VERSION "2021.24.4"

NS_ :

BS_:

BU_: VEH CH Receiver X

BO_ 869 SCS_alertMatrix1: 8 VEH
 SG_ SCS_a001_hwDSPfault: 0|1@1+ (1,0) [0|0] "" X
 SG_ SCS_a002_hwIbatOC: 1|1@1+ (1,0) [0|0] "" X
 SG_ SCS_a003_hwCordOT: 2|1@1+ (1,0) [0|0] "" X
 SG_ SCS_a004_hwVbusOV: 3|1@1+ (1,0) [0|0] "" X
 SG_ SCS_a005_hwHVIL: 4|1@1+ (1,0) [0|0] "" X
 SG_ SCS_a006_hwWeld_V1: 5|1@1+ (1,0) [0|0] "" X
 SG_ SCS_a007_hwWeld_V2: 6|1@1+ (1,0) [0|0] "" X
 SG_ SCS_a008_hwOpen_V1: 7|1@1+ (1,0) [0|0] "" X
 SG_ SCS_a009_hwOpen_V2: 8|1@1+ (1,0) [0|0] "" X
 SG_ SCS_a010_hwIllegalCntrCmdV1: 9|1@1+ (1,0) [0|0] "" X
 SG_ SCS_a011_hwIllegalCntrCmdInt: 10|1@1+ (1,0) [0|0] "" X
 SG_ SCS_a012_hwIllegalCntrCmdV2: 11|1@1+ (1,0) [0|0] "" X
 SG_ SCS_a013_cordTempHiFoldBk: 12|1@1+ (1,0) [0|0] "" X
 SG_ SCS_a014_coolantTempHiFoldBk: 13|1@1+ (1,0) [0|0] "" X
 SG_ SCS_a015_unusedHW15: 14|1@1+ (1,0) [0|0] "" X
 SG_ SCS_a016_unusedHW16: 15|1@1+ (1,0) [0|0] "" X
 SG_ SCS_a017_unusedHW17: 16|1@1+ (1,0) [0|0] "" X
 SG_ SCS_a018_unusedHW18: 17|1@1+ (1,0) [0|0] "" X
 SG_ SCS_a019_unusedHW19: 18|1@1+ (1,0) [0|0] "" X
 SG_ SCS_a020_unusedHW20: 19|1@1+ (1,0) [0|0] "" X
 SG_ SCS_a021_unusedHW21: 20|1@1+ (1,0) [0|0] "" X
 SG_ SCS_a022_fastChargeLimitActiveV1: 21|1@1+ (1,0) [0|0] "" X
 SG_ SCS_a023_fastChargeLimitActiveV2: 22|1@1+ (1,0) [0|0] "" X
 SG_ SCS_a024_emergencyShutdown: 23|1@1+ (1,0) [0|0] "" X
 SG_ SCS_a025_internalIsolationFault: 24|1@1+ (1,0) [0|0] "" X
 SG_ SCS_a026_internalIsolationLow: 25|1@1+ (1,0) [0|0] "" X
 SG_ SCS_a027_externalIsolationLow: 26|1@1+ (1,0) [0|0] "" X
 SG_ SCS_a028_isolationRationality: 27|1@1+ (1,0) [0|0] "" X
 SG_ SCS_a029_VbatOV: 28|1@1+ (1,0) [0|0] "" X
 SG_ SCS_a030_VbusOV: 29|1@1+ (1,0) [0|0] "" X
 SG_ SCS_a031_IbatOC: 30|1@1+ (1,0) [0|0] "" X
 SG_ SCS_a032_VBatRationality: 31|1@1+ (1,0) [0|0] "" X
 SG_ SCS_a033_VBusRationality: 32|1@1+ (1,0) [0|0] "" X
 SG_ SCS_a034_IBatRationality: 33|1@1+ (1,0) [0|0] "" X
 SG_ SCS_a035_unexpectedVbusBehavior: 34|1@1+ (1,0) [0|0] "" X
 SG_ SCS_a036_internalContactorWelded: 35|1@1+ (1,0) [0|0] "" X
 SG_ SCS_a037_outputContactorWelded: 36|1@1+ (1,0) [0|0] "" X
 SG_ SCS_a038_contactorFailedOpen: 37|1@1+ (1,0) [0|0] "" X
 SG_ SCS_a039_ibatRegulation: 38|1@1+ (1,0) [0|0] "" X
 SG_ SCS_a040_plus12VOutOfRange: 39|1@1+ (1,0) [0|0] "" X
 SG_ SCS_a041_minus12VOutOfRange: 40|1@1+ (1,0) [0|0] "" X
 SG_ SCS_a042_pilotOutOfRange: 41|1@1+ (1,0) [0|0] "" X
 SG_ SCS_a043_pilotRationality: 42|1@1+ (1,0) [0|0] "" X
 SG_ SCS_a044_proximityRationality: 43|1@1+ (1,0) [0|0] "" X
 SG_ SCS_a045_pcbaOT: 44|1@1+ (1,0) [0|0] "" X
 SG_ SCS_a046_coolantOT: 45|1@1+ (1,0) [0|0] "" X
 SG_ SCS_a047_cordOT: 46|1@1+ (1,0) [0|0] "" X
 SG_ SCS_a048_ambientOT: 47|1@1+ (1,0) [0|0] "" X
 SG_ SCS_a049_pcbaTempRationality: 48|1@1+ (1,0) [0|0] "" X
 SG_ SCS_a050_coolantTempRationality: 49|1@1+ (1,0) [0|0] "" X
 SG_ SCS_a051_cordTempRationality: 50|1@1+ (1,0) [0|0] "" X
 SG_ SCS_a052_ambientTempRationality: 51|1@1+ (1,0) [0|0] "" X
 SG_ SCS_a053_unexpectedThermalBehavi: 52|1@1+ (1,0) [0|0] "" X
 SG_ SCS_a054_pumpRegulation: 53|1@1+ (1,0) [0|0] "" X
 SG_ SCS_a055_coolantLevelLow: 54|1@1+ (1,0) [0|0] "" X
 SG_ SCS_a056_stateTransitionDenied: 55|1@1+ (1,0) [0|0] "" X
 SG_ SCS_a057_watchdogReset: 56|1@1+ (1,0) [0|0] "" X
 SG_ SCS_a058_adcRef: 57|1@1+ (1,0) [0|0] "" X
 SG_ SCS_a059_memoryError: 58|1@1+ (1,0) [0|0] "" X
 SG_ SCS_a060_swHVIL: 59|1@1+ (1,0) [0|0] "" X
 SG_ SCS_a061_postOutOfService: 60|1@1+ (1,0) [0|0] "" X
 SG_ SCS_a062_unused: 61|1@1+ (1,0) [0|0] "" X
 SG_ SCS_a063_canRationality: 62|1@1+ (1,0) [0|0] "" X
 SG_ SCS_a064_vehicleCommandTimeout: 63|1@1+ (1,0) [0|0] "" X

BO_ 880 SCS_alertMatrix2: 8 CH
 SG_ SCS_a065_vBatRationalityStage1: 0|1@1+ (1,0) [0|0] "" X
 SG_ SCS_a066_vBatRationalityStage2: 1|1@1+ (1,0) [0|0] "" X
 SG_ SCS_a067_vBatRationalityStage3: 2|1@1+ (1,0) [0|0] "" X
 SG_ SCS_a068_vBatRationalityStage4: 3|1@1+ (1,0) [0|0] "" X
 SG_ SCS_a069_vStageRationalityV1: 4|1@1+ (1,0) [0|0] "" X
 SG_ SCS_a070_vStageRationalityV2: 5|1@1+ (1,0) [0|0] "" X
 SG_ SCS_a071_chargerMIA: 6|1@1+ (1,0) [0|0] "" X
 SG_ SCS_a072_gtwMIA: 7|1@1+ (1,0) [0|0] "" X
 SG_ SCS_a073_lccMIA: 8|1@1+ (1,0) [0|0] "" X
 SG_ SCS_a074_isoVDiffHi: 9|1@1+ (1,0) [0|0] "" X
 SG_ SCS_a075_leakageTestAbsDecayLow: 10|1@1+ (1,0) [0|0] "" X
 SG_ SCS_a076_bmsMIA: 11|1@1+ (1,0) [0|0] "" X
 SG_ SCS_a077_unexpectedVbatBehavior: 12|1@1+ (1,0) [0|0] "" X
 SG_ SCS_a078_voltageMatchTimeout: 13|1@1+ (1,0) [0|0] "" X
 SG_ SCS_a079_unexpectedVbat: 14|1@1+ (1,0) [0|0] "" X
 SG_ SCS_a080_lccFaulted: 15|1@1+ (1,0) [0|0] "" X
 SG_ SCS_a081_rmsInputVoltageHigh: 16|1@1+ (1,0) [0|0] "" X
 SG_ SCS_a082_VbatUV: 17|1@1+ (1,0) [0|0] "" X
 SG_ SCS_a083_chargeCurrentLimited: 18|1@1+ (1,0) [0|0] "" X
 SG_ SCS_a084_unused84: 19|1@1+ (1,0) [0|0] "" X
 SG_ SCS_a085_unused85: 20|1@1+ (1,0) [0|0] "" X
 SG_ SCS_a086_lccResetDetected: 21|1@1+ (1,0) [0|0] "" X
 SG_ SCS_a087_posCordTempRationality: 22|1@1+ (1,0) [0|0] "" X
 SG_ SCS_a088_negCordTempRationality: 23|1@1+ (1,0) [0|0] "" X
 SG_ SCS_a089_posCordOT: 24|1@1+ (1,0) [0|0] "" X
 SG_ SCS_a090_negCordOT: 25|1@1+ (1,0) [0|0] "" X
 SG_ SCS_a091_voltageRiseDetection: 26|1@1+ (1,0) [0|0] "" X
 SG_ SCS_a092_cabEnableDeasserted: 27|1@1+ (1,0) [0|0] "" X
 SG_ SCS_a093_unused93: 28|1@1+ (1,0) [0|0] "" X
 SG_ SCS_a094_unused94: 29|1@1+ (1,0) [0|0] "" X
 SG_ SCS_a095_unused95: 30|1@1+ (1,0) [0|0] "" X
 SG_ SCS_a096_unused96: 31|1@1+ (1,0) [0|0] "" X
 SG_ SCS_a097_unused97: 32|1@1+ (1,0) [0|0] "" X
 SG_ SCS_a098_unused98: 33|1@1+ (1,0) [0|0] "" X
 SG_ SCS_a099_unused99: 34|1@1+ (1,0) [0|0] "" X
 SG_ SCS_a100_unused100: 35|1@1+ (1,0) [0|0] "" X
 SG_ SCS_a101_unused101: 36|1@1+ (1,0) [0|0] "" X
 SG_ SCS_a102_unused102: 37|1@1+ (1,0) [0|0] "" X
 SG_ SCS_a103_unused103: 38|1@1+ (1,0) [0|0] "" X
 SG_ SCS_a104_unused104: 39|1@1+ (1,0) [0|0] "" X
 SG_ SCS_a105_unused105: 40|1@1+ (1,0) [0|0] "" X
 SG_ SCS_a106_unused106: 41|1@1+ (1,0) [0|0] "" X
 SG_ SCS_a107_unused107: 42|1@1+ (1,0) [0|0] "" X
 SG_ SCS_a108_unused108: 43|1@1+ (1,0) [0|0] "" X
 SG_ SCS_a109_unused109: 44|1@1+ (1,0) [0|0] "" X
 SG_ SCS_a110_unused110: 45|1@1+ (1,0) [0|0] "" X
 SG_ SCS_a111_unused111: 46|1@1+ (1,0) [0|0] "" X
 SG_ SCS_a112_unused112: 47|1@1+ (1,0) [0|0] "" X
 SG_ SCS_a113_unused113: 48|1@1+ (1,0) [0|0] "" X
 SG_ SCS_a114_unused114: 49|1@1+ (1,0) [0|0] "" X
 SG_ SCS_a115_unused115: 50|1@1+ (1,0) [0|0] "" X
 SG_ SCS_a116_unused116: 51|1@1+ (1,0) [0|0] "" X
 SG_ SCS_a117_unused117: 52|1@1+ (1,0) [0|0] "" X
 SG_ SCS_a118_unused118: 53|1@1+ (1,0) [0|0] "" X
 SG_ SCS_a119_unused119: 54|1@1+ (1,0) [0|0] "" X
 SG_ SCS_a120_unused120: 55|1@1+ (1,0) [0|0] "" X
 SG_ SCS_a121_unused121: 56|1@1+ (1,0) [0|0] "" X
 SG_ SCS_a122_unused122: 57|1@1+ (1,0) [0|0] "" X
 SG_ SCS_a123_unused123: 58|1@1+ (1,0) [0|0] "" X
 SG_ SCS_a124_unused124: 59|1@1+ (1,0) [0|0] "" X
 SG_ SCS_a125_unused125: 60|1@1+ (1,0) [0|0] "" X
 SG_ SCS_a126_unused126: 61|1@1+ (1,0) [0|0] "" X
 SG_ SCS_a127_unused127: 62|1@1+ (1,0) [0|0] "" X
 SG_ SCS_a128_unused128: 63|1@1+ (1,0) [0|0] "" X

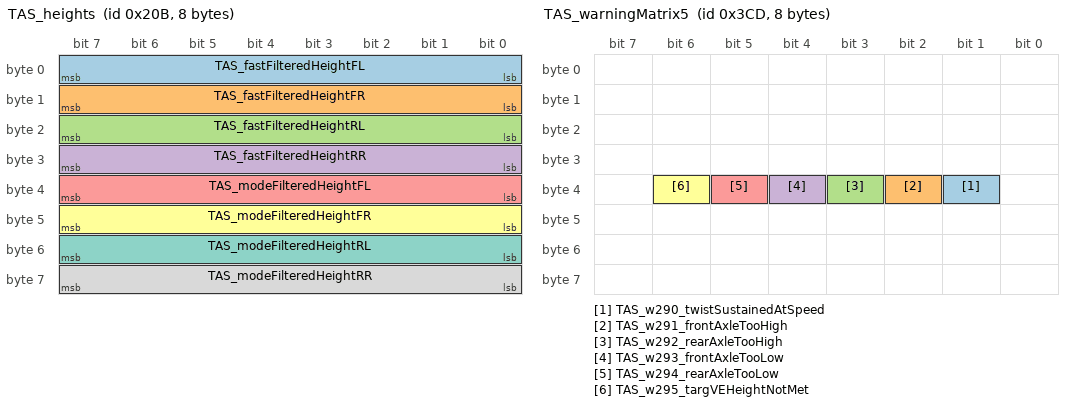
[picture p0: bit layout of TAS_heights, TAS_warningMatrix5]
BO_ 523 TAS_heights: 8 VEH
 SG_ TAS_fastFilteredHeightFL: 0|8@1+ (1,-128) [0|0] "mm" X
 SG_ TAS_fastFilteredHeightFR: 8|8@1+ (1,-128) [0|0] "mm" X
 SG_ TAS_fastFilteredHeightRL: 16|8@1+ (1,-128) [0|0] "mm" X
 SG_ TAS_fastFilteredHeightRR: 24|8@1+ (1,-128) [0|0] "mm" X
 SG_ TAS_modeFilteredHeightFL: 32|8@1+ (1,-128) [0|0] "mm" X
 SG_ TAS_modeFilteredHeightFR: 40|8@1+ (1,-128) [0|0] "mm" X
 SG_ TAS_modeFilteredHeightRL: 48|8@1+ (1,-128) [0|0] "mm" X
 SG_ TAS_modeFilteredHeightRR: 56|8@1+ (1,-128) [0|0] "mm" X

BO_ 1357 TAS_info: 8 VEH
 SG_ TAS_infoIndex M: 0|8@1+ (1,0) [0|0] "" X
 SG_ TAS_infoBuildType m10: 8|3@1+ (1,0) [0|0] "" X
 SG_ TAS_infoBuildConfigId m10: 16|16@1+ (1,0) [0|0] "" X
 SG_ TAS_infoHardwareId m10: 32|1@1+ (1,0) [0|0] "" X
 SG_ TAS_infoComponentId m10: 48|16@1+ (1,0) [0|0] "" X
 SG_ TAS_infoPcbaId m11: 16|8@1+ (1,0) [0|0] "" X
 SG_ TAS_infoAssemblyId m11: 24|8@1+ (1,0) [0|0] "" X
 SG_ TAS_infoUsageId m11: 32|16@1+ (1,0) [0|0] "" X
 SG_ TAS_infoSubUsageId m11: 48|16@1+ (1,0) [0|0] "" X
 SG_ TAS_infoAppCrc m13: 32|32@1+ (1,0) [0|0] "" X
 SG_ TAS_infoBootloaderSvnRevision m14: 8|24@1+ (1,0) [0|0] "" X
 SG_ TAS_infoAppGitHash m17: 10|54@1+ (4,0) [0|0] "" X
 SG_ TAS_infoBootGitHash m18: 10|54@1+ (4,0) [0|0] "" X
 SG_ TAS_infoPlatformType m19: 8|8@1+ (1,0) [0|0] "" X
 SG_ TAS_infoMajorVersion m19: 16|8@1+ (1,0) [0|0] "" X
 SG_ TAS_infoBranchOrigin m19: 24|8@1+ (1,0) [0|0] "" X
 SG_ TAS_infoMaturity m19: 32|8@1+ (1,0) [0|0] "" X
 SG_ TAS_infoHardwareRevision m19: 40|8@1+ (1,0) [0|0] "" X
 SG_ TAS_infoBootUdsProtoVersion m20: 8|8@1+ (1,0) [0|0] "" X
 SG_ TAS_infoBootCrc m20: 32|32@1+ (1,0) [0|0] "" X

BO_ 525 TAS_states: 8 VEH
 SG_ TAS_compressorRun: 30|1@1+ (1,0) [0|0] "" X
 SG_ TAS_currentLevel: 42|3@1+ (1,0) [0|0] "" X
 SG_ TAS_filterMode: 27|3@1+ (1,0) [0|0] "" X
 SG_ TAS_highAllowed: 36|1@1+ (1,0) [0|0] "" X
 SG_ TAS_jackMode: 38|1@1+ (1,0) [0|0] "" X
 SG_ TAS_leanDetected: 32|1@1+ (1,0) [0|0] "" X
 SG_ TAS_levelingState: 0|4@1+ (1,0) [0|0] "" X
 SG_ TAS_levelingType: 4|4@1+ (1,0) [0|0] "" X
 SG_ TAS_limpHomeMode: 48|3@1+ (1,0) [0|0] "" X
 SG_ TAS_lowAllowed: 34|1@1+ (1,0) [0|0] "" X
 SG_ TAS_pressureGallery: 8|8@1+ (0.1,0) [0|0] "bar" X
 SG_ TAS_pressureReservoir: 16|8@1+ (0.1,0) [0|0] "bar" X
 SG_ TAS_redWarningLamp: 40|1@1+ (1,0) [0|0] "" X
 SG_ TAS_runMode: 24|3@1+ (1,0) [0|0] "" X
 SG_ TAS_spinnerUI: 41|1@1+ (1,0) [0|0] "" X
 SG_ TAS_standardAllowed: 35|1@1+ (1,0) [0|0] "" X
 SG_ TAS_statesChecksum: 56|8@1+ (1,0) [0|0] "" X
 SG_ TAS_statesCounter: 52|4@1+ (1,0) [0|0] "" X
 SG_ TAS_targetLevel: 45|3@1+ (1,0) [0|0] "" X
 SG_ TAS_twistDetected: 31|1@1+ (1,0) [0|0] "" X
 SG_ TAS_veryHighAllowed: 37|1@1+ (1,0) [0|0] "" X
 SG_ TAS_veryLowAllowed: 33|1@1+ (1,0) [0|0] "" X
 SG_ TAS_yellowWarningLamp: 39|1@1+ (1,0) [0|0] "" X

BO_ 845 TAS_warningMatrix1: 8 VEH
 SG_ TAS_w001_WatchdogReset: 0|1@1+ (1,0) [0|0] "" X
 SG_ TAS_w002_PowerLossReset: 1|1@1+ (1,0) [0|0] "" X
 SG_ TAS_w003_SWAssertion: 2|1@1+ (1,0) [0|0] "" X
 SG_ TAS_w004_CANMIA: 3|1@1+ (1,0) [0|0] "" X
 SG_ TAS_w005_CANHighError: 4|1@1+ (1,0) [0|0] "" X
 SG_ TAS_w006_CANLowError: 5|1@1+ (1,0) [0|0] "" X
 SG_ TAS_w007_LINTimeout: 6|1@1+ (1,0) [0|0] "" X
 SG_ TAS_w008_LIN2Error: 7|1@1+ (1,0) [0|0] "" X
 SG_ TAS_w009_LIN3Error: 8|1@1+ (1,0) [0|0] "" X
 SG_ TAS_w010_ExtSupplyVoltError: 9|1@1+ (1,0) [0|0] "" X
 SG_ TAS_w011_ECUSupplyVoltError: 10|1@1+ (1,0) [0|0] "" X
 SG_ TAS_w012_CPUReset: 11|1@1+ (1,0) [0|0] "" X
 SG_ TAS_w013_Shared13: 12|1@1+ (1,0) [0|0] "" X
 SG_ TAS_w014_BridgeFault: 13|1@1+ (1,0) [0|0] "" X
 SG_ TAS_w015_NVMMAlert: 14|1@1+ (1,0) [0|0] "" X
 SG_ TAS_w016_MessageTimingError: 15|1@1+ (1,0) [0|0] "" X
 SG_ TAS_w017_AwakeForTooLong: 16|1@1+ (1,0) [0|0] "" X
 SG_ TAS_w018_ADCError: 17|1@1+ (1,0) [0|0] "" X
 SG_ TAS_w019_I2CError: 18|1@1+ (1,0) [0|0] "" X
 SG_ TAS_w020_PWMError: 19|1@1+ (1,0) [0|0] "" X
 SG_ TAS_w021_TaskSchedulerError: 20|1@1+ (1,0) [0|0] "" X
 SG_ TAS_w022_TaskInitError: 21|1@1+ (1,0) [0|0] "" X
 SG_ TAS_w023_SleepError: 22|1@1+ (1,0) [0|0] "" X
 SG_ TAS_w024_WakeError: 23|1@1+ (1,0) [0|0] "" X
 SG_ TAS_w025_CrashEvent: 24|1@1+ (1,0) [0|0] "" X
 SG_ TAS_w026_FlashMemoryError: 25|1@1+ (1,0) [0|0] "" X
 SG_ TAS_w027_NVRAMCorruption: 26|1@1+ (1,0) [0|0] "" X
 SG_ TAS_w028_NVRAMNotResponding: 27|1@1+ (1,0) [0|0] "" X
 SG_ TAS_w029_NVRAMUninitialized: 28|1@1+ (1,0) [0|0] "" X
 SG_ TAS_w030_PWMerrorFL: 29|1@1+ (1,0) [0|0] "" X
 SG_ TAS_w031_PWMerrorFR: 30|1@1+ (1,0) [0|0] "" X
 SG_ TAS_w032_PWMerrorRL: 31|1@1+ (1,0) [0|0] "" X
 SG_ TAS_w033_PWMerrorRR: 32|1@1+ (1,0) [0|0] "" X
 SG_ TAS_w034_PWMshortFL: 33|1@1+ (1,0) [0|0] "" X
 SG_ TAS_w035_PWMshortFR: 34|1@1+ (1,0) [0|0] "" X
 SG_ TAS_w036_PWMshortRL: 35|1@1+ (1,0) [0|0] "" X
 SG_ TAS_w037_PWMshortRR: 36|1@1+ (1,0) [0|0] "" X
 SG_ TAS_w038_PWMopenFL: 37|1@1+ (1,0) [0|0] "" X
 SG_ TAS_w039_PWMopenFR: 38|1@1+ (1,0) [0|0] "" X
 SG_ TAS_w040_PWMopenRL: 39|1@1+ (1,0) [0|0] "" X
 SG_ TAS_w041_PWMopenRR: 40|1@1+ (1,0) [0|0] "" X

BO_ 877 TAS_warningMatrix2: 8 VEH
 SG_ TAS_w070_lowVoltage12V: 5|1@1+ (1,0) [0|0] "" X
 SG_ TAS_w071_highVoltage12V: 6|1@1+ (1,0) [0|0] "" X
 SG_ TAS_w072_shortCircuit5VS0: 7|1@1+ (1,0) [0|0] "" X
 SG_ TAS_w073_lowVoltage5VS0: 8|1@1+ (1,0) [0|0] "" X
 SG_ TAS_w074_shortCircuit5VS1: 9|1@1+ (1,0) [0|0] "" X
 SG_ TAS_w075_lowVoltage5VS1: 10|1@1+ (1,0) [0|0] "" X
 SG_ TAS_w076_highVoltage5VS1: 11|1@1+ (1,0) [0|0] "" X
 SG_ TAS_w077_pressureSigVTooLow: 12|1@1+ (1,0) [0|0] "" X
 SG_ TAS_w078_pressureSigVTooHigh: 13|1@1+ (1,0) [0|0] "" X
 SG_ TAS_w079_DvrSideCfgMismatch: 14|1@1+ (1,0) [0|0] "" X
 SG_ TAS_w080_pressureRefVTooLow: 15|1@1+ (1,0) [0|0] "" X
 SG_ TAS_w093_OTPError: 28|1@1+ (1,0) [0|0] "" X
 SG_ TAS_w098_VCFRONT_MIA: 33|1@1+ (1,0) [0|0] "" X
 SG_ TAS_w099_UI_MIA: 34|1@1+ (1,0) [0|0] "" X
 SG_ TAS_w100_RCM_MIA: 35|1@1+ (1,0) [0|0] "" X
 SG_ TAS_w101_ESP_MIA: 36|1@1+ (1,0) [0|0] "" X
 SG_ TAS_w102_DI_MIA: 37|1@1+ (1,0) [0|0] "" X
 SG_ TAS_w103_GTW_MIA: 38|1@1+ (1,0) [0|0] "" X
 SG_ TAS_w105_ECUDebugMode: 40|1@1+ (1,0) [0|0] "" X
 SG_ TAS_w106_HighCPULoad: 41|1@1+ (1,0) [0|0] "" X
 SG_ TAS_w107_HighStackUsage: 42|1@1+ (1,0) [0|0] "" X
 SG_ TAS_w121_maxDutyFL: 56|1@1+ (1,0) [0|0] "" X
 SG_ TAS_w122_maxDutyFR: 57|1@1+ (1,0) [0|0] "" X
 SG_ TAS_w123_maxDutyRL: 58|1@1+ (1,0) [0|0] "" X
 SG_ TAS_w124_maxDutyRR: 59|1@1+ (1,0) [0|0] "" X
 SG_ TAS_w125_maxDutyReservoir: 60|1@1+ (1,0) [0|0] "" X
 SG_ TAS_w126_maxDutyExhaust: 61|1@1+ (1,0) [0|0] "" X
 SG_ TAS_w127_maxDutyBoost: 62|1@1+ (1,0) [0|0] "" X
 SG_ TAS_w128_maxDutyCompressor: 63|1@1+ (1,0) [0|0] "" X

BO_ 909 TAS_warningMatrix3: 8 VEH
 SG_ TAS_w129_openCircuitFL: 0|1@1+ (1,0) [0|0] "" X
 SG_ TAS_w130_openCircuitFR: 1|1@1+ (1,0) [0|0] "" X
 SG_ TAS_w131_openCircuitRL: 2|1@1+ (1,0) [0|0] "" X
 SG_ TAS_w132_openCircuitRR: 3|1@1+ (1,0) [0|0] "" X
 SG_ TAS_w133_openCircuitReservoir: 4|1@1+ (1,0) [0|0] "" X
 SG_ TAS_w134_openCircuitExhaust: 5|1@1+ (1,0) [0|0] "" X
 SG_ TAS_w135_openCircuitBoost: 6|1@1+ (1,0) [0|0] "" X
 SG_ TAS_w136_openCircuitCompressor: 7|1@1+ (1,0) [0|0] "" X
 SG_ TAS_w137_shortCircuitFL: 8|1@1+ (1,0) [0|0] "" X
 SG_ TAS_w138_shortCircuitFR: 9|1@1+ (1,0) [0|0] "" X
 SG_ TAS_w139_shortCircuitRL: 10|1@1+ (1,0) [0|0] "" X
 SG_ TAS_w140_shortCircuitRR: 11|1@1+ (1,0) [0|0] "" X
 SG_ TAS_w141_shortCircuitReservoir: 12|1@1+ (1,0) [0|0] "" X
 SG_ TAS_w142_shortCircuitExhaust: 13|1@1+ (1,0) [0|0] "" X
 SG_ TAS_w143_shortCircuitBoost: 14|1@1+ (1,0) [0|0] "" X
 SG_ TAS_w144_shortCircuitCompressor: 15|1@1+ (1,0) [0|0] "" X
 SG_ TAS_w145_boardFaultFL: 16|1@1+ (1,0) [0|0] "" X
 SG_ TAS_w146_boardFaultFR: 17|1@1+ (1,0) [0|0] "" X
 SG_ TAS_w147_boardFaultRL: 18|1@1+ (1,0) [0|0] "" X
 SG_ TAS_w148_boardFaultRR: 19|1@1+ (1,0) [0|0] "" X
 SG_ TAS_w149_boardFaultReservoir: 20|1@1+ (1,0) [0|0] "" X
 SG_ TAS_w150_boardFaultExhaust: 21|1@1+ (1,0) [0|0] "" X
 SG_ TAS_w151_boardFaultBoost: 22|1@1+ (1,0) [0|0] "" X
 SG_ TAS_w152_boardFaultCompressor: 23|1@1+ (1,0) [0|0] "" X
 SG_ TAS_w153_otherCircuitFL: 24|1@1+ (1,0) [0|0] "" X
 SG_ TAS_w154_otherCircuitFR: 25|1@1+ (1,0) [0|0] "" X
 SG_ TAS_w155_otherCircuitRL: 26|1@1+ (1,0) [0|0] "" X
 SG_ TAS_w156_otherCircuitRR: 27|1@1+ (1,0) [0|0] "" X
 SG_ TAS_w157_otherCircuitReservoir: 28|1@1+ (1,0) [0|0] "" X
 SG_ TAS_w158_otherCircuitExhaust: 29|1@1+ (1,0) [0|0] "" X
 SG_ TAS_w159_otherCircuitBoost: 30|1@1+ (1,0) [0|0] "" X
 SG_ TAS_w160_otherCircuitCompressor: 31|1@1+ (1,0) [0|0] "" X
 SG_ TAS_w161_valveBlockOpenGND: 32|1@1+ (1,0) [0|0] "" X
 SG_ TAS_w162_compressorValveOpenGND: 33|1@1+ (1,0) [0|0] "" X
 SG_ TAS_w163_reservoirFillDisabled: 34|1@1+ (1,0) [0|0] "" X
 SG_ TAS_w164_calibrationVersion: 35|1@1+ (1,0) [0|0] "" X

BO_ 941 TAS_warningMatrix4: 8 VEH
 SG_ TAS_w200_jackModeActive: 7|1@1+ (1,0) [0|0] "" X
 SG_ TAS_w201_lowHVBattery: 8|1@1+ (1,0) [0|0] "" X
 SG_ TAS_w210_outOfRangeCalibration: 17|1@1+ (1,0) [0|0] "" X
 SG_ TAS_w211_noRideHeightCalib: 18|1@1+ (1,0) [0|0] "" X
 SG_ TAS_w212_noCurrentSenseCalib: 19|1@1+ (1,0) [0|0] "" X
 SG_ TAS_w213_yellowWarningLamp: 20|1@1+ (1,0) [0|0] "" X
 SG_ TAS_w214_redWarningLamp: 21|1@1+ (1,0) [0|0] "" X
 SG_ TAS_w215_limpHomeMode10: 22|1@1+ (1,0) [0|0] "" X
 SG_ TAS_w216_limpHomeMode20: 23|1@1+ (1,0) [0|0] "" X
 SG_ TAS_w217_limpHomeMode30: 24|1@1+ (1,0) [0|0] "" X
 SG_ TAS_w218_limpHomeMode40: 25|1@1+ (1,0) [0|0] "" X
 SG_ TAS_w220_exhaustGalleryFault: 27|1@1+ (1,0) [0|0] "" X
 SG_ TAS_w221_valveLeakDetected: 28|1@1+ (1,0) [0|0] "" X
 SG_ TAS_w222_compressorPrefillFault: 29|1@1+ (1,0) [0|0] "" X
 SG_ TAS_w223_blockedAirline: 30|1@1+ (1,0) [0|0] "" X
 SG_ TAS_w224_openAirline: 31|1@1+ (1,0) [0|0] "" X
 SG_ TAS_w225_galleryPressureTooHigh: 32|1@1+ (1,0) [0|0] "" X
 SG_ TAS_w226_PWMfastDetectFL: 33|1@1+ (1,0) [0|0] "" X
 SG_ TAS_w227_PWMfastDetectFR: 34|1@1+ (1,0) [0|0] "" X
 SG_ TAS_w228_PWMfastDetectRL: 35|1@1+ (1,0) [0|0] "" X
 SG_ TAS_w229_PWMfastDetectRR: 36|1@1+ (1,0) [0|0] "" X

BO_ 973 TAS_warningMatrix5: 8 VEH
 SG_ TAS_w290_twistSustainedAtSpeed: 33|1@1+ (1,0) [0|0] "" X
 SG_ TAS_w291_frontAxleTooHigh: 34|1@1+ (1,0) [0|0] "" X
 SG_ TAS_w292_rearAxleTooHigh: 35|1@1+ (1,0) [0|0] "" X
 SG_ TAS_w293_frontAxleTooLow: 36|1@1+ (1,0) [0|0] "" X
 SG_ TAS_w294_rearAxleTooLow: 37|1@1+ (1,0) [0|0] "" X
 SG_ TAS_w295_targVEHeightNotMet: 38|1@1+ (1,0) [0|0] "" X

BO_ 879 TPMS_StatusC: 8 CH
 SG_ TPMS_WA_version: 3|1@1+ (1,0) [0|0] "" X
 SG_ TPMS_c_globalHardWarning: 0|1@1+ (1,0) [0|0] "" X
 SG_ TPMS_c_globalSoftWarning: 1|1@1+ (1,0) [0|0] "" X
 SG_ TPMS_deltaPressWarningFL: 20|1@1+ (1,0) [0|0] "" X
 SG_ TPMS_deltaPressWarningFR: 21|1@1+ (1,0) [0|0] "" X
 SG_ TPMS_deltaPressWarningRL: 22|1@1+ (1,0) [0|0] "" X
 SG_ TPMS_deltaPressWarningRR: 23|1@1+ (1,0) [0|0] "" X
 SG_ TPMS_ecuOverVoltage: 41|1@1+ (1,0) [0|0] "" X
 SG_ TPMS_ecuRamRomNvMFail: 42|1@1+ (1,0) [0|0] "" X
 SG_ TPMS_ecuUnderVoltage: 40|1@1+ (1,0) [0|0] "" X
 SG_ TPMS_eolNotCompleted: 47|1@1+ (1,0) [0|0] "" X
 SG_ TPMS_externalTemperatureFail: 46|1@1+ (1,0) [0|0] "" X
 SG_ TPMS_globalDeltaPressure: 4|1@1+ (1,0) [0|0] "" X
 SG_ TPMS_hardWarningFL: 15|1@1+ (1,0) [0|0] "" X
 SG_ TPMS_hardWarningFR: 13|1@1+ (1,0) [0|0] "" X
 SG_ TPMS_hardWarningRL: 11|1@1+ (1,0) [0|0] "" X
 SG_ TPMS_hardWarningRR: 9|1@1+ (1,0) [0|0] "" X
 SG_ TPMS_learningStatus: 16|2@1+ (1,0) [0|0] "" X
 SG_ TPMS_localisationStatus: 18|2@1+ (1,0) [0|0] "" X
 SG_ TPMS_newSensorLearnt: 5|3@1+ (1,0) [0|0] "" X
 SG_ TPMS_rcpFront: 48|8@1+ (0.025,0) [0|0] "bar" X
 SG_ TPMS_rcpRear: 56|8@1+ (0.025,0) [0|0] "bar" X
 SG_ TPMS_rfReceiverFail: 43|1@1+ (1,0) [0|0] "" X
 SG_ TPMS_sensorBatteryLowFL: 32|1@1+ (1,0) [0|0] "" X
 SG_ TPMS_sensorBatteryLowFR: 33|1@1+ (1,0) [0|0] "" X
 SG_ TPMS_sensorBatteryLowRL: 34|1@1+ (1,0) [0|0] "" X
 SG_ TPMS_sensorBatteryLowRR: 35|1@1+ (1,0) [0|0] "" X
 SG_ TPMS_sensorDefectiveFL: 36|1@1+ (1,0) [0|0] "" X
 SG_ TPMS_sensorDefectiveFR: 37|1@1+ (1,0) [0|0] "" X
 SG_ TPMS_sensorDefectiveRL: 38|1@1+ (1,0) [0|0] "" X
 SG_ TPMS_sensorDefectiveRR: 39|1@1+ (1,0) [0|0] "" X
 SG_ TPMS_sensorNoResponseFL: 24|1@1+ (1,0) [0|0] "" X
 SG_ TPMS_sensorNoResponseFR: 25|1@1+ (1,0) [0|0] "" X
 SG_ TPMS_sensorNoResponseRL: 26|1@1+ (1,0) [0|0] "" X
 SG_ TPMS_sensorNoResponseRR: 27|1@1+ (1,0) [0|0] "" X
 SG_ TPMS_sensorThermShutdownFL: 28|1@1+ (1,0) [0|0] "" X
 SG_ TPMS_sensorThermShutdownFR: 29|1@1+ (1,0) [0|0] "" X
 SG_ TPMS_sensorThermShutdownRL: 30|1@1+ (1,0) [0|0] "" X
 SG_ TPMS_sensorThermShutdownRR: 31|1@1+ (1,0) [0|0] "" X
 SG_ TPMS_softWarningFL: 14|1@1+ (1,0) [0|0] "" X
 SG_ TPMS_softWarningFR: 12|1@1+ (1,0) [0|0] "" X
 SG_ TPMS_softWarningRL: 10|1@1+ (1,0) [0|0] "" X
 SG_ TPMS_softWarningRR: 8|1@1+ (1,0) [0|0] "" X
 SG_ TPMS_systemMalfunction: 2|1@1+ (1,0) [0|0] "" X
 SG_ TPMS_vehicleSpeedFail: 45|1@1+ (1,0) [0|0] "" X
 SG_ TPMS_wheelPulseMissing: 44|1@1+ (1,0) [0|0] "" X

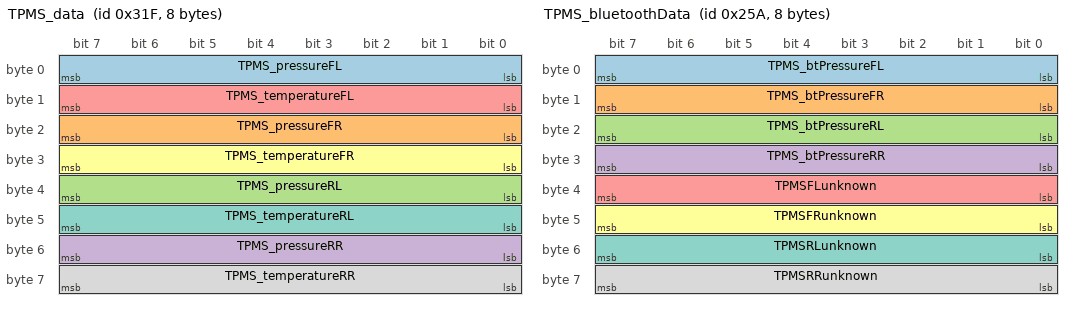
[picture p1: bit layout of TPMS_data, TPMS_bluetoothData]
BO_ 799 TPMS_data: 8 CH
 SG_ TPMS_pressureFL: 0|8@1+ (0.025,0) [0|0] "bar" X
 SG_ TPMS_pressureFR: 16|8@1+ (0.025,0) [0|0] "bar" X
 SG_ TPMS_pressureRL: 32|8@1+ (0.025,0) [0|0] "bar" X
 SG_ TPMS_pressureRR: 48|8@1+ (0.025,0) [0|0] "bar" X
 SG_ TPMS_temperatureFL: 8|8@1+ (1,-40) [0|0] "degC" X
 SG_ TPMS_temperatureFR: 24|8@1+ (1,-40) [0|0] "degC" X
 SG_ TPMS_temperatureRL: 40|8@1+ (1,-40) [0|0] "degC" X
 SG_ TPMS_temperatureRR: 56|8@1+ (1,-40) [0|0] "degC" X

BO_ 602 TPMS_bluetoothData: 8 CH
SG_ TPMS_btPressureFL : 0|8@1+ (0.025,0) [0|6.375] "bar" X
SG_ TPMS_btPressureFR : 8|8@1+ (0.025,0) [0|6.375] "bar" X
SG_ TPMS_btPressureRL : 16|8@1+ (0.025,0) [0|6.375] "bar" X
SG_ TPMS_btPressureRR : 24|8@1+ (0.025,0) [0|6.375] "bar" X
SG_ TPMSFLunknown : 32|8@1+ (1,0) [0|0] "" X
SG_ TPMSFRunknown : 40|8@1+ (1,0) [0|0] "" X
SG_ TPMSRLunknown : 48|8@1+ (1,0) [0|0] "" X
SG_ TPMSRRunknown : 56|8@1+ (1,0) [0|0] "" X

BO_ 1519 TPMS_info: 8 CH
 SG_ TPMS_infoIndex M: 0|8@1+ (1,0) [0|0] "" X
 SG_ TPMS_infoComponentID m10: 48|16@1+ (1,0) [0|0] "" X
 SG_ TPMS_infoPcbaID m11: 16|8@1+ (1,0) [0|0] "" X
 SG_ TPMS_infoAssemblyID m11: 24|8@1+ (1,0) [0|0] "" X
 SG_ TPMS_infoUsageID m11: 32|16@1+ (1,0) [0|0] "" X
 SG_ TPMS_infoBootUdsProtoVersion m20: 8|8@1+ (1,0) [0|0] "" X
 SG_ TPMS_infoBootloaderCRC m20: 32|32@1+ (1,0) [0|0] "" X
 SG_ TPMS_infoApplicationCRC m13: 32|32@1+ (1,0) [0|0] "" X

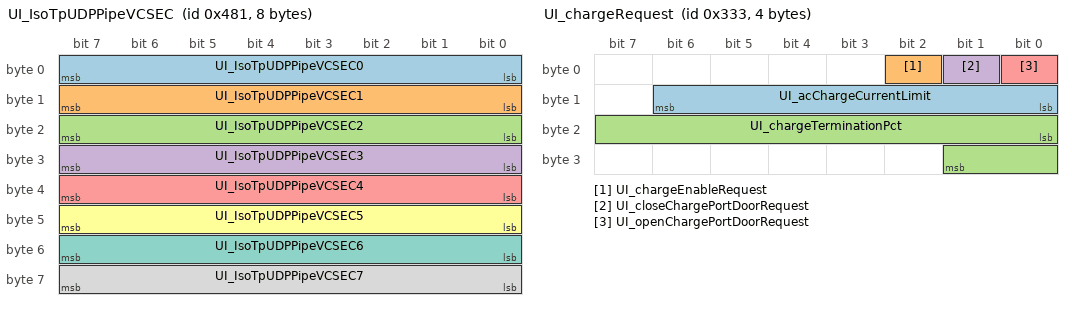
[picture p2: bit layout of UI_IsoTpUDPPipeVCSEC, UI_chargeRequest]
BO_ 1153 UI_IsoTpUDPPipeVCSEC: 8 VEH
 SG_ UI_IsoTpUDPPipeVCSEC0: 0|8@1+ (1,0) [0|0] "" X
 SG_ UI_IsoTpUDPPipeVCSEC1: 8|8@1+ (1,0) [0|0] "" X
 SG_ UI_IsoTpUDPPipeVCSEC2: 16|8@1+ (1,0) [0|0] "" X
 SG_ UI_IsoTpUDPPipeVCSEC3: 24|8@1+ (1,0) [0|0] "" X
 SG_ UI_IsoTpUDPPipeVCSEC4: 32|8@1+ (1,0) [0|0] "" X
 SG_ UI_IsoTpUDPPipeVCSEC5: 40|8@1+ (1,0) [0|0] "" X
 SG_ UI_IsoTpUDPPipeVCSEC6: 48|8@1+ (1,0) [0|0] "" X
 SG_ UI_IsoTpUDPPipeVCSEC7: 56|8@1+ (1,0) [0|0] "" X

BO_ 979 UI_airbagCutoffStatus: 1 VEH
 SG_ UI_airbagCutoffSwState: 0|2@1+ (1,0) [0|0] "" X
 SG_ UI_warningIndicatorStatus: 2|2@1+ (1,0) [0|0] "" X

BO_ 1523 UI_alertLog: 8 VEH
 SG_ UI_alertID M: 0|6@1+ (1,0) [0|0] "" X
 SG_ UI_alertState: 15|1@1+ (1,0) [0|0] "" X
 SG_ UI_a034_BackupCamera m34: 16|1@1+ (1,0) [0|0] "" X
 SG_ UI_a034_Tuner m34: 17|1@1+ (1,0) [0|0] "" X
 SG_ UI_a034_Bluetooth m34: 18|1@1+ (1,0) [0|0] "" X
 SG_ UI_a034_WiFi m34: 19|1@1+ (1,0) [0|0] "" X
 SG_ UI_a034_Cellular m34: 20|1@1+ (1,0) [0|0] "" X
 SG_ UI_a034_TouchScreen m34: 21|1@1+ (1,0) [0|0] "" X
 SG_ UI_a034_Display m34: 22|1@1+ (1,0) [0|0] "" X
 SG_ UI_a034_Audio m34: 23|1@1+ (1,0) [0|0] "" X
 SG_ UI_a034_FatalWakeup m34: 24|1@1+ (1,0) [0|0] "" X
 SG_ UI_a034_UnknownWakeupError m34: 25|1@1+ (1,0) [0|0] "" X
 SG_ UI_a006_remoteServiceAlertCode m6: 16|32@1+ (1,0) [0|0] "" X

BO_ 291 UI_alertMatrix1: 8 VEH
 SG_ UI_a001_DriverDoorOpen: 0|1@1+ (1,0) [0|0] "" X
 SG_ UI_a002_DoorOpen: 1|1@1+ (1,0) [0|0] "" X
 SG_ UI_a003_TrunkOpen: 2|1@1+ (1,0) [0|0] "" X
 SG_ UI_a004_FrunkOpen: 3|1@1+ (1,0) [0|0] "" X
 SG_ UI_a005_HeadlightsOnDoorOpen: 4|1@1+ (1,0) [0|0] "" X
 SG_ UI_a006_RemoteServiceAlert: 5|1@1+ (1,0) [0|0] "" X
 SG_ UI_a007_SoftPackConfigMismatch: 6|1@1+ (1,0) [0|0] "" X
 SG_ UI_a008_TouchScreenError: 7|1@1+ (1,0) [0|0] "" X
 SG_ UI_a009_SquashfsError: 8|1@1+ (1,0) [0|0] "" X
 SG_ UI_a010_MapsMissing: 9|1@1+ (1,0) [0|0] "" X
 SG_ UI_a011_IncorrectMap: 10|1@1+ (1,0) [0|0] "" X
 SG_ UI_a012_NotOnPrivateProperty: 11|1@1+ (1,0) [0|0] "" X
 SG_ UI_a013_TPMSHardWarning: 12|1@1+ (1,0) [0|0] "" X
 SG_ UI_a014_TPMSSoftWarning: 13|1@1+ (1,0) [0|0] "" X
 SG_ UI_a015_TPMSOverPressureWarning: 14|1@1+ (1,0) [0|0] "" X
 SG_ UI_a016_TPMSTemperatureWarning: 15|1@1+ (1,0) [0|0] "" X
 SG_ UI_a017_TPMSSystemFault: 16|1@1+ (1,0) [0|0] "" X
 SG_ UI_a018_SlipStartOn: 17|1@1+ (1,0) [0|0] "" X
 SG_ UI_a019_ParkBrakeFault: 18|1@1+ (1,0) [0|0] "" X
 SG_ UI_a020_SteeringReduced: 19|1@1+ (1,0) [0|0] "" X
 SG_ UI_a021_RearSeatbeltUnbuckled: 20|1@1+ (1,0) [0|0] "" X
 SG_ UI_a022_ApeFusesEtc: 21|1@1+ (1,0) [0|0] "" X
 SG_ UI_a023_CellInternetCheckFailed: 22|1@1+ (1,0) [0|0] "" X
 SG_ UI_a024_WifiInternetCheckFailed: 23|1@1+ (1,0) [0|0] "" X
 SG_ UI_a025_WifiOnlineCheckFailed: 24|1@1+ (1,0) [0|0] "" X
 SG_ UI_a026_ModemResetLoopDetected: 25|1@1+ (1,0) [0|0] "" X
 SG_ UI_a027_AutoSteerMIA: 26|1@1+ (1,0) [0|0] "" X
 SG_ UI_a028_FrontTrunkPopupClosed: 27|1@1+ (1,0) [0|0] "" X
 SG_ UI_a029_ModemMIA: 28|1@1+ (1,0) [0|0] "" X
 SG_ UI_a030_ModemVMCrash: 29|1@1+ (1,0) [0|0] "" X
 SG_ UI_a031_BrakeFluidLow: 30|1@1+ (1,0) [0|0] "" X
 SG_ UI_a032_CellModemRecoveryResets: 31|1@1+ (1,0) [0|0] "" X
 SG_ UI_a033_ApTrialExpired: 32|1@1+ (1,0) [0|0] "" X
 SG_ UI_a034_WakeupProblem: 33|1@1+ (1,0) [0|0] "" X
 SG_ UI_a035_AudioWatchdogKernelError: 34|1@1+ (1,0) [0|0] "" X
 SG_ UI_a036_AudioWatchdogHfpError: 35|1@1+ (1,0) [0|0] "" X
 SG_ UI_a037_AudioWatchdogXrunStormError: 36|1@1+ (1,0) [0|0] "" X
 SG_ UI_a038_AudioWatchdogA2bI2cLockupError: 37|1@1+ (1,0) [0|0] "" X
 SG_ UI_a039_AudioA2bNeedRediscovery: 38|1@1+ (1,0) [0|0] "" X
 SG_ UI_a040_HomelinkTransmit: 39|1@1+ (1,0) [0|0] "" X
 SG_ UI_a041_AudioDmesgXrun: 40|1@1+ (1,0) [0|0] "" X
 SG_ UI_a042_AudioDmesgRtThrottling: 41|1@1+ (1,0) [0|0] "" X
 SG_ UI_a043_InvalidMapDataOverride: 42|1@1+ (1,0) [0|0] "" X
 SG_ UI_a044_AudioDmesgDspException: 43|1@1+ (1,0) [0|0] "" X

BO_ 1021 UI_autopilotControl: 8 CH
 SG_ UI_autopilotControlIndex M : 0|3@1+ (1,0) [0|7] "" X
 SG_ UI_apmv3Branch m1 : 40|3@1+ (1,0) [0|5] "" X
 SG_ UI_applyEceR79 m1 : 19|1@1+ (1,0) [0|1] "" X
 SG_ UI_blindspotDistance m0 : 15|3@1+ (1,0) [0|5] "" X
 SG_ UI_blindspotMinSpeed m0 : 11|4@1+ (1,0) [0|10] "" X
 SG_ UI_blindspotTTC m0 : 18|3@1+ (1,0) [0|7] "" X
 SG_ UI_disableBackup m1 : 30|1@1+ (1,0) [0|1] "" X
 SG_ UI_disableFisheye m1 : 25|1@1+ (1,0) [0|1] "" X
 SG_ UI_disableLeftPillar m1 : 26|1@1+ (1,0) [0|1] "" X
 SG_ UI_disableLeftRepeater m1 : 28|1@1+ (1,0) [0|1] "" X
 SG_ UI_disableMain m1 : 23|1@1+ (1,0) [0|1] "" X
 SG_ UI_disableNarrow m1 : 24|1@1+ (1,0) [0|1] "" X
 SG_ UI_disableRadar m1 : 31|1@1+ (1,0) [0|1] "" X
 SG_ UI_disableRightPillar m1 : 27|1@1+ (1,0) [0|1] "" X
 SG_ UI_disableRightRepeater m1 : 29|1@1+ (1,0) [0|1] "" X
 SG_ UI_donAlcProgGoreAbortThres m0 : 29|4@1+ (1,0) [0|9] "" X
 SG_ UI_donDisableAutoWiperDuration m0 : 4|3@1+ (1,0) [0|6] "" X
 SG_ UI_donDisableCutin m0 : 24|1@1+ (1,0) [0|1] "" X
 SG_ UI_donDisableOnAutoWiperSpeed m0 : 7|4@1+ (1,0) [0|15] "" X
 SG_ UI_donMinGoreWidthForAbortMap m0 : 25|4@1+ (1,0) [0|11] "" X
 SG_ UI_donMinGoreWidthForAbortNotMap m0 : 33|4@1+ (1,0) [0|11] "" X
 SG_ UI_donStopEndOfRampBuffer m0 : 21|3@1+ (1,0) [0|4] "" X
 SG_ UI_driverMonitorConfirmation m1 : 17|1@1+ (1,0) [0|1] "" X
 SG_ UI_enableAutopilotStopWarning m1 : 44|1@1+ (1,0) [0|1] "" X
 SG_ UI_enableCabinCamera m1 : 43|1@1+ (1,0) [0|1] "" X
 SG_ UI_enableCabinCameraTelemetry m1 : 48|1@1+ (1,0) [0|1] "" X
 SG_ UI_enableMapStops m1 : 20|1@1+ (1,0) [0|1] "" X
 SG_ UI_factorySummonEnable m1 : 39|1@1+ (1,0) [0|1] "" X
 SG_ UI_fsdStopsControlEnabled m0 : 38|1@1+ (1,0) [0|1] "" X
 SG_ UI_fsdVisualizationEnabled m0 : 37|1@1+ (1,0) [0|1] "" X
 SG_ UI_hardCoreSummon m1 : 47|1@1+ (1,0) [0|1] "" X
 SG_ UI_homelinkNearby m0 : 45|1@1+ (1,0) [0|1] "" X
 SG_ UI_hovEnabled m0 : 3|1@1+ (1,0) [0|1] "" X
 SG_ UI_noStalkConfirmAlertChime m1 : 37|1@1+ (1,0) [0|1] "" X
 SG_ UI_noStalkConfirmAlertHaptic m1 : 32|1@1+ (1,0) [0|1] "" X
 SG_ UI_showLaneGraph m1 : 45|1@1+ (1,0) [0|1] "" X
 SG_ UI_showTrackLabels m1 : 46|1@1+ (1,0) [0|1] "" X
 SG_ UI_ulcSnooze m1 : 36|1@1+ (1,0) [0|1] "" X

BO_ 819 UI_chargeRequest: 4 VEH
 SG_ UI_acChargeCurrentLimit: 8|7@1+ (1,0) [0|0] "A" X
 SG_ UI_chargeEnableRequest: 2|1@1+ (1,0) [0|0] "" X
 SG_ UI_chargeTerminationPct: 16|10@1+ (0.1,0) [0|0] "%" X
 SG_ UI_closeChargePortDoorRequest: 1|1@1+ (1,0) [0|0] "" X
 SG_ UI_openChargePortDoorRequest: 0|1@1+ (1,0) [0|0] "" X

BO_ 659 UI_chassisControl: 8 VEH
 SG_ UI_accOvertakeEnable: 18|2@1+ (1,0) [0|0] "" X
 SG_ UI_aebEnable: 20|2@1+ (1,0) [0|0] "" X
 SG_ UI_aesEnable: 22|2@1+ (1,0) [0|0] "" X
 SG_ UI_ahlbEnable: 24|2@1+ (1,0) [0|0] "" X
 SG_ UI_autoLaneChangeEnable: 32|2@1+ (1,0) [0|0] "" X
 SG_ UI_autoParkRequest: 28|4@1+ (1,0) [0|0] "" X
 SG_ UI_bsdEnable: 34|2@1+ (1,0) [0|0] "" X
 SG_ UI_chassisControlChecksum: 56|8@1+ (1,0) [0|0] "" X
 SG_ UI_chassisControlCounter: 52|4@1+ (1,0) [0|0] "" X
 SG_ UI_dasDebugEnable: 17|1@1+ (1,0) [0|0] "" X
 SG_ UI_distanceUnits: 16|1@1+ (1,0) [0|0] "" X
 SG_ UI_fcwEnable: 36|2@1+ (1,0) [0|0] "" X
 SG_ UI_fcwSensitivity: 38|2@1+ (1,0) [0|0] "" X
 SG_ UI_latControlEnable: 40|2@1+ (1,0) [0|0] "" X
 SG_ UI_ldwEnable: 42|2@1+ (1,0) [0|0] "" X
 SG_ UI_narrowGarages: 7|1@1+ (1,0) [0|0] "" X
 SG_ UI_parkBrakeRequest: 5|2@1+ (1,0) [0|0] "" X
 SG_ UI_pedalSafetyEnable: 44|2@1+ (1,0) [0|0] "" X
 SG_ UI_rebootAutopilot: 27|1@1+ (1,0) [0|0] "" X
 SG_ UI_redLightStopSignEnable: 46|2@1+ (1,0) [0|0] "" X
 SG_ UI_selfParkTune: 48|4@1+ (1,0) [0|0] "" X
 SG_ UI_steeringTuneRequest: 0|2@1+ (1,0) [0|0] "" X
 SG_ UI_suspensionLevelRequest: 13|3@1+ (1,0) [0|0] "" X
 SG_ UI_tractionControlMode: 2|3@1+ (1,0) [0|0] "" X
 SG_ UI_trailerMode: 12|1@1+ (1,0) [0|0] "" X
 SG_ UI_winchModeRequest: 8|2@1+ (1,0) [0|0] "" X
 SG_ UI_zeroSpeedConfirmed: 10|2@1+ (1,0) [0|0] "" X

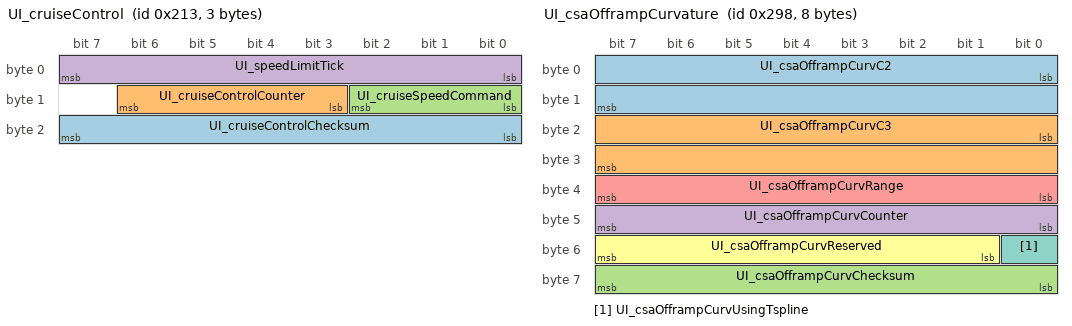
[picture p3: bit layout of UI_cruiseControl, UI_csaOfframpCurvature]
BO_ 531 UI_cruiseControl: 3 VEH
 SG_ UI_cruiseControlChecksum: 16|8@1+ (1,0) [0|0] "" X
 SG_ UI_cruiseControlCounter: 11|4@1+ (1,0) [0|0] "" X
 SG_ UI_cruiseSpeedCommand: 8|3@1+ (1,0) [0|0] "" X
 SG_ UI_speedLimitTick: 0|8@1+ (1,0) [0|0] "speed" X

BO_ 664 UI_csaOfframpCurvature: 8 VEH
 SG_ UI_csaOfframpCurvC2: 0|16@1- (1e-06,0) [0|0] "1/m" X
 SG_ UI_csaOfframpCurvC3: 16|16@1- (4e-09,0) [0|0] "1/m2" X
 SG_ UI_csaOfframpCurvChecksum: 56|8@1+ (1,0) [0|0] "" X
 SG_ UI_csaOfframpCurvCounter: 40|8@1+ (1,0) [0|0] "" X
 SG_ UI_csaOfframpCurvRange: 32|8@1+ (2,0) [0|0] "m" X
 SG_ UI_csaOfframpCurvReserved: 49|7@1+ (1,0) [0|0] "" X
 SG_ UI_csaOfframpCurvUsingTspline: 48|1@1+ (1,0) [0|0] "" X

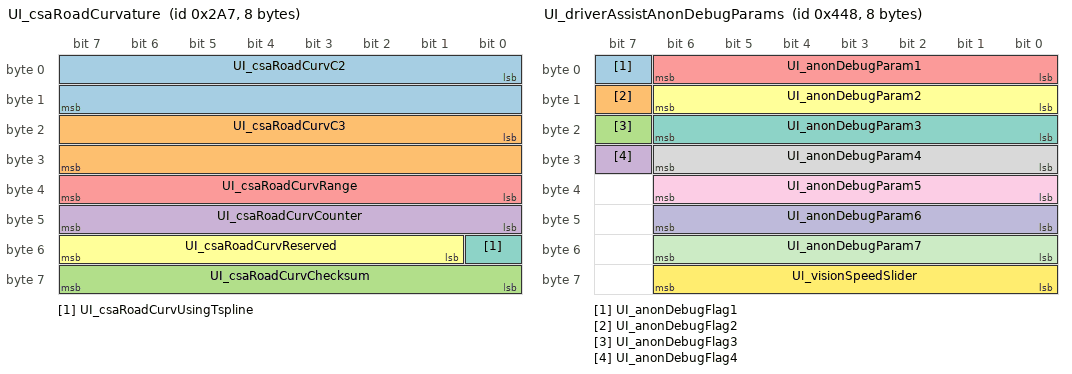
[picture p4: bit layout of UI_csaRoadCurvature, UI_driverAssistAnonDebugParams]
BO_ 679 UI_csaRoadCurvature: 8 VEH
 SG_ UI_csaRoadCurvC2: 0|16@1- (1e-06,0) [0|0] "1/m" X
 SG_ UI_csaRoadCurvC3: 16|16@1- (4e-09,0) [0|0] "1/m2" X
 SG_ UI_csaRoadCurvChecksum: 56|8@1+ (1,0) [0|0] "" X
 SG_ UI_csaRoadCurvCounter: 40|8@1+ (1,0) [0|0] "" X
 SG_ UI_csaRoadCurvRange: 32|8@1+ (2,0) [0|0] "m" X
 SG_ UI_csaRoadCurvReserved: 49|7@1+ (1,0) [0|0] "" X
 SG_ UI_csaRoadCurvUsingTspline: 48|1@1+ (1,0) [0|0] "" X

BO_ 1280 UI_debugECU: 2 VEH
 SG_ UI_debugEcuTarget M: 0|3@1+ (1,0) [0|0] "" X
 SG_ UI_DI_debugEnable m1: 8|1@1+ (1,0) [0|0] "" X
 SG_ UI_DIS_debugEnable m2: 8|1@1+ (1,0) [0|0] "" X
 SG_ UI_PM_debugEnable m3: 8|1@1+ (1,0) [0|0] "" X
 SG_ UI_PM_debugAt100Hz m3: 9|1@1+ (1,0) [0|0] "" X
 SG_ UI_PMS_debugEnable m4: 8|1@1+ (1,0) [0|0] "" X
 SG_ UI_PMS_debugAt100Hz m4: 9|1@1+ (1,0) [0|0] "" X
 SG_ UI_BMS_debugAllEnable m5: 8|1@1+ (1,0) [0|0] "" X
 SG_ UI_BMS_debugDisable m5: 9|1@1+ (1,0) [0|0] "" X
 SG_ UI_VCRIGHT_debugEnable m6: 8|1@1+ (1,0) [0|0] "" X
 SG_ UI_VCFRONT_debugEnable m7: 3|1@1+ (1,0) [0|0] "" X

BO_ 1096 UI_driverAssistAnonDebugParams: 8 VEH
 SG_ UI_anonDebugFlag1: 7|1@1+ (1,0) [0|0] "" X
 SG_ UI_anonDebugFlag2: 15|1@1+ (1,0) [0|0] "" X
 SG_ UI_anonDebugFlag3: 23|1@1+ (1,0) [0|0] "" X
 SG_ UI_anonDebugFlag4: 31|1@1+ (1,0) [0|0] "" X
 SG_ UI_anonDebugParam1: 0|7@1+ (1,0) [0|0] "" X
 SG_ UI_anonDebugParam2: 8|7@1+ (1,0) [0|0] "" X
 SG_ UI_anonDebugParam3: 16|7@1+ (1,0) [0|0] "" X
 SG_ UI_anonDebugParam4: 24|7@1+ (1,0) [0|0] "" X
 SG_ UI_anonDebugParam5: 32|7@1+ (1,0) [0|0] "" X
 SG_ UI_anonDebugParam6: 40|7@1+ (1,0) [0|0] "" X
 SG_ UI_anonDebugParam7: 48|7@1+ (1,0) [0|0] "" X
 SG_ UI_visionSpeedSlider: 56|7@1+ (1,0) [0|0] "" X

BO_ 1016 UI_driverAssistControl: 8 CH
 SG_ UI_accFollowDistanceSetting: 45|3@1+ (1,0) [0|0] "" X
 SG_ UI_accFromZero: 55|1@1+ (1,0) [0|0] "" X
 SG_ UI_adaptiveSetSpeedEnable: 39|1@1+ (1,0) [0|0] "" X
 SG_ UI_alcOffHighwayEnable: 56|1@1+ (1,0) [0|0] "" X
 SG_ UI_autoSummonEnable: 10|1@1+ (1,0) [0|0] "" X
 SG_ UI_autopilotAlwaysOn: 54|1@1+ (1,0) [0|0] "" X
 SG_ UI_autopilotControlRequest: 0|1@1+ (1,0) [0|0] "" X
 SG_ UI_curvSpeedAdaptDisable: 4|1@1+ (1,0) [0|0] "" X
 SG_ UI_curvatureDatabaseOnly: 22|1@1+ (1,0) [0|0] "" X
 SG_ UI_dasDeveloper: 5|1@1+ (1,0) [0|0] "" X
 SG_ UI_driveOnMapsEnable: 13|1@1+ (1,0) [0|0] "" X
 SG_ UI_drivingSide: 40|2@1+ (1,0) [0|0] "" X
 SG_ UI_enableClipTelemetry: 42|1@1+ (1,0) [0|0] "" X
 SG_ UI_enableCutinExperiments: 59|1@1+ (1,0) [0|0] "" X
 SG_ UI_enableNavRouteCSA: 58|1@1+ (1,0) [0|0] "" X
 SG_ UI_enableNextGenACC: 19|1@1+ (1,0) [0|0] "" X
 SG_ UI_enableRoadSegmentTelemetry: 44|1@1+ (1,0) [0|0] "" X
 SG_ UI_enableTripTelemetry: 43|1@1+ (1,0) [0|0] "" X
 SG_ UI_enableVinAssociation: 6|1@1+ (1,0) [0|0] "" X
 SG_ UI_enableVisionOnlyStops: 60|1@1+ (1,0) [0|0] "" X
 SG_ UI_exceptionListEnable: 11|1@1+ (1,0) [0|0] "" X
 SG_ UI_followNavRouteEnable: 49|1@1+ (1,0) [0|0] "" X
 SG_ UI_forksEnable: 63|1@1+ (1,0) [0|0] "" X
 SG_ UI_fuseHPPDisable: 17|1@1+ (1,0) [0|0] "" X
 SG_ UI_fuseLanesDisable: 16|1@1+ (1,0) [0|0] "" X
 SG_ UI_fuseVehiclesDisable: 18|1@1+ (1,0) [0|0] "" X
 SG_ UI_handsOnRequirementDisable: 14|1@1+ (1,0) [0|0] "" X
 SG_ UI_lssElkEnabled: 23|1@1+ (1,0) [0|0] "" X
 SG_ UI_lssLdwEnabled: 8|1@1+ (1,0) [0|0] "" X
 SG_ UI_lssLkaEnabled: 7|1@1+ (1,0) [0|0] "" X
 SG_ UI_roadCheckDisable: 12|1@1+ (1,0) [0|0] "" X
 SG_ UI_selfParkRequest: 28|4@1+ (1,0) [0|0] "" X
 SG_ UI_source3D: 61|2@1+ (1,0) [0|0] "" X
 SG_ UI_summonEntryType: 26|2@1+ (1,0) [0|0] "" X
 SG_ UI_summonExitType: 24|2@1+ (1,0) [0|0] "" X
 SG_ UI_summonHeartbeat: 2|2@1+ (1,0) [0|0] "" X
 SG_ UI_summonReverseDist: 32|6@1+ (1,0) [0|0] "" X
 SG_ UI_ulcBlindSpotConfig: 52|2@1+ (1,0) [0|0] "" X
 SG_ UI_ulcOffHighway: 15|1@1+ (1,0) [0|0] "" X
 SG_ UI_ulcSpeedConfig: 50|2@1+ (1,0) [0|0] "" X
 SG_ UI_ulcStalkConfirm: 1|1@1+ (1,0) [0|0] "" X
 SG_ UI_undertakeAssistEnable: 38|1@1+ (1,0) [0|0] "" X
 SG_ UI_validationLoop: 57|1@1+ (1,0) [0|0] "" X
 SG_ UI_visionSpeedType: 20|2@1+ (1,0) [0|0] "" X

BO_ 568 UI_driverAssistMapData: 8 CH
 SG_ UI_acceptBottsDots: 48|1@1+ (1,0) [0|0] "" X
 SG_ UI_autosteerRestricted: 49|1@1+ (1,0) [0|0] "" X
 SG_ UI_controlledAccess: 37|1@1+ (1,0) [0|0] "" X
 SG_ UI_countryCode: 16|10@1+ (1,0) [0|0] "" X
 SG_ UI_gpsRoadMatch: 28|1@1+ (1,0) [0|0] "" X
 SG_ UI_inSuperchargerGeofence: 6|1@1+ (1,0) [0|0] "" X
 SG_ UI_mapDataChecksum: 56|8@1+ (1,0) [0|0] "" X
 SG_ UI_mapDataCounter: 52|4@1+ (1,0) [0|0] "" X
 SG_ UI_mapSpeedLimit: 8|5@1+ (1,0) [0|0] "" X
 SG_ UI_mapSpeedLimitDependency: 0|3@1+ (1,0) [0|0] "" X
 SG_ UI_mapSpeedLimitType: 13|3@1+ (1,0) [0|0] "" X
 SG_ UI_mapSpeedUnits: 7|1@1+ (1,0) [0|0] "" X
 SG_ UI_navRouteActive: 29|1@1+ (1,0) [0|0] "" X
 SG_ UI_nextBranchDist: 32|5@1+ (10,0) [0|0] "m" X
 SG_ UI_nextBranchLeftOffRamp: 38|1@1+ (1,0) [0|0] "" X
 SG_ UI_nextBranchRightOffRamp: 39|1@1+ (1,0) [0|0] "" X
 SG_ UI_parallelAutoparkEnabled: 30|1@1+ (1,0) [0|0] "" X
 SG_ UI_perpendicularAutoparkEnabled: 31|1@1+ (1,0) [0|0] "" X
 SG_ UI_pmmEnabled: 50|1@1+ (1,0) [0|0] "" X
 SG_ UI_rejectAutosteer: 46|1@1+ (1,0) [0|0] "" X
 SG_ UI_rejectHPP: 42|1@1+ (1,0) [0|0] "" X
 SG_ UI_rejectHandsOn: 47|1@1+ (1,0) [0|0] "" X
 SG_ UI_rejectLeftFreeSpace: 44|1@1+ (1,0) [0|0] "" X
 SG_ UI_rejectLeftLane: 40|1@1+ (1,0) [0|0] "" X
 SG_ UI_rejectNav: 43|1@1+ (1,0) [0|0] "" X
 SG_ UI_rejectRightFreeSpace: 45|1@1+ (1,0) [0|0] "" X
 SG_ UI_rejectRightLane: 41|1@1+ (1,0) [0|0] "" X
 SG_ UI_roadClass: 3|3@1+ (1,0) [0|0] "" X
 SG_ UI_scaEnabled: 51|1@1+ (1,0) [0|0] "" X
 SG_ UI_streetCount: 26|2@1+ (1,0) [0|0] "" X

BO_ 536 UI_driverAssistRoadSign: 8 VEH
 SG_ UI_roadSign M: 0|8@1+ (1,0) [0|0] "" X
 SG_ UI_roadSignChecksum: 56|8@1+ (1,0) [0|0] "" X
 SG_ UI_roadSignCounter: 52|4@1+ (1,0) [0|0] "" X
 SG_ UI_splineID: 48|4@1+ (1,0) [0|0] "" X
 SG_ UI_splineLocConfidence: 40|7@1+ (1,0) [0|0] "1" X
 SG_ UI_dummyData m0: 8|1@1+ (1,0) [0|0] "" X
 SG_ UI_stopSignStopLineDist m1: 8|10@1+ (0.25,-8) [0|0] "m" X
 SG_ UI_stopSignStopLineConf m1: 18|7@1+ (1,0) [0|0] "1" X
 SG_ UI_trafficLightStopLineDist m2: 8|10@1+ (0.25,-8) [0|0] "m" X
 SG_ UI_trafficLightStopLineConf m2: 18|7@1+ (1,0) [0|0] "1" X
 SG_ UI_baseMapSpeedLimitMPS m3: 8|8@1+ (0.25,0) [0|0] "m/s" X
 SG_ UI_bottomQrtlFleetSpeedMPS m3: 16|8@1+ (0.25,0) [0|0] "m/s" X
 SG_ UI_topQrtlFleetSpeedMPS m3: 24|8@1+ (0.25,0) [0|0] "m/s" X
 SG_ UI_meanFleetSplineSpeedMPS m4: 8|8@1+ (0.25,0) [0|0] "m/s" X
 SG_ UI_medianFleetSpeedMPS m4: 16|8@1+ (0.25,0) [0|0] "m/s" X
 SG_ UI_meanFleetSplineAccelMPS2 m4: 24|8@1+ (0.05,-6.35) [0|0] "m/s^2" X
 SG_ UI_rampType m4: 32|3@1+ (1,0) [0|0] "" X
 SG_ UI_currSplineIdFull m5: 8|32@1+ (1,0) [0|0] "1" X

BO_ 645 UI_driverProfileRecall: 8 VEH
 SG_ UI_driverProfileRecallIndex M: 0|3@1+ (1,0) [0|0] "" X
 SG_ UI_driverProfileRecallStop: 3|1@1+ (1,0) [0|0] "" X
 SG_ UI_frontSeatRecallActive m1: 4|1@1+ (1,0) [0|0] "" X
 SG_ UI_frontSeatTrackPos m1: 5|10@1- (4,0) [0|0] "mm" X
 SG_ UI_frontSeatBackPos m1: 16|12@1- (0.1,0) [0|0] "deg" X
 SG_ UI_frontSeatLiftPos m1: 32|10@1- (4,0) [0|0] "mm" X
 SG_ UI_frontSeatTiltPos m1: 48|12@1- (0.1,0) [0|0] "deg" X
 SG_ UI_columnAndLumbarRecallActive m2: 4|1@1+ (1,0) [0|0] "" X
 SG_ UI_steeringColumnUpDownPos m2: 8|8@1- (12,1284) [0|0] "ticks" X
 SG_ UI_lumbarAPressureHpa m2: 16|16@1+ (1,0) [0|0] "" X
 SG_ UI_lumbarBPressureHpa m2: 32|16@1+ (1,0) [0|0] "" X
 SG_ UI_steeringColumnInOutPos m2: 48|8@1- (12,1284) [0|0] "ticks" X
 SG_ UI_mirrorRecallActive m3: 4|1@1+ (1,0) [0|0] "" X
 SG_ UI_leftMirrorTiltXPosition m3: 8|8@1+ (0.02,0) [0|0] "V" X
 SG_ UI_leftMirrorTiltYPosition m3: 16|8@1+ (0.02,0) [0|0] "V" X
 SG_ UI_rightMirrorTiltXPosition m3: 24|8@1+ (0.02,0) [0|0] "V" X
 SG_ UI_rightMirrorTiltYPosition m3: 32|8@1+ (0.02,0) [0|0] "V" X
 SG_ UI_leftMirrorDipXPosition m4: 8|8@1+ (0.02,0) [0|0] "V" X
 SG_ UI_leftMirrorDipYPosition m4: 16|8@1+ (0.02,0) [0|0] "V" X
 SG_ UI_rightMirrorDipXPosition m4: 24|8@1+ (0.02,0) [0|0] "V" X
 SG_ UI_rightMirrorDipYPosition m4: 32|8@1+ (0.02,0) [0|0] "V" X
 SG_ UI_leftBackrestSwitchUp m5: 4|2@1+ (1,0) [0|0] "" X
 SG_ UI_leftBackrestSwitchDown m5: 6|2@1+ (1,0) [0|0] "" X
 SG_ UI_leftLiftSwitchUp m5: 8|2@1+ (1,0) [0|0] "" X
 SG_ UI_leftLiftSwitchDown m5: 10|2@1+ (1,0) [0|0] "" X
 SG_ UI_rightBackrestSwitchUp m5: 12|2@1+ (1,0) [0|0] "" X
 SG_ UI_rightBackrestSwitchDown m5: 14|2@1+ (1,0) [0|0] "" X
 SG_ UI_rightLiftSwitchUp m5: 16|2@1+ (1,0) [0|0] "" X
 SG_ UI_rightLiftSwitchDown m5: 18|2@1+ (1,0) [0|0] "" X

BO_ 984 UI_elevationStatus: 2 VEH
 SG_ UI_elevation: 0|14@1+ (1,0) [0|0] "m" X

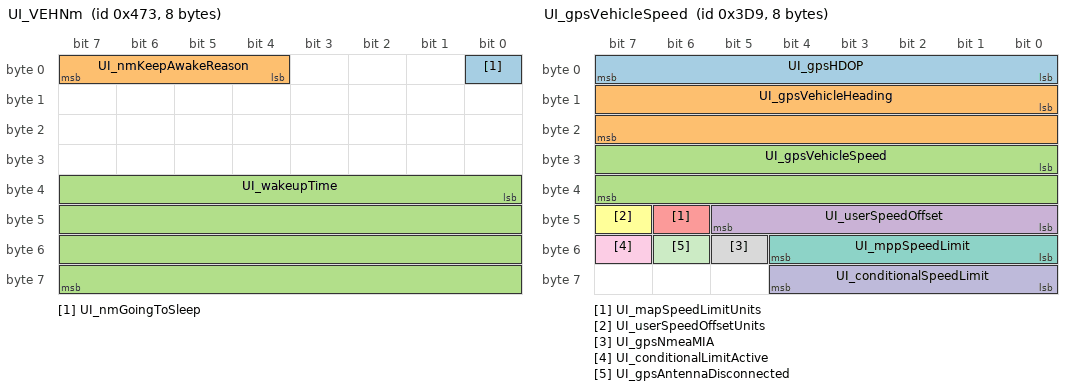
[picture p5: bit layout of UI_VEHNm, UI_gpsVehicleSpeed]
BO_ 1139 UI_VEHNm: 8 VEH
 SG_ UI_nmGoingToSleep: 0|1@1+ (1,0) [0|0] "" X
 SG_ UI_nmKeepAwakeReason: 4|4@1+ (1,0) [0|0] "" X
 SG_ UI_wakeupTime: 32|32@1+ (1,0) [0|0] "" X

BO_ 985 UI_gpsVehicleSpeed: 8 CH
 SG_ UI_gpsHDOP: 0|8@1+ (0.1,0) [0|0] "1" X
 SG_ UI_gpsVehicleHeading: 8|16@1+ (0.0078125,0) [0|0] "deg" X
 SG_ UI_gpsVehicleSpeed: 24|16@1+ (0.00390625,0) [0|0] "km/hr" X
 SG_ UI_userSpeedOffset: 40|6@1+ (1,-30) [0|0] "kph/mph" X
 SG_ UI_mapSpeedLimitUnits: 46|1@1+ (1,0) [0|0] "" X
 SG_ UI_userSpeedOffsetUnits: 47|1@1+ (1,0) [0|0] "" X
 SG_ UI_mppSpeedLimit: 48|5@1+ (5,0) [0|0] "kph/mph" X
 SG_ UI_gpsNmeaMIA: 53|1@1+ (1,0) [0|0] "" X
 SG_ UI_conditionalLimitActive : 55|1@1+ (1,0) [0|1] "" X
 SG_ UI_conditionalSpeedLimit : 56|5@1+ (5,0) [0|155] "kph/mph" X
 SG_ UI_gpsAntennaDisconnected : 54|1@1+ (1,0) [0|1] "" X

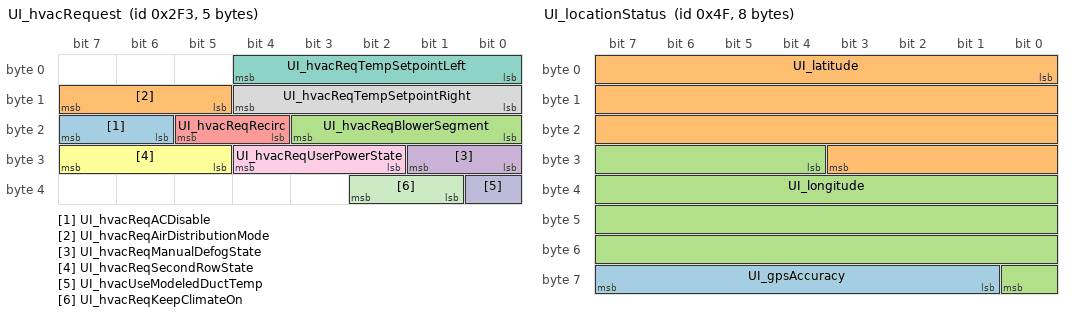
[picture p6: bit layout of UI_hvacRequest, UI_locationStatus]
BO_ 755 UI_hvacRequest: 5 VEH
 SG_ UI_hvacReqACDisable: 22|2@1+ (1,0) [0|0] "" X
 SG_ UI_hvacReqAirDistributionMode: 13|3@1+ (1,0) [0|0] "" X
 SG_ UI_hvacReqBlowerSegment: 16|4@1+ (1,0) [0|0] "" X
 SG_ UI_hvacReqManualDefogState: 24|2@1+ (1,0) [0|0] "" X
 SG_ UI_hvacReqRecirc: 20|2@1+ (1,0) [0|0] "" X
 SG_ UI_hvacReqSecondRowState: 29|3@1+ (1,0) [0|0] "" X
 SG_ UI_hvacReqTempSetpointLeft: 0|5@1+ (0.5,15) [0|0] "degC" X
 SG_ UI_hvacReqTempSetpointRight: 8|5@1+ (0.5,15) [0|0] "degC" X
 SG_ UI_hvacReqUserPowerState: 26|3@1+ (1,0) [0|0] "" X
 SG_ UI_hvacUseModeledDuctTemp: 32|1@1+ (1,0) [0|0] "" X
 SG_ UI_hvacReqKeepClimateOn : 33|2@1+ (1,0) [0|3] "" X

BO_ 79 UI_locationStatus: 8 CH
 SG_ UI_gpsAccuracy: 57|7@1+ (0.2,0) [0|0] "m" X
 SG_ UI_latitude: 0|28@1- (1e-06,0) [0|0] "deg" X
 SG_ UI_longitude: 28|29@1- (1e-06,0) [0|0] "deg" X

BO_ 1011 UI_odo: 3 CH
 SG_ UI_odometer: 0|24@1+ (0.1,0) [0|0] "km" X

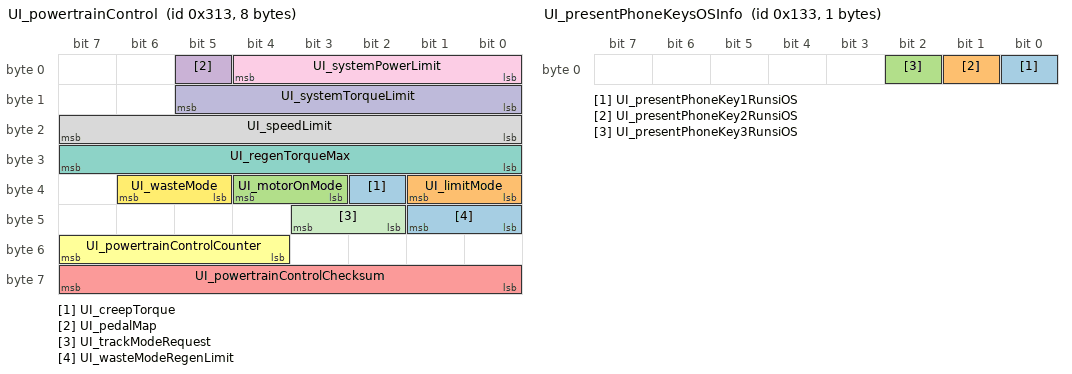
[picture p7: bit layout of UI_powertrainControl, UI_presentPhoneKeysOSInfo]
BO_ 787 UI_powertrainControl: 8 VEH
 SG_ UI_creepTorque: 34|1@1+ (1,0) [0|0] "" X
 SG_ UI_limitMode: 32|2@1+ (1,0) [0|0] "" X
 SG_ UI_motorOnMode: 35|2@1+ (1,0) [0|0] "" X
 SG_ UI_pedalMap: 5|1@1+ (1,0) [0|0] "" X
 SG_ UI_powertrainControlChecksum: 56|8@1+ (1,0) [0|0] "" X
 SG_ UI_powertrainControlCounter: 52|4@1+ (1,0) [0|0] "" X
 SG_ UI_regenTorqueMax: 24|8@1+ (0.5,0) [0|0] "%" X
 SG_ UI_speedLimit: 16|8@1+ (1,50) [0|0] "kph" X
 SG_ UI_systemPowerLimit: 0|5@1+ (20,20) [0|0] "kW" X
 SG_ UI_systemTorqueLimit: 8|6@1+ (100,4000) [0|0] "Nm" X
 SG_ UI_trackModeRequest: 42|2@1+ (1,0) [0|0] "" X
 SG_ UI_wasteMode: 37|2@1+ (1,0) [0|0] "" X
 SG_ UI_wasteModeRegenLimit: 40|2@1+ (1,0) [0|0] "" X

BO_ 499 UI_presentPhoneKey1Info: 8 VEH
 SG_ UI_presentPhoneKey1SHA1: 10|54@1+ (1024,0) [0|0] "" X

BO_ 435 UI_presentPhoneKey2Info: 8 VEH
 SG_ UI_presentPhoneKey2SHA1: 10|54@1+ (1024,0) [0|0] "" X

BO_ 371 UI_presentPhoneKey3Info: 8 VEH
 SG_ UI_presentPhoneKey3SHA1: 10|54@1+ (1024,0) [0|0] "" X

BO_ 307 UI_presentPhoneKeysOSInfo: 1 VEH
 SG_ UI_presentPhoneKey1RunsiOS: 0|1@1+ (1,0) [0|0] "" X
 SG_ UI_presentPhoneKey2RunsiOS: 1|1@1+ (1,0) [0|0] "" X
 SG_ UI_presentPhoneKey3RunsiOS: 2|1@1+ (1,0) [0|0] "" X

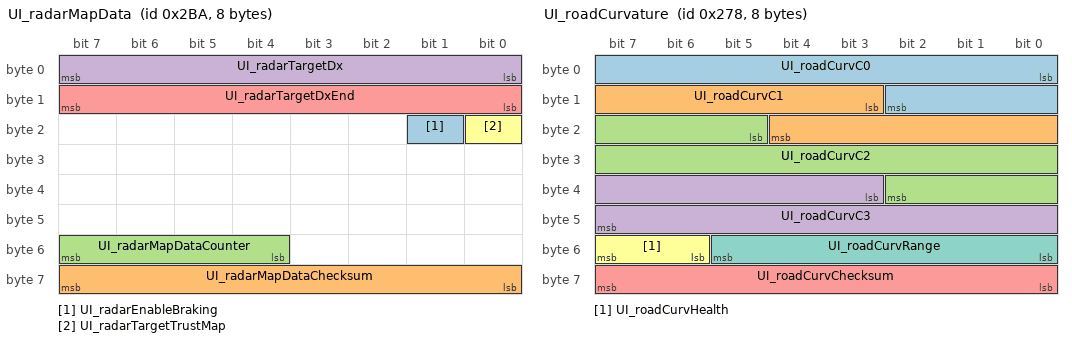
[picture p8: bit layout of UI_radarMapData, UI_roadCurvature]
BO_ 698 UI_radarMapData: 8 VEH
 SG_ UI_radarEnableBraking: 17|1@1+ (1,0) [0|0] "" X
 SG_ UI_radarMapDataChecksum: 56|8@1+ (1,0) [0|0] "" X
 SG_ UI_radarMapDataCounter: 52|4@1+ (1,0) [0|0] "" X
 SG_ UI_radarTargetDx: 0|8@1+ (1,-95) [0|0] "m" X
 SG_ UI_radarTargetDxEnd: 8|8@1+ (1,0) [0|0] "m" X
 SG_ UI_radarTargetTrustMap: 16|1@1+ (1,0) [0|0] "" X

BO_ 632 UI_roadCurvature: 8 VEH
 SG_ UI_roadCurvC0: 0|11@1- (0.02,0) [0|0] "m" X
 SG_ UI_roadCurvC1: 11|10@1- (0.00075,0) [0|0] "1" X
 SG_ UI_roadCurvC2: 21|14@1- (7.5e-06,0) [0|0] "1/m" X
 SG_ UI_roadCurvC3: 35|13@1- (3e-08,0) [0|0] "1/m2" X
 SG_ UI_roadCurvChecksum: 56|8@1+ (1,0) [0|0] "" X
 SG_ UI_roadCurvHealth: 54|2@1+ (1,0) [0|0] "" X
 SG_ UI_roadCurvRange: 48|6@1+ (4,0) [0|0] "m" X

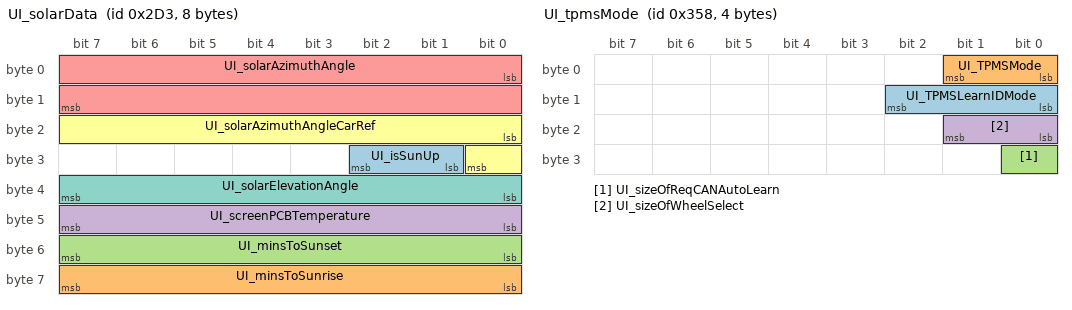
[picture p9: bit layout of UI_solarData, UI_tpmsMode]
BO_ 723 UI_solarData: 8 VEH
 SG_ UI_isSunUp: 25|2@1+ (1,0) [0|0] "" X
 SG_ UI_minsToSunrise: 56|8@1+ (10,0) [0|0] "min" X
 SG_ UI_minsToSunset: 48|8@1+ (10,0) [0|0] "min" X
 SG_ UI_screenPCBTemperature: 40|8@1- (0.5,40) [0|0] "degC" X
 SG_ UI_solarAzimuthAngle: 0|16@1- (1,0) [0|0] "degrees" X
 SG_ UI_solarAzimuthAngleCarRef: 16|9@1- (1,0) [0|0] "degrees" X
 SG_ UI_solarElevationAngle: 32|8@1- (1,0) [0|0] "degrees" X

BO_ 851 UI_status: 7 VEH
 SG_ UI_audioActive: 1|1@1+ (1,0) [0|0] "" X
 SG_ UI_autopilotTrial: 12|2@1+ (1,0) [0|0] "" X
 SG_ UI_bluetoothActive: 2|1@1+ (1,0) [0|0] "" X
 SG_ UI_cameraActive: 49|1@1+ (1,0) [0|0] "" X
 SG_ UI_cellActive: 3|1@1+ (1,0) [0|0] "" X
 SG_ UI_cellConnected: 10|1@1+ (1,0) [0|0] "" X
 SG_ UI_cellNetworkTechnology: 19|4@1+ (1,0) [0|0] "" X
 SG_ UI_cellReceiverPower: 32|8@1+ (1,-128) [-128|127] "dB" X
 SG_ UI_cellSignalBars: 24|3@1+ (1,0) [0|7] "" X
 SG_ UI_developmentCar: 48|1@1+ (1,0) [0|0] "" X
 SG_ UI_displayOn: 5|1@1+ (1,0) [0|0] "" X
 SG_ UI_displayReady: 4|1@1+ (1,0) [0|0] "" X
 SG_ UI_factoryReset: 14|2@1+ (1,0) [0|0] "" X
 SG_ UI_falseTouchCounter: 40|8@1+ (1,0) [0|0] "1" X
 SG_ UI_gpsActive: 16|1@1+ (1,0) [0|0] "" X
 SG_ UI_radioActive: 18|1@1+ (1,0) [0|0] "" X
 SG_ UI_readyForDrive: 9|1@1+ (1,0) [0|0] "" X
 SG_ UI_screenshotActive: 17|1@1+ (1,0) [0|0] "" X
 SG_ UI_systemActive: 8|1@1+ (1,0) [0|0] "" X
 SG_ UI_touchActive: 0|1@1+ (1,0) [0|0] "" X
 SG_ UI_vpnActive: 11|1@1+ (1,0) [0|0] "" X
 SG_ UI_wifiActive: 6|1@1+ (1,0) [0|0] "" X
 SG_ UI_wifiConnected: 7|1@1+ (1,0) [0|0] "" X

BO_ 1064 UI_telemetryControl: 8 CH
 SG_ UI_TCR_classConstElem: 5|1@1+ (1,0) [0|0] "" X
 SG_ UI_TCR_classMovingFourWheel: 8|1@1+ (1,0) [0|0] "" X
 SG_ UI_TCR_classMovingPed: 6|1@1+ (1,0) [0|0] "" X
 SG_ UI_TCR_classMovingTwoWheel: 7|1@1+ (1,0) [0|0] "" X
 SG_ UI_TCR_classUnknown: 9|1@1+ (1,0) [0|0] "" X
 SG_ UI_TCR_downSampleFactor: 10|4@1+ (1,0) [0|0] "" X
 SG_ UI_TCR_enable: 0|1@1+ (1,0) [0|0] "" X
 SG_ UI_TCR_maxDy: 48|5@1+ (0.5,0) [0|0] "m" X
 SG_ UI_TCR_maxObjects: 56|5@1+ (1,0) [0|0] "" X
 SG_ UI_TCR_maxRoadClass: 61|3@1+ (1,0) [0|0] "" X
 SG_ UI_TCR_minRCS: 40|8@1+ (0.25,-14) [0|0] "dB" X
 SG_ UI_TCR_moveStateIndeterm: 4|1@1+ (1,0) [0|0] "" X
 SG_ UI_TCR_moveStateMoving: 3|1@1+ (1,0) [0|0] "" X
 SG_ UI_TCR_moveStateStanding: 1|1@1+ (1,0) [0|0] "" X
 SG_ UI_TCR_moveStateStopped: 2|1@1+ (1,0) [0|0] "" X
 SG_ UI_TCR_vehSpeed: 32|8@1+ (1,0) [0|0] "" X
 SG_ UI_TCR_wExist: 24|5@1+ (1,0) [0|0] "" X

BO_ 856 UI_tpmsMode: 4 VEH
 SG_ UI_TPMSLearnIDMode: 8|3@1+ (1,0) [0|0] "" X
 SG_ UI_TPMSMode: 0|2@1+ (1,0) [0|0] "" X
 SG_ UI_sizeOfReqCANAutoLearn: 24|1@1+ (1,0) [0|0] "" X
 SG_ UI_sizeOfWheelSelect: 16|2@1+ (1,0) [0|0] "" X

BO_ 952 UI_tpmsRCPsetting: 8 CH
 SG_ UI_setRCPFront: 16|8@1+ (0.025,0) [0|0] "bar" X
 SG_ UI_setRCPRear: 24|8@1+ (0.025,0) [0|0] "bar" X

BO_ 627 UI_vehicleControl: 8 VEH
 SG_ UI_accessoryPowerRequest: 0|1@1+ (1,0) [0|0] "" X
 SG_ UI_alarmEnabled: 20|1@1+ (1,0) [0|0] "" X
 SG_ UI_ambientLightingEnabled: 40|1@1+ (1,0) [0|0] "" X
 SG_ UI_autoFoldMirrorsOn: 52|1@1+ (1,0) [0|0] "" X
 SG_ UI_autoHighBeamEnabled: 41|1@1+ (1,0) [0|0] "" X
 SG_ UI_childDoorLockOn: 16|1@1+ (1,0) [0|0] "" X
 SG_ UI_displayBrightnessLevel: 32|8@1+ (0.5,0) [0|0] "%" X
 SG_ UI_domeLightSwitch: 59|2@1+ (1,0) [0|0] "" X
 SG_ UI_driveStateRequest: 62|1@1+ (1,0) [0|0] "" X
 SG_ UI_frontFogSwitch: 3|1@1+ (1,0) [0|0] "" X
 SG_ UI_frontLeftSeatHeatReq: 42|2@1+ (1,0) [0|0] "" X
 SG_ UI_frontRightSeatHeatReq: 44|2@1+ (1,0) [0|0] "" X
 SG_ UI_frunkRequest: 5|1@1+ (1,0) [0|0] "" X
 SG_ UI_globalUnlockOn: 15|1@1+ (1,0) [0|0] "" X
 SG_ UI_honkHorn: 61|1@1+ (1,0) [0|0] "" X
 SG_ UI_intrusionSensorOn: 21|1@1+ (1,0) [0|0] "" X
 SG_ UI_lightSwitch: 1|2@1+ (1,0) [0|0] "" X
 SG_ UI_lockRequest: 17|3@1+ (1,0) [0|0] "" X
 SG_ UI_mirrorDipOnReverse: 53|1@1+ (1,0) [0|0] "" X
 SG_ UI_mirrorFoldRequest: 24|2@1+ (1,0) [0|0] "" X
 SG_ UI_mirrorHeatRequest: 26|1@1+ (1,0) [0|0] "" X
 SG_ UI_powerOff: 31|1@1+ (1,0) [0|0] "" X
 SG_ UI_rearCenterSeatHeatReq: 48|2@1+ (1,0) [0|0] "" X
 SG_ UI_rearFogSwitch: 23|1@1+ (1,0) [0|0] "" X
 SG_ UI_rearLeftSeatHeatReq: 46|2@1+ (1,0) [0|0] "" X
 SG_ UI_rearRightSeatHeatReq: 50|2@1+ (1,0) [0|0] "" X
 SG_ UI_rearWindowLockout: 63|1@1+ (1,0) [0|0] "" X
 SG_ UI_remoteClosureRequest: 54|2@1+ (1,0) [0|0] "" X
 SG_ UI_remoteStartRequest: 27|3@1+ (1,0) [0|0] "" X
 SG_ UI_seeYouHomeLightingOn: 30|1@1+ (1,0) [0|0] "" X
 SG_ UI_steeringBacklightEnabled: 8|1@1+ (1,0) [0|0] "" X
 SG_ UI_steeringButtonMode: 9|3@1+ (1,0) [0|0] "" X
 SG_ UI_stop12vSupport: 22|1@1+ (1,0) [0|0] "" X
 SG_ UI_summonActive: 4|1@1+ (1,0) [0|0] "" X
 SG_ UI_unlockOnPark: 14|1@1+ (1,0) [0|0] "" X
 SG_ UI_walkAwayLock: 13|1@1+ (1,0) [0|0] "" X
 SG_ UI_walkUpUnlock: 12|1@1+ (1,0) [0|0] "" X
 SG_ UI_wiperMode: 6|2@1+ (1,0) [0|0] "" X
 SG_ UI_wiperRequest: 56|3@1+ (1,0) [0|0] "" X

BO_ 947 UI_vehicleControl2: 2 VEH
 SG_ UI_PINToDriveEnabled : 6|1@1+ (1,0) [0|1] "" X
 SG_ UI_PINToDrivePassed : 7|1@1+ (1,0) [0|1] "" X
 SG_ UI_UMCUpdateInhibit : 2|1@1+ (1,0) [0|1] "" X
 SG_ UI_VCLEFTFeature1 : 15|1@1+ (1,0) [0|1] "" X
 SG_ UI_VCSECFeature1 : 14|1@1+ (1,0) [0|1] "" X
 SG_ UI_WCUpdateInhibit : 3|1@1+ (1,0) [0|1] "" X
 SG_ UI_alarmTriggerRequest : 13|1@1+ (1,0) [0|1] "" X
 SG_ UI_autoRollWindowsOnLockEnable : 29|1@1+ (1,0) [0|1] "" X
 SG_ UI_autopilotPowerStateRequest : 25|2@1+ (1,0) [0|2] "" X
 SG_ UI_batteryPreconditioningRequest : 23|1@1+ (1,0) [0|1] "" X
 SG_ UI_coastDownMode : 24|1@1+ (1,0) [0|1] "" X
 SG_ UI_efuseMXResistanceEstArmed : 30|1@1+ (1,0) [0|1] "" X
 SG_ UI_freeRollModeRequest : 19|1@1+ (1,0) [0|1] "" X
 SG_ UI_gloveboxRequest : 0|1@1+ (1,0) [0|1] "" X
 SG_ UI_lightSwitch : 9|3@1+ (1,0) [0|4] "" X
 SG_ UI_locksPanelActive : 5|1@1+ (1,0) [0|1] "" X
 SG_ UI_readyToAddKey : 12|1@1+ (1,0) [0|1] "" X
 SG_ UI_shorted12VCellTestMode : 27|2@1+ (1,0) [0|2] "" X
 SG_ UI_soundHornOnLock : 4|1@1+ (1,0) [0|1] "" X
 SG_ UI_summonState : 16|2@1+ (1,0) [0|3] "" X
 SG_ UI_trunkRequest : 1|1@1+ (1,0) [0|1] "" X
 SG_ UI_userPresent : 18|1@1+ (1,0) [0|1] "" X
 SG_ UI_windowRequest : 20|3@1+ (1,0) [0|4] "" X

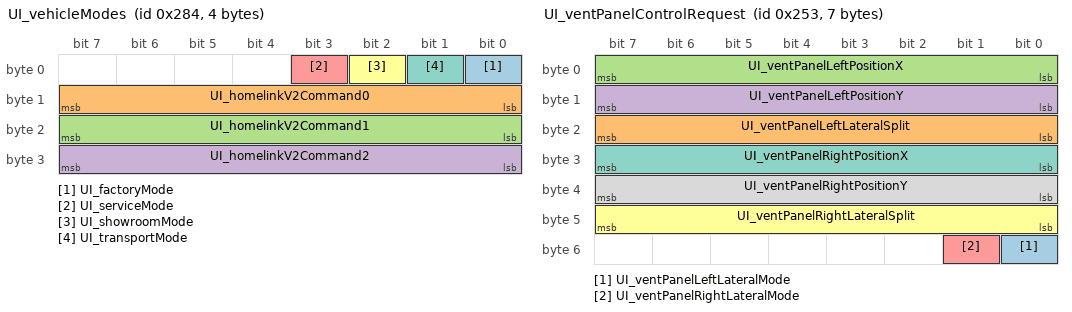
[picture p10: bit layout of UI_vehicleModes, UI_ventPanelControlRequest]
BO_ 644 UI_vehicleModes: 4 VEH
 SG_ UI_factoryMode: 0|1@1+ (1,0) [0|0] "" X
 SG_ UI_homelinkV2Command0: 8|8@1+ (1,0) [0|0] "" X
 SG_ UI_homelinkV2Command1: 16|8@1+ (1,0) [0|0] "" X
 SG_ UI_homelinkV2Command2: 24|8@1+ (1,0) [0|0] "" X
 SG_ UI_serviceMode: 3|1@1+ (1,0) [0|0] "" X
 SG_ UI_showroomMode: 2|1@1+ (1,0) [0|0] "" X
 SG_ UI_transportMode: 1|1@1+ (1,0) [0|0] "" X

BO_ 595 UI_ventPanelControlRequest: 7 VEH
 SG_ UI_ventPanelLeftLateralMode: 48|1@1+ (1,0) [0|0] "" X
 SG_ UI_ventPanelLeftLateralSplit: 16|8@1+ (0.5,0) [0|0] "%" X
 SG_ UI_ventPanelLeftPositionX: 0|8@1+ (0.5,0) [0|0] "%" X
 SG_ UI_ventPanelLeftPositionY: 8|8@1+ (0.5,0) [0|0] "%" X
 SG_ UI_ventPanelRightLateralMode: 49|1@1+ (1,0) [0|0] "" X
 SG_ UI_ventPanelRightLateralSplit: 40|8@1+ (0.5,0) [0|0] "%" X
 SG_ UI_ventPanelRightPositionX: 24|8@1+ (0.5,0) [0|0] "%" X
 SG_ UI_ventPanelRightPositionY: 32|8@1+ (0.5,0) [0|0] "%" X

BO_ 824 UMC_alertMatrix1: 8 VEH
 SG_ UMC_a001_gndMonIntrptLineSide: 0|1@1+ (1,0) [0|0] "" X
 SG_ UMC_a002_GFCITripped: 1|1@1+ (1,0) [0|0] "" X
 SG_ UMC_a003_GFCISelfTestFault: 2|1@1+ (1,0) [0|0] "" X
 SG_ UMC_a004_inputOverVoltage: 3|1@1+ (1,0) [0|0] "" X
 SG_ UMC_a005_inputUnderVoltage: 4|1@1+ (1,0) [0|0] "" X
 SG_ UMC_a006_contactorWelded: 5|1@1+ (1,0) [0|0] "" X
 SG_ UMC_a007_pcbaOT: 6|1@1+ (1,0) [0|0] "" X
 SG_ UMC_a008_wallPlugOT: 7|1@1+ (1,0) [0|0] "" X
 SG_ UMC_a009_vehConnOT: 8|1@1+ (1,0) [0|0] "" X
 SG_ UMC_a010_inputOT: 9|1@1+ (1,0) [0|0] "" X
 SG_ UMC_a011_proxDisconnected: 10|1@1+ (1,0) [0|0] "" X
 SG_ UMC_a012_pilotFault: 11|1@1+ (1,0) [0|0] "" X
 SG_ UMC_a013_SA_Temperature: 12|1@1+ (1,0) [0|0] "" X
 SG_ UMC_a014_SA_Genealogy: 13|1@1+ (1,0) [0|0] "" X
 SG_ UMC_a015_SA_Connection: 14|1@1+ (1,0) [0|0] "" X
 SG_ UMC_a016_pcbaOTFoldback: 15|1@1+ (1,0) [0|0] "" X
 SG_ UMC_a017_wallPlugOTFoldback: 16|1@1+ (1,0) [0|0] "" X
 SG_ UMC_a018_vehConnOTFoldback: 17|1@1+ (1,0) [0|0] "" X
 SG_ UMC_a019_inputOTFoldback: 18|1@1+ (1,0) [0|0] "" X
 SG_ UMC_a020_applicationCRC: 19|1@1+ (1,0) [0|0] "" X
 SG_ UMC_a021_dataBus: 20|1@1+ (1,0) [0|0] "" X
 SG_ UMC_a022_criticalRAM: 21|1@1+ (1,0) [0|0] "" X
 SG_ UMC_a023_adcSelfTest: 22|1@1+ (1,0) [0|0] "" X

BO_ 609 VCFRONT_12VBatteryStatus: 8 VEH
 SG_ VCFRONT_12VBatteryIndex M : 0|2@1+ (1,0) [0|4] ""  Receiver
 SG_ VCFRONT_IBSCurrent m0 : 16|12@1- (0.005,0) [-163.84|163.835] "A"  Receiver
 SG_ VCFRONT_IBSCurrentRaw m1 : 16|16@1- (0.005,0) [-163.84|163.835] "A"  Receiver
 SG_ VCFRONT_IBSVoltage m1 : 32|12@1+ (0.005443676098,0) [0|22.29185362131] "V"  Receiver
 SG_ VCFRONT_IBSAmpHours m2 : 2|14@1- (0.01,0) [-81.92|81.91] "Ah"  Receiver
 SG_ VCFRONT_IBSTemperature m2 : 8|16@0- (0.1,0) [-327.68|327.66] "degC"  Receiver

BO_ 545 VCFRONT_LVPowerState: 8 VEH
 SG_ VCFRONT_LVPowerStateChecksum: 56|8@1+ (1,0) [0|0] "" X
 SG_ VCFRONT_LVPowerStateCounter: 52|4@1+ (1,0) [0|0] "" X
 SG_ VCFRONT_LVPowerStateIndex M: 0|5@1+ (1,0) [0|0] "" X
 SG_ VCFRONT_vehiclePowerState: 5|2@1+ (1,0) [0|0] "" X
 SG_ VCFRONT_parkLVState m0: 8|2@1+ (1,0) [0|0] "" X
 SG_ VCFRONT_espLVState m0: 10|2@1+ (1,0) [0|0] "" X
 SG_ VCFRONT_radcLVState m0: 12|2@1+ (1,0) [0|0] "" X
 SG_ VCFRONT_hvacCompLVState m0: 14|2@1+ (1,0) [0|0] "" X
 SG_ VCFRONT_ptcLVRequest m0: 16|2@1+ (1,0) [0|0] "" X
 SG_ VCFRONT_sccmLVRequest m0: 18|2@1+ (1,0) [0|0] "" X
 SG_ VCFRONT_tpmsLVRequest m0: 20|2@1+ (1,0) [0|0] "" X
 SG_ VCFRONT_rcmLVRequest m0: 22|2@1+ (1,0) [0|0] "" X
 SG_ VCFRONT_iBoosterLVState m0: 24|2@1+ (1,0) [0|0] "" X
 SG_ VCFRONT_tunerLVRequest m0: 26|2@1+ (1,0) [0|0] "" X
 SG_ VCFRONT_amplifierLVRequest m0: 28|2@1+ (1,0) [0|0] "" X
 SG_ VCFRONT_das1HighCurrentLVState m0: 30|2@1+ (1,0) [0|0] "" X
 SG_ VCFRONT_das2HighCurrentLVState m0: 32|2@1+ (1,0) [0|0] "" X
 SG_ VCFRONT_diLVRequest m0: 34|2@1+ (1,0) [0|0] "" X
 SG_ VCFRONT_disLVState m0: 36|2@1+ (1,0) [0|0] "" X
 SG_ VCFRONT_oilPumpFrontLVState m0: 38|2@1+ (1,0) [0|0] "" X
 SG_ VCFRONT_oilPumpRearLVRequest m0: 40|2@1+ (1,0) [0|0] "" X
 SG_ VCFRONT_ocsLVRequest m0: 42|2@1+ (1,0) [0|0] "" X
 SG_ VCFRONT_vcleftHiCurrentLVState m0: 44|2@1+ (1,0) [0|0] "" X
 SG_ VCFRONT_vcrightHiCurrentLVState m0: 46|2@1+ (1,0) [0|0] "" X
 SG_ VCFRONT_uiHiCurrentLVState m0: 48|2@1+ (1,0) [0|0] "" X
 SG_ VCFRONT_uiAudioLVState m0: 50|2@1+ (1,0) [0|0] "" X
 SG_ VCFRONT_cpLVRequest m1: 8|2@1+ (1,0) [0|0] "" X
 SG_ VCFRONT_epasLVState m1: 10|2@1+ (1,0) [0|0] "" X
 SG_ VCFRONT_hvcLVRequest m1: 12|2@1+ (1,0) [0|0] "" X
 SG_ VCFRONT_tasLVState m1: 14|2@1+ (1,0) [0|0] "" X
 SG_ VCFRONT_pcsLVState m1: 16|2@1+ (1,0) [0|0] "" X

BO_ 832 VCFRONT_alertMatrix: 8 VEH
 SG_ VCFRONT_matrixIndex M: 0|4@1+ (1,0) [0|0] "" X
 SG_ VCFRONT_a001_WatchdogReset m0: 4|1@1+ (1,0) [0|0] "" X
 SG_ VCFRONT_a002_PowerLossReset m0: 5|1@1+ (1,0) [0|0] "" X
 SG_ VCFRONT_a003_SWAssertion m0: 6|1@1+ (1,0) [0|0] "" X
 SG_ VCFRONT_a010_ExtSupplyVoltError m0: 13|1@1+ (1,0) [0|0] "" X
 SG_ VCFRONT_a012_CPUReset m0: 15|1@1+ (1,0) [0|0] "" X
 SG_ VCFRONT_a013_AlertManagerFault m0: 16|1@1+ (1,0) [0|0] "" X
 SG_ VCFRONT_a015_NVMMAlert m0: 18|1@1+ (1,0) [0|0] "" X
 SG_ VCFRONT_a021_TaskSchedulerError m0: 24|1@1+ (1,0) [0|0] "" X
 SG_ VCFRONT_a022_TaskInitError m0: 25|1@1+ (1,0) [0|0] "" X
 SG_ VCFRONT_a031_UDSActive m0: 34|1@1+ (1,0) [0|0] "" X
 SG_ VCFRONT_a041_HighCPULoad m0: 44|1@1+ (1,0) [0|0] "" X
 SG_ VCFRONT_a042_HighStackUsage m0: 45|1@1+ (1,0) [0|0] "" X
 SG_ VCFRONT_a043_Task1msError m0: 46|1@1+ (1,0) [0|0] "" X
 SG_ VCFRONT_a044_Task10msError m0: 47|1@1+ (1,0) [0|0] "" X
 SG_ VCFRONT_a045_Task100msError m0: 48|1@1+ (1,0) [0|0] "" X
 SG_ VCFRONT_a046_Task1000msError m0: 49|1@1+ (1,0) [0|0] "" X
 SG_ VCFRONT_a059_inputResistanceHigh m0: 62|1@1+ (1,0) [0|0] "" X
 SG_ VCFRONT_a060_engineeringBuild m0: 63|1@1+ (1,0) [0|0] "" X
 SG_ VCFRONT_a061_XCPConnected m1: 4|1@1+ (1,0) [0|0] "" X
 SG_ VCFRONT_a062_XCPWasConnected m1: 5|1@1+ (1,0) [0|0] "" X
 SG_ VCFRONT_a063_SwitchFault m1: 6|1@1+ (1,0) [0|0] "" X
 SG_ VCFRONT_a064_busSleepReqTimeout m1: 7|1@1+ (1,0) [0|0] "" X
 SG_ VCFRONT_a097_CMP_MIA m1: 40|1@1+ (1,0) [0|0] "" X
 SG_ VCFRONT_a098_DI_THERMAL_MIA m1: 41|1@1+ (1,0) [0|0] "" X
 SG_ VCFRONT_a099_PARK_MIA m1: 42|1@1+ (1,0) [0|0] "" X
 SG_ VCFRONT_a100_CANbus_MIA m1: 43|1@1+ (1,0) [0|0] "" X
 SG_ VCFRONT_a101_PM_MIA m1: 44|1@1+ (1,0) [0|0] "" X
 SG_ VCFRONT_a102_PTC_MIA m1: 45|1@1+ (1,0) [0|0] "" X
 SG_ VCFRONT_a103_CP_MIA m1: 46|1@1+ (1,0) [0|0] "" X
 SG_ VCFRONT_a104_DAS_MIA m1: 47|1@1+ (1,0) [0|0] "" X
 SG_ VCFRONT_a105_TAS_MIA m1: 48|1@1+ (1,0) [0|0] "" X
 SG_ VCFRONT_a106_PCS_MIA m1: 49|1@1+ (1,0) [0|0] "" X
 SG_ VCFRONT_a107_BMS_MIA m1: 50|1@1+ (1,0) [0|0] "" X
 SG_ VCFRONT_a108_DIS_MIA m1: 51|1@1+ (1,0) [0|0] "" X
 SG_ VCFRONT_a109_RCM_MIA m1: 52|1@1+ (1,0) [0|0] "" X
 SG_ VCFRONT_a110_GTW_MIA m1: 53|1@1+ (1,0) [0|0] "" X
 SG_ VCFRONT_a111_EPBR_MIA m1: 54|1@1+ (1,0) [0|0] "" X
 SG_ VCFRONT_a112_EPBL_MIA m1: 55|1@1+ (1,0) [0|0] "" X
 SG_ VCFRONT_a113_UI_MIA m1: 56|1@1+ (1,0) [0|0] "" X
 SG_ VCFRONT_a114_ESP_MIA m1: 57|1@1+ (1,0) [0|0] "" X
 SG_ VCFRONT_a115_VCSEC_MIA m1: 58|1@1+ (1,0) [0|0] "" X
 SG_ VCFRONT_a116_VCRIGHT_MIA m1: 59|1@1+ (1,0) [0|0] "" X
 SG_ VCFRONT_a117_VCLEFT_MIA m1: 60|1@1+ (1,0) [0|0] "" X
 SG_ VCFRONT_a118_VCFRONT_MIA m1: 61|1@1+ (1,0) [0|0] "" X
 SG_ VCFRONT_a119_SCCM_MIA m1: 62|1@1+ (1,0) [0|0] "" X
 SG_ VCFRONT_a120_DI_DRIVE_MIA m1: 63|1@1+ (1,0) [0|0] "" X
 SG_ VCFRONT_a121_pumpBatICLatchFault m2: 4|1@1+ (1,0) [0|0] "" X
 SG_ VCFRONT_a122_pumpBatICWarning m2: 5|1@1+ (1,0) [0|0] "" X
 SG_ VCFRONT_a123_pumpPtICLatchFault m2: 6|1@1+ (1,0) [0|0] "" X
 SG_ VCFRONT_a124_pumpPtICWarning m2: 7|1@1+ (1,0) [0|0] "" X
 SG_ VCFRONT_a125_thmlFanICLatchFault m2: 8|1@1+ (1,0) [0|0] "" X
 SG_ VCFRONT_a126_thmlFanICWarning m2: 9|1@1+ (1,0) [0|0] "" X
 SG_ VCFRONT_a127_vcleftEFuseTrip m2: 10|1@1+ (1,0) [0|0] "" X
 SG_ VCFRONT_a128_vcrightEFuseTrip m2: 11|1@1+ (1,0) [0|0] "" X
 SG_ VCFRONT_a129_pcsEFuseTrip m2: 12|1@1+ (1,0) [0|0] "" X
 SG_ VCFRONT_a130_epas3pEFuseTrip m2: 13|1@1+ (1,0) [0|0] "" X
 SG_ VCFRONT_a131_epas3sEFuseTrip m2: 14|1@1+ (1,0) [0|0] "" X
 SG_ VCFRONT_a132_iBoosterEFuseTrip m2: 15|1@1+ (1,0) [0|0] "" X
 SG_ VCFRONT_a133_espEFuseTrip m2: 16|1@1+ (1,0) [0|0] "" X
 SG_ VCFRONT_a134_fusedHighEFuseTrip m2: 17|1@1+ (1,0) [0|0] "" X
 SG_ VCFRONT_a135_coolantLevelLow m2: 18|1@1+ (1,0) [0|0] "" X
 SG_ VCFRONT_a136_refrigDischTempSns m2: 19|1@1+ (1,0) [0|0] "" X
 SG_ VCFRONT_a137_refrigDischPresSns m2: 20|1@1+ (1,0) [0|0] "" X
 SG_ VCFRONT_a138_refrigSuctTempSns m2: 21|1@1+ (1,0) [0|0] "" X
 SG_ VCFRONT_a139_refrigSuctPresSns m2: 22|1@1+ (1,0) [0|0] "" X
 SG_ VCFRONT_a140_coolantTempPtSns m2: 23|1@1+ (1,0) [0|0] "" X
 SG_ VCFRONT_a141_coolantTempBatSns m2: 24|1@1+ (1,0) [0|0] "" X
 SG_ VCFRONT_a142_exvMotorFault m2: 25|1@1+ (1,0) [0|0] "" X
 SG_ VCFRONT_a143_pumpBatICTransFault m2: 26|1@1+ (1,0) [0|0] "" X
 SG_ VCFRONT_a144_pumpPtICTransFault m2: 27|1@1+ (1,0) [0|0] "" X
 SG_ VCFRONT_a145_thmlFanICTransFault m2: 28|1@1+ (1,0) [0|0] "" X
 SG_ VCFRONT_a146_pumpBatSoftStall m2: 29|1@1+ (1,0) [0|0] "" X
 SG_ VCFRONT_a147_pumpPtSoftStall m2: 30|1@1+ (1,0) [0|0] "" X
 SG_ VCFRONT_a148_thmlFanSoftStall m2: 31|1@1+ (1,0) [0|0] "" X
 SG_ VCFRONT_a149_BLEFrontPowerCycled m2: 32|1@1+ (1,0) [0|0] "" X
 SG_ VCFRONT_a150_pumpBatLowRPMCBang m2: 33|1@1+ (1,0) [0|0] "" X
 SG_ VCFRONT_a151_pumpPtLowRPMCBang m2: 34|1@1+ (1,0) [0|0] "" X
 SG_ VCFRONT_a152_thmlFanLowRPMCBang m2: 35|1@1+ (1,0) [0|0] "" X
 SG_ VCFRONT_a156_louverBlockage m2: 39|1@1+ (1,0) [0|0] "" X
 SG_ VCFRONT_a157_louverBreakage m2: 40|1@1+ (1,0) [0|0] "" X
 SG_ VCFRONT_a158_louverDisconnected m2: 41|1@1+ (1,0) [0|0] "" X
 SG_ VCFRONT_a159_fiveWayValveFault m2: 42|1@1+ (1,0) [0|0] "" X
 SG_ VCFRONT_a160_compressorInhibited m2: 43|1@1+ (1,0) [0|0] "" X
 SG_ VCFRONT_a161_compressorSelfFault m2: 44|1@1+ (1,0) [0|0] "" X
 SG_ VCFRONT_a164_eFuseLckoutMissing m2: 47|1@1+ (1,0) [0|0] "" X
 SG_ VCFRONT_a165_unxpctdEFuseLckout m2: 48|1@1+ (1,0) [0|0] "" X
 SG_ VCFRONT_a166_rightHCMMIA m2: 49|1@1+ (1,0) [0|0] "" X
 SG_ VCFRONT_a167_leftHCMMIA m2: 50|1@1+ (1,0) [0|0] "" X
 SG_ VCFRONT_a168_hcmShortToVBAT m2: 51|1@1+ (1,0) [0|0] "" X
 SG_ VCFRONT_a169_hcmPhaseEnableFail m2: 52|1@1+ (1,0) [0|0] "" X
 SG_ VCFRONT_a170_hcmUnderVoltage m2: 53|1@1+ (1,0) [0|0] "" X
 SG_ VCFRONT_a171_driveBlckdByMsmtch m2: 54|1@1+ (1,0) [0|0] "" X
 SG_ VCFRONT_a172_wsteHtBlckdByMsmtch m2: 55|1@1+ (1,0) [0|0] "" X
 SG_ VCFRONT_a173_HVBlckdByMsmtch m2: 56|1@1+ (1,0) [0|0] "" X
 SG_ VCFRONT_a174_driveNotAuthed m2: 57|1@1+ (1,0) [0|0] "" X
 SG_ VCFRONT_a175_ambientTempSns m2: 58|1@1+ (1,0) [0|0] "" X
 SG_ VCFRONT_a176_vehicleInSelfTest m2: 59|1@1+ (1,0) [0|0] "" X
 SG_ VCFRONT_a177_mcuAudioEFuseFault m2: 60|1@1+ (1,0) [0|0] "" X
 SG_ VCFRONT_a179_highLVAmpsIntoPCS m2: 62|1@1+ (1,0) [0|0] "" X
 SG_ VCFRONT_a180_12VNotSupported m2: 63|1@1+ (1,0) [0|0] "" X
 SG_ VCFRONT_a182_replace12VBattery m3: 5|1@1+ (1,0) [0|0] "" X
 SG_ VCFRONT_a183_low12VCapacity m3: 6|1@1+ (1,0) [0|0] "" X
 SG_ VCFRONT_a185_washerFluidLow m3: 8|1@1+ (1,0) [0|0] "" X
 SG_ VCFRONT_a186_noDriveChgCableCon m3: 9|1@1+ (1,0) [0|0] "" X
 SG_ VCFRONT_a187_busesNotSleeping m3: 10|1@1+ (1,0) [0|0] "" X
 SG_ VCFRONT_a188_sleepFailed m3: 11|1@1+ (1,0) [0|0] "" X
 SG_ VCFRONT_a189_IBSMIA m3: 12|1@1+ (1,0) [0|0] "" X
 SG_ VCFRONT_a190_DCDCNotOperational m3: 13|1@1+ (1,0) [0|0] "" X
 SG_ VCFRONT_a191_exitDriveLow12V m3: 14|1@1+ (1,0) [0|0] "" X
 SG_ VCFRONT_a192_criticalLoadShed m3: 15|1@1+ (1,0) [0|0] "" X
 SG_ VCFRONT_a193_mcuAudioRetry m3: 16|1@1+ (1,0) [0|0] "" X
 SG_ VCFRONT_a194_iBoosterRetry m3: 17|1@1+ (1,0) [0|0] "" X
 SG_ VCFRONT_a195_drveBlckdVltgeTooHgh m3: 18|1@1+ (1,0) [0|0] "" X
 SG_ VCFRONT_a196_discnctd12VBattery m3: 19|1@1+ (1,0) [0|0] "" X
 SG_ VCFRONT_a198_PRVCANOverterminate m3: 21|1@1+ (1,0) [0|0] "" X
 SG_ VCFRONT_a199_PRVCANUndertrminate m3: 22|1@1+ (1,0) [0|0] "" X
 SG_ VCFRONT_a200_vcleftSelfTestFail m3: 23|1@1+ (1,0) [0|0] "" X
 SG_ VCFRONT_a201_vcrightSelfTestFail m3: 24|1@1+ (1,0) [0|0] "" X
 SG_ VCFRONT_a202_pcsSelfTestFail m3: 25|1@1+ (1,0) [0|0] "" X
 SG_ VCFRONT_a203_epas3pSelfTestFail m3: 26|1@1+ (1,0) [0|0] "" X
 SG_ VCFRONT_a204_epas3sSelfTestFail m3: 27|1@1+ (1,0) [0|0] "" X
 SG_ VCFRONT_a205_iBoosterSelfTestFail m3: 28|1@1+ (1,0) [0|0] "" X
 SG_ VCFRONT_a206_espSelfTestFail m3: 29|1@1+ (1,0) [0|0] "" X
 SG_ VCFRONT_a207_vbatFusdSelfTestFail m3: 30|1@1+ (1,0) [0|0] "" X
 SG_ VCFRONT_a208_brakeFluidLow m3: 31|1@1+ (1,0) [0|0] "" X
 SG_ VCFRONT_a209_brakeFluidSNA m3: 32|1@1+ (1,0) [0|0] "" X
 SG_ VCFRONT_a210_fiveWayValveCalib m3: 33|1@1+ (1,0) [0|0] "" X
 SG_ VCFRONT_a211_I2CFault m3: 34|1@1+ (1,0) [0|0] "" X
 SG_ VCFRONT_a212_IBSOverTemp m3: 35|1@1+ (1,0) [0|0] "" X
 SG_ VCFRONT_a213_12VOvercharge m3: 36|1@1+ (1,0) [0|0] "" X
 SG_ VCFRONT_a214_airCompUnderCurrent m3: 37|1@1+ (1,0) [0|0] "" X
 SG_ VCFRONT_a215_airCompDriverFault m3: 38|1@1+ (1,0) [0|0] "" X
 SG_ VCFRONT_a219_12VVoltFloorRchd m3: 42|1@1+ (1,0) [0|0] "" X
 SG_ VCFRONT_a220_reverseBatteryFault m3: 43|1@1+ (1,0) [0|0] "" X
 SG_ VCFRONT_a221_leftTurnLightFault m3: 44|1@1+ (1,0) [0|0] "" X
 SG_ VCFRONT_a222_rightTurnLightFault m3: 45|1@1+ (1,0) [0|0] "" X
 SG_ VCFRONT_a223_12VTempSensDiscnect m3: 46|1@1+ (1,0) [0|0] "" X
 SG_ VCFRONT_a224_revBatChrgPmpFault m3: 47|1@1+ (1,0) [0|0] "" X
 SG_ VCFRONT_a225_driveBlckdByShowroom m3: 48|1@1+ (1,0) [0|0] "" X
 SG_ VCFRONT_a226_railAPoweredForFrunk m3: 49|1@1+ (1,0) [0|0] "" X
 SG_ VCFRONT_a228_pumpBatFbkSanity m3: 51|1@1+ (1,0) [0|0] "" X
 SG_ VCFRONT_a229_pumpPtFbkSanity m3: 52|1@1+ (1,0) [0|0] "" X
 SG_ VCFRONT_a230_thmlFanFbkSanity m3: 53|1@1+ (1,0) [0|0] "" X
 SG_ VCFRONT_a231_12VTempSensShort m3: 54|1@1+ (1,0) [0|0] "" X
 SG_ VCFRONT_a233_autopilot1EFuseFault m3: 56|1@1+ (1,0) [0|0] "" X
 SG_ VCFRONT_a234_autopilot2EFuseFault m3: 57|1@1+ (1,0) [0|0] "" X
 SG_ VCFRONT_a235_ptTempSnsIrrational m3: 58|1@1+ (1,0) [0|0] "" X
 SG_ VCFRONT_a236_batTempSnsIrrational m3: 59|1@1+ (1,0) [0|0] "" X
 SG_ VCFRONT_a237_pumpBatChipComms m3: 60|1@1+ (1,0) [0|0] "" X
 SG_ VCFRONT_a238_pumpPtChipComms m3: 61|1@1+ (1,0) [0|0] "" X
 SG_ VCFRONT_a239_thmlFanChipComms m3: 62|1@1+ (1,0) [0|0] "" X
 SG_ VCFRONT_a243_12VOverchargeInstc m4: 6|1@1+ (1,0) [0|0] "" X
 SG_ VCFRONT_a244_sleepBypassFault m4: 7|1@1+ (1,0) [0|0] "" X
 SG_ VCFRONT_a245_pump1EFuseFault m4: 8|1@1+ (1,0) [0|0] "" X
 SG_ VCFRONT_a246_pump2EFuseFault m4: 9|1@1+ (1,0) [0|0] "" X
 SG_ VCFRONT_a247_evapSolenoidFault m4: 10|1@1+ (1,0) [0|0] "" X
 SG_ VCFRONT_a248_voltageOutOfSpec m4: 11|1@1+ (1,0) [0|0] "" X
 SG_ VCFRONT_a249_fiveWayValveBadMode m4: 12|1@1+ (1,0) [0|0] "" X
 SG_ VCFRONT_a250_headlampsNotAimed m4: 13|1@1+ (1,0) [0|0] "" X
 SG_ VCFRONT_a251_UIWakeupTrigger m4: 14|1@1+ (1,0) [0|0] "" X
 SG_ VCFRONT_a252_frontControllerWakeup m4: 15|1@1+ (1,0) [0|0] "" X
 SG_ VCFRONT_a253_maxChrgeSssionTmeout m4: 16|1@1+ (1,0) [0|0] "" X
 SG_ VCFRONT_a254_pumpBatStopped m4: 17|1@1+ (1,0) [0|0] "" X
 SG_ VCFRONT_a255_pumpPtStopped m4: 18|1@1+ (1,0) [0|0] "" X
 SG_ VCFRONT_a256_compTornShaftSeal m4: 19|1@1+ (1,0) [0|0] "" X
 SG_ VCFRONT_a257_portExpanderVOR m4: 20|1@1+ (1,0) [0|0] "" X
 SG_ VCFRONT_a258_resistanceEstimationRun m4: 21|1@1+ (1,0) [0|0] "" X
 SG_ VCFRONT_a259_12vVoltageDropOnHighLoadCurrent m4: 22|1@1+ (1,0) [0|0] "" X

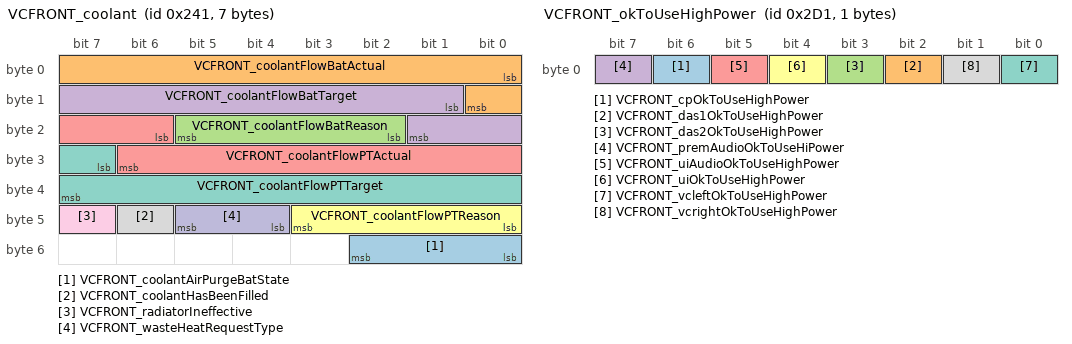
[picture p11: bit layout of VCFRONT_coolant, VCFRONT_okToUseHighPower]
BO_ 577 VCFRONT_coolant: 7 VEH
 SG_ VCFRONT_coolantAirPurgeBatState: 48|3@1+ (1,0) [0|0] "" X
 SG_ VCFRONT_coolantFlowBatActual: 0|9@1+ (0.1,0) [0|0] "LPM" X
 SG_ VCFRONT_coolantFlowBatReason: 18|4@1+ (1,0) [0|0] "" X
 SG_ VCFRONT_coolantFlowBatTarget: 9|9@1+ (0.1,0) [0|0] "LPM" X
 SG_ VCFRONT_coolantFlowPTActual: 22|9@1+ (0.1,0) [0|0] "LPM" X
 SG_ VCFRONT_coolantFlowPTReason: 40|4@1+ (1,0) [0|0] "" X
 SG_ VCFRONT_coolantFlowPTTarget: 31|9@1+ (0.1,0) [0|0] "LPM" X
 SG_ VCFRONT_coolantHasBeenFilled: 46|1@1+ (1,0) [0|0] "" X
 SG_ VCFRONT_radiatorIneffective: 47|1@1+ (1,0) [0|0] "" X
 SG_ VCFRONT_wasteHeatRequestType: 44|2@1+ (1,0) [0|0] "" X

BO_ 753 VCFRONT_eFuseDebugStatus: 8 VEH
 SG_ VCFRONT_eFuseDebugStatusIndex M: 0|5@1+ (1,0) [0|0] "" X
 SG_ VCFRONT_rightControllerState m0: 8|2@1+ (1,0) [0|0] "" X
 SG_ VCFRONT_rightControllerFault m0: 10|1@1+ (1,0) [0|0] "" X
 SG_ VCFRONT_vcrightSelfTestResult m0: 11|4@1+ (1,0) [0|0] "" X
 SG_ VCFRONT_rightControllerTemp m0: 15|11@1+ (0.125,-40) [0|0] "degC" X
 SG_ VCFRONT_rightControllerVoltage m0: 31|16@1+ (0.1,0) [0|0] "V" X
 SG_ VCFRONT_rightControllerCurrent m0: 47|16@1+ (0.1,0) [0|0] "A" X
 SG_ VCFRONT_leftControllerState m1: 8|2@1+ (1,0) [0|0] "" X
 SG_ VCFRONT_leftControllerFault m1: 10|1@1+ (1,0) [0|0] "" X
 SG_ VCFRONT_vcleftSelfTestResult m1: 11|4@1+ (1,0) [0|0] "" X
 SG_ VCFRONT_leftControllerTemp m1: 15|11@1+ (0.125,-40) [0|0] "degC" X
 SG_ VCFRONT_leftControllerVoltage m1: 31|16@1+ (0.1,0) [0|0] "V" X
 SG_ VCFRONT_leftControllerCurrent m1: 47|16@1+ (0.1,0) [0|0] "A" X
 SG_ VCFRONT_PCSState m2: 8|2@1+ (1,0) [0|0] "" X
 SG_ VCFRONT_PCSFault m2: 10|1@1+ (1,0) [0|0] "" X
 SG_ VCFRONT_pcsSelfTestResult m2: 11|4@1+ (1,0) [0|0] "" X
 SG_ VCFRONT_PCSTemp m2: 15|11@1+ (0.125,-40) [0|0] "degC" X
 SG_ VCFRONT_PCSVoltage m2: 31|16@1+ (0.1,0) [0|0] "V" X
 SG_ VCFRONT_PCSCurrent m2: 47|16@1- (0.1,0) [0|0] "A" X
 SG_ VCFRONT_iBoosterState m3: 8|2@1+ (1,0) [0|0] "" X
 SG_ VCFRONT_iBoosterFault m3: 10|1@1+ (1,0) [0|0] "" X
 SG_ VCFRONT_iBoosterSelfTestResult m3: 11|4@1+ (1,0) [0|0] "" X
 SG_ VCFRONT_iBoosterTemp m3: 15|11@1+ (0.125,-40) [0|0] "degC" X
 SG_ VCFRONT_iBoosterVoltage m3: 31|16@1+ (0.1,0) [0|0] "V" X
 SG_ VCFRONT_iBoosterCurrent m3: 47|16@1+ (0.1,0) [0|0] "A" X
 SG_ VCFRONT_EPAS3PState m4: 8|2@1+ (1,0) [0|0] "" X
 SG_ VCFRONT_EPAS3PFault m4: 10|1@1+ (1,0) [0|0] "" X
 SG_ VCFRONT_EPAS3PSelfTestResult m4: 11|4@1+ (1,0) [0|0] "" X
 SG_ VCFRONT_EPAS3PTemp m4: 15|11@1+ (0.125,-40) [0|0] "degC" X
 SG_ VCFRONT_EPAS3PVoltage m4: 31|16@1+ (0.1,0) [0|0] "V" X
 SG_ VCFRONT_EPAS3PCurrent m4: 47|16@1+ (0.1,0) [0|0] "A" X
 SG_ VCFRONT_EPAS3SState m5: 8|2@1+ (1,0) [0|0] "" X
 SG_ VCFRONT_EPAS3SFault m5: 10|1@1+ (1,0) [0|0] "" X
 SG_ VCFRONT_EPAS3SSelfTestResult m5: 11|4@1+ (1,0) [0|0] "" X
 SG_ VCFRONT_EPAS3STemp m5: 15|11@1+ (0.125,-40) [0|0] "degC" X
 SG_ VCFRONT_EPAS3SVoltage m5: 31|16@1+ (0.1,0) [0|0] "V" X
 SG_ VCFRONT_EPAS3SCurrent m5: 47|16@1+ (0.1,0) [0|0] "A" X
 SG_ VCFRONT_ESPMotorState m6: 8|2@1+ (1,0) [0|0] "" X
 SG_ VCFRONT_ESPMotorFault m6: 10|1@1+ (1,0) [0|0] "" X
 SG_ VCFRONT_ESPMotorSelfTestResult m6: 11|4@1+ (1,0) [0|0] "" X
 SG_ VCFRONT_ESPMotorTemp m6: 15|11@1+ (0.125,-40) [0|0] "degC" X
 SG_ VCFRONT_ESPMotorVoltage m6: 31|16@1+ (0.1,0) [0|0] "V" X
 SG_ VCFRONT_ESPMotorCurrent m6: 47|16@1+ (0.1,0) [0|0] "A" X
 SG_ VCFRONT_ESPValveState m7: 8|2@1+ (1,0) [0|0] "" X
 SG_ VCFRONT_ESPValveFault m7: 10|1@1+ (1,0) [0|0] "" X
 SG_ VCFRONT_ESPValveTemp m7: 12|11@1+ (0.125,-40) [0|0] "degC" X
 SG_ VCFRONT_ESPValveVoltage m7: 28|16@1+ (0.1,0) [0|0] "V" X
 SG_ VCFRONT_ESPValveCurrent m7: 44|16@1+ (0.1,0) [0|0] "A" X
 SG_ VCFRONT_autopilot1State m8: 8|2@1+ (1,0) [0|0] "" X
 SG_ VCFRONT_autopilot1Fault m8: 10|1@1+ (1,0) [0|0] "" X
 SG_ VCFRONT_autopilot1Temp m8: 11|11@1+ (0.125,-40) [0|0] "degC" X
 SG_ VCFRONT_autopilot1Voltage m8: 27|16@1+ (0.1,0) [0|0] "V" X
 SG_ VCFRONT_autopilot1Current m8: 43|16@1+ (0.1,0) [0|0] "A" X
 SG_ VCFRONT_autopilot2State m9: 8|2@1+ (1,0) [0|0] "" X
 SG_ VCFRONT_autopilot2Fault m9: 10|1@1+ (1,0) [0|0] "" X
 SG_ VCFRONT_autopilot2Temp m9: 11|11@1+ (0.125,-40) [0|0] "degC" X
 SG_ VCFRONT_autopilot2Voltage m9: 27|16@1+ (0.1,0) [0|0] "V" X
 SG_ VCFRONT_autopilot2Current m9: 43|16@1+ (0.1,0) [0|0] "A" X
 SG_ VCFRONT_sleepBypassState m10: 8|1@1+ (1,0) [0|0] "" X
 SG_ VCFRONT_sleepBypassFault m10: 9|1@1+ (1,0) [0|0] "" X
 SG_ VCFRONT_sleepBypassVoltage m10: 10|16@1+ (0.1,0) [0|0] "V" X
 SG_ VCFRONT_sleepBypassCurrent m10: 26|16@1+ (0.1,0) [0|0] "A" X
 SG_ VCFRONT_uiAudioState m11: 5|1@1+ (1,0) [0|0] "" X
 SG_ VCFRONT_uiAudioFault m11: 6|1@1+ (1,0) [0|0] "" X
 SG_ VCFRONT_uiAudioCurrent m11: 8|16@1+ (0.1,0) [0|0] "A" X
 SG_ VCFRONT_uiState m11: 24|1@1+ (1,0) [0|0] "" X
 SG_ VCFRONT_uiFault m11: 25|1@1+ (1,0) [0|0] "" X
 SG_ VCFRONT_uiCurrent m11: 32|16@1+ (0.1,0) [0|0] "A" X
 SG_ VCFRONT_headlampLeftState m12: 8|1@1+ (1,0) [0|0] "" X
 SG_ VCFRONT_headlampLeftFault m12: 9|1@1+ (1,0) [0|0] "" X
 SG_ VCFRONT_headlampLeftCurrent m12: 10|10@1+ (0.1,0) [0|0] "A" X
 SG_ VCFRONT_headlampLeftVoltage m12: 20|8@1+ (0.1,0) [0|0] "V" X
 SG_ VCFRONT_headlampRightState m12: 28|1@1+ (1,0) [0|0] "" X
 SG_ VCFRONT_headlampRightFault m12: 29|1@1+ (1,0) [0|0] "" X
 SG_ VCFRONT_headlampRightCurrent m12: 30|10@1+ (0.1,0) [0|0] "A" X
 SG_ VCFRONT_headlampRightVoltage m12: 40|8@1+ (0.1,0) [0|0] "V" X
 SG_ VCFRONT_headlampLeftTemperature m12: 48|8@1- (1,-40) [0|0] "degC" X
 SG_ VCFRONT_headlampRightTemperature m12: 56|8@1- (1,-40) [0|0] "degC" X
 SG_ VCFRONT_vbatFusedHighState m13: 8|1@1+ (1,0) [0|0] "" X
 SG_ VCFRONT_vbatFusedHighFault m13: 9|1@1+ (1,0) [0|0] "" X
 SG_ VCFRONT_vbatFusedSelfTestResult m13: 10|4@1+ (1,0) [0|0] "" X
 SG_ VCFRONT_vbatFusedHighTemp m13: 14|11@1+ (0.125,-40) [0|0] "degC" X
 SG_ VCFRONT_vbatFusedHighVoltage m13: 30|16@1+ (0.1,0) [0|0] "V" X
 SG_ VCFRONT_vbatFusedHighCurrent m13: 46|16@1+ (0.1,0) [0|0] "A" X
 SG_ VCFRONT_pump1AndFanState m14: 5|1@1+ (1,0) [0|0] "" X
 SG_ VCFRONT_pump1AndFanCurrent m14: 6|16@1+ (0.1,0) [0|0] "A" X
 SG_ VCFRONT_pump1AndFanVoltage m14: 22|12@1+ (0.1,0) [0|0] "V" X
 SG_ VCFRONT_pump2AndAirCompState m14: 34|1@1+ (1,0) [0|0] "" X
 SG_ VCFRONT_pump2AndAirCompCurrent m14: 35|16@1+ (0.1,0) [0|0] "A" X
 SG_ VCFRONT_pump2AndAirCompVoltage m14: 51|12@1+ (0.1,0) [0|0] "V" X
 SG_ VCFRONT_railA_12v m15: 8|12@1+ (0.00544368,0) [0|0] "V" X
 SG_ VCFRONT_railB_12v m15: 20|12@1+ (0.00544368,0) [0|0] "V" X
 SG_ VCFRONT_railA_5v m15: 32|12@1+ (0.00544368,0) [0|0] "V" X
 SG_ VCFRONT_railB_5v m15: 44|12@1+ (0.00544368,0) [0|0] "V" X
 SG_ VCFRONT_eFuseLockoutVoltage m16: 8|12@1+ (0.00544368,0) [0|0] "V" X
 SG_ VCFRONT_ChargePumpVoltage m16: 24|16@1+ (0.00544368,0) [0|0] "V" X
 SG_ VCFRONT_vbatProt m16: 40|12@1+ (0.00544368,0) [0|0] "V" X

BO_ 769 VCFRONT_info: 8 VEH
 SG_ VCFRONT_infoIndex M: 0|8@1+ (1,0) [0|0] "" X
 SG_ VCFRONT_infoBuildType m10: 8|3@1+ (1,0) [0|0] "" X
 SG_ VCFRONT_infoBuildConfigId m10: 16|16@1+ (1,0) [0|0] "" X
 SG_ VCFRONT_infoHardwareId m10: 32|16@1+ (1,0) [0|0] "" X
 SG_ VCFRONT_infoComponentId m10: 48|16@1+ (1,0) [0|0] "" X
 SG_ VCFRONT_infoPcbaId m11: 8|8@1+ (1,0) [0|0] "" X
 SG_ VCFRONT_infoAssemblyId m11: 16|8@1+ (1,0) [0|0] "" X
 SG_ VCFRONT_infoUsageId m11: 24|16@1+ (1,0) [0|0] "" X
 SG_ VCFRONT_infoSubUsageId m11: 40|16@1+ (1,0) [0|0] "" X
 SG_ VCFRONT_infoAppCrc m13: 8|32@1+ (1,0) [0|0] "" X
 SG_ VCFRONT_hcmlAppCRC m16: 32|32@1+ (1,0) [0|0] "" X
 SG_ VCFRONT_infoAppGitHash m17: 10|54@1+ (4,0) [0|0] "" X
 SG_ VCFRONT_infoBootGitHash m18: 10|54@1+ (4,0) [0|0] "" X
 SG_ VCFRONT_infoPlatformType m19: 8|8@1+ (1,0) [0|0] "" X
 SG_ VCFRONT_infoBootUdsProtoVersion m20: 8|16@1+ (1,0) [0|0] "" X
 SG_ VCFRONT_infoBootCrc m20: 24|32@1+ (1,0) [0|0] "" X
 SG_ VCFRONT_hcmrAppCRC m23: 32|32@1+ (1,0) [0|0] "" X
 SG_ VCFRONT_infoSubcomponent3 m24: 32|32@1+ (1,0) [0|0] "" X
 SG_ VCFRONT_infoSubcomponent4 m31: 32|32@1+ (1,0) [0|0] "" X

BO_ 1009 VCFRONT_lighting: 8 VEH
 SG_ VCFRONT_DRLLeftStatus: 36|2@1+ (1,0) [0|0] "" X
 SG_ VCFRONT_DRLRightStatus: 38|2@1+ (1,0) [0|0] "" X
 SG_ VCFRONT_ambientLightingBrightnes: 8|8@1+ (0.5,0) [0|0] "%" X
 SG_ VCFRONT_approachLightingRequest: 25|1@1+ (1,0) [0|0] "" X
 SG_ VCFRONT_courtesyLightingRequest: 24|1@1+ (1,0) [0|0] "" X
 SG_ VCFRONT_fogLeftStatus: 40|2@1+ (1,0) [0|0] "" X
 SG_ VCFRONT_fogRightStatus: 42|2@1+ (1,0) [0|0] "" X
 SG_ VCFRONT_hazardLightRequest: 4|3@1+ (1,0) [0|0] "" X
 SG_ VCFRONT_hazardSwitchBacklight: 27|1@1+ (1,0) [0|0] "" X
 SG_ VCFRONT_highBeamLeftStatus: 32|2@1+ (1,0) [0|0] "" X
 SG_ VCFRONT_highBeamRightStatus: 34|2@1+ (1,0) [0|0] "" X
 SG_ VCFRONT_highBeamSwitchActive: 58|1@1+ (1,0) [0|0] "" X
 SG_ VCFRONT_indicatorLeftRequest: 0|2@1+ (1,0) [0|0] "" X
 SG_ VCFRONT_indicatorRightRequest: 2|2@1+ (1,0) [0|0] "" X
 SG_ VCFRONT_lowBeamLeftStatus: 28|2@1+ (1,0) [0|0] "" X
 SG_ VCFRONT_lowBeamRightStatus: 30|2@1+ (1,0) [0|0] "" X
 SG_ VCFRONT_lowBeamsCalibrated: 62|1@1+ (1,0) [0|0] "" X
 SG_ VCFRONT_lowBeamsOnForDRL: 61|1@1+ (1,0) [0|0] "" X
 SG_ VCFRONT_parkLeftStatus: 54|2@1+ (1,0) [0|0] "" X
 SG_ VCFRONT_parkRightStatus: 56|2@1+ (1,0) [0|0] "" X
 SG_ VCFRONT_seeYouHomeLightingReq: 26|1@1+ (1,0) [0|0] "" X
 SG_ VCFRONT_sideMarkersStatus: 44|2@1+ (1,0) [0|0] "" X
 SG_ VCFRONT_sideRepeaterLeftStatus: 46|2@1+ (1,0) [0|0] "" X
 SG_ VCFRONT_sideRepeaterRightStatus: 48|2@1+ (1,0) [0|0] "" X
 SG_ VCFRONT_simLatchingStalk: 59|2@1+ (1,0) [0|0] "" X
 SG_ VCFRONT_switchLightingBrightness: 16|8@1+ (0.5,0) [0|0] "%" X
 SG_ VCFRONT_turnSignalLeftStatus: 50|2@1+ (1,0) [0|0] "" X
 SG_ VCFRONT_turnSignalRightStatus: 52|2@1+ (1,0) [0|0] "" X

BO_ 705 VCFRONT_logging10Hz: 8 VEH
 SG_ VCFRONT_logging10HzIndex M : 0|3@1+ (1,0) [0|7] "" X
 SG_ VCFRONT_activeLouverAbnormalKT m4 : 3|1@1+ (1,0) [0|1] "" X
 SG_ VCFRONT_activeLouverCalibRange m4 : 53|8@1+ (1,630) [630|880] "ticks" X
 SG_ VCFRONT_activeLouverCommSuccess m4 : 63|1@1+ (1,0) [0|1] "" X
 SG_ VCFRONT_activeLouverDemand m4 : 32|7@1+ (1,0) [0|100] "%" X
 SG_ VCFRONT_activeLouverDisconnect m4 : 6|1@1+ (1,0) [0|1] "" X
 SG_ VCFRONT_activeLouverFalsStallCal m4 : 62|1@1+ (1,0) [0|1] "" X
 SG_ VCFRONT_activeLouverFalsStallRun m4 : 61|1@1+ (1,0) [0|1] "" X
 SG_ VCFRONT_activeLouverIsCalibrated m4 : 15|1@1+ (1,0) [0|1] "" X
 SG_ VCFRONT_activeLouverMotorCounts m4 : 16|11@1+ (1,-100) [-100|1900] "ticks" X
 SG_ VCFRONT_activeLouverMotorState m4 : 8|3@1+ (1,0) [0|7] "" X
 SG_ VCFRONT_activeLouverOverCurrent m4 : 4|1@1+ (1,0) [0|1] "" X
 SG_ VCFRONT_activeLouverOverTemp m4 : 5|1@1+ (1,0) [0|1] "" X
 SG_ VCFRONT_activeLouverStallCounter m4 : 40|3@1+ (1,0) [0|7] "" X
 SG_ VCFRONT_activeLouverStallLength m4 : 43|10@1+ (1,0) [0|1000] "ticks" X
 SG_ VCFRONT_activeLouverStalled m4 : 7|1@1+ (1,0) [0|1] "" X
 SG_ VCFRONT_activeLouverState m4 : 11|4@1+ (1,0) [0|8] "" X
 SG_ VCFRONT_compLimitDeadband m3 : 8|1@1+ (1,0) [0|1] "" X
 SG_ VCFRONT_compLimitNvh m3 : 6|1@1+ (1,0) [0|1] "" X
 SG_ VCFRONT_compLimitPresDischargeHi m3 : 3|1@1+ (1,0) [0|1] "" X
 SG_ VCFRONT_compLimitScrollSepRamp m3 : 7|1@1+ (1,0) [0|1] "" X
 SG_ VCFRONT_compLimitScrollSepRegion m3 : 5|1@1+ (1,0) [0|1] "" X
 SG_ VCFRONT_compLimitTempDischargeHi m3 : 4|1@1+ (1,0) [0|1] "" X
 SG_ VCFRONT_compLimitTempDischargeSi m3 : 19|1@1+ (1,0) [0|1] "" X
 SG_ VCFRONT_compRampRateUpMax m3 : 20|6@1+ (0.1,0) [0|6] "%/s" X
 SG_ VCFRONT_compStandbyCoastDownMode m3 : 15|1@1+ (1,0) [0|1] "" X
 SG_ VCFRONT_compStandbyCommunication m3 : 10|1@1+ (1,0) [0|1] "" X
 SG_ VCFRONT_compStandbyHVNotReady m3 : 11|1@1+ (1,0) [0|1] "" X
 SG_ VCFRONT_compStandbyHighSuctionSu m3 : 16|1@1+ (1,0) [0|1] "" X
 SG_ VCFRONT_compStandbyLowAmbient m3 : 12|1@1+ (1,0) [0|1] "" X
 SG_ VCFRONT_compStandbyLowDischPress m3 : 13|1@1+ (1,0) [0|1] "" X
 SG_ VCFRONT_compStandbyMultiplePdCut m3 : 17|1@1+ (1,0) [0|1] "" X
 SG_ VCFRONT_compStandbyRefrigNotOk m3 : 14|1@1+ (1,0) [0|1] "" X
 SG_ VCFRONT_compStandbySelfNotReady m3 : 9|1@1+ (1,0) [0|1] "" X
 SG_ VCFRONT_compStandbyShowroomMode m3 : 18|1@1+ (1,0) [0|1] "" X
 SG_ VCFRONT_coolantFlowAmbSourceActu m0 : 48|8@1+ (0.1,0) [0|25] "LPM" X
 SG_ VCFRONT_coolantFlowAmbSourceTarg m0 : 56|8@1+ (0.1,0) [0|25] "LPM" X
 SG_ VCFRONT_coolantTempBasedMode m2 : 3|2@1+ (1,0) [0|3] "" X
 SG_ VCFRONT_coolantValveAngleActual m2 : 8|11@1+ (0.25,-100) [-100|410] "deg" X
 SG_ VCFRONT_coolantValveAngleTarget m2 : 19|10@1+ (0.25,-5) [-5|245] "deg" X
 SG_ VCFRONT_coolantValveAngleTravel m2 : 40|10@1+ (5,0) [0|5000] "deg" X
 SG_ VCFRONT_coolantValveDuty m2 : 32|8@1- (1,0) [-100|100] "%" X
 SG_ VCFRONT_coolantValveISense m2 : 56|7@1+ (0.01,0) [0|1.2] "A" X
 SG_ VCFRONT_coolantValveModeWrong m2 : 5|1@1+ (1,0) [0|1] "" X
 SG_ VCFRONT_coolantValveState m2 : 29|2@1+ (1,0) [0|3] "" X
 SG_ VCFRONT_exvFlow m3 : 32|10@1+ (0.1,0) [0|100] "%" X
 SG_ VCFRONT_exvIsFlooding m3 : 42|1@1+ (1,0) [0|1] "" X
 SG_ VCFRONT_exvMotorState m3 : 28|4@1+ (1,0) [0|10] "" X
 SG_ VCFRONT_exvPrechillActive m3 : 43|1@1+ (1,0) [0|1] "" X
 SG_ VCFRONT_pumpBatSpiError m0 : 46|1@1+ (1,0) [0|1] "" X
 SG_ VCFRONT_pumpBatteryEnabled m0 : 41|1@1+ (1,0) [0|1] "" X
 SG_ VCFRONT_pumpBatteryInitd m0 : 39|1@1+ (1,0) [0|1] "" X
 SG_ VCFRONT_pumpBatteryOutVoltage m0 : 24|7@1+ (0.2,0) [0|20] "V" X
 SG_ VCFRONT_pumpBatteryPowerOn m0 : 43|1@1+ (1,0) [0|1] "" X
 SG_ VCFRONT_pumpBatteryRPMTarget m0 : 3|10@1+ (10,0) [0|10000] "rpm" X
 SG_ VCFRONT_pumpPowertrainEnabled m0 : 42|1@1+ (1,0) [0|1] "" X
 SG_ VCFRONT_pumpPowertrainInitd m0 : 40|1@1+ (1,0) [0|1] "" X
 SG_ VCFRONT_pumpPowertrainOutVoltage m0 : 32|7@1+ (0.2,0) [0|20] "V" X
 SG_ VCFRONT_pumpPowertrainPowerOn m0 : 44|1@1+ (1,0) [0|1] "" X
 SG_ VCFRONT_pumpPowertrainRPMTarget m0 : 13|10@1+ (10,0) [0|10000] "rpm" X
 SG_ VCFRONT_pumpPtSpiError m0 : 47|1@1+ (1,0) [0|1] "" X
 SG_ VCFRONT_pumpsWake m0 : 45|1@1+ (1,0) [0|1] "" X
 SG_ VCFRONT_radarHeaterCurrent m6 : 8|8@1+ (0.1,0) [0|25.5] "A" X
 SG_ VCFRONT_radarHeaterDuty m6 : 16|7@1+ (1,0) [0|100] "%" X
 SG_ VCFRONT_radarHeaterTargetVoltage m6 : 24|8@1+ (0.1,0) [0|16] "V" X
 SG_ VCFRONT_radiatorFanDemandLimit m1 : 48|7@1+ (1,0) [0|100] "%" X
 SG_ VCFRONT_radiatorFanDemandLimited m1 : 47|1@1+ (1,0) [0|1] "" X
 SG_ VCFRONT_radiatorFanEnabled m1 : 27|1@1+ (1,0) [0|1] "" X
 SG_ VCFRONT_radiatorFanInitd m1 : 26|1@1+ (1,0) [0|1] "" X
 SG_ VCFRONT_radiatorFanOutVoltage m1 : 8|7@1+ (0.2,0) [0|20] "V" X
 SG_ VCFRONT_radiatorFanPhaseCurrent m1 : 32|8@1+ (0.25,-10) [-10|50] "A" X
 SG_ VCFRONT_radiatorFanPhaseIMax m1 : 40|7@1+ (0.25,0) [5|35] "A" X
 SG_ VCFRONT_radiatorFanPowerOn m1 : 28|1@1+ (1,0) [0|1] "" X
 SG_ VCFRONT_radiatorFanRPMTarget m1 : 16|10@1+ (10,0) [0|10000] "rpm" X
 SG_ VCFRONT_refrigerantHasBeenFilled m3 : 27|1@1+ (1,0) [0|1] "" X
 SG_ VCFRONT_refrigerantValvesClosed m3 : 26|1@1+ (1,0) [0|1] "" X
 SG_ VCFRONT_solenoidEvapCurrent m3 : 58|6@1+ (0.04,0) [0|2.4] "A" X
 SG_ VCFRONT_subcoolFeedbackFlow m5 : 13|10@1- (0.1,0) [-50|50] "%" X
 SG_ VCFRONT_subcoolFeedforwardFlow m5 : 3|10@1+ (0.1,0) [0|100] "%" X
 SG_ VCFRONT_subcoolProtectionFlow m5 : 24|10@1+ (0.1,0) [0|100] "%" X
 SG_ VCFRONT_subcoolProtectionType m5 : 34|3@1+ (1,0) [0|4] "" X
 SG_ VCFRONT_tempDischargeSimulated m3 : 44|11@1+ (0.125,-40) [-40|150] "C" X
 SG_ VCFRONT_thmlFanSpiError m1 : 55|1@1+ (1,0) [0|1] "" X
 SG_ VCFRONT_usingSimulatedAmbTemp m3 : 57|1@1+ (1,0) [0|1] "" X
 SG_ VCFRONT_usingSimulatedDischTemp m3 : 56|1@1+ (1,0) [0|1] "" X
 SG_ VCFRONT_usingSimulatedSuctTemp m3 : 55|1@1+ (1,0) [0|1] "" X

BO_ 897 VCFRONT_logging1Hz: 8 VEH
 SG_ VCFRONT_logging1HzIndex M : 0|5@1+ (1,0) [0|19] ""  Receiver
 SG_ VCFRONT_CCQdotActual m9 : 21|7@1+ (80,0) [0|10100] "W"  Receiver
 SG_ VCFRONT_CCQdotFdFrwrdTarget m9 : 7|7@1+ (80,0) [0|10100] "W"  Receiver
 SG_ VCFRONT_CCQdotFdbk m9 : 14|7@1- (80,0) [-5000|5000] "W"  Receiver
 SG_ VCFRONT_CMPDischargeSuperheat m8 : 17|5@1- (1,6) [-10|21] "C"  Receiver
 SG_ VCFRONT_DIQdotA m9 : 42|7@1+ (80,0) [0|10000] "W"  Receiver
 SG_ VCFRONT_HCML_bladeTemp m3 : 32|8@1- (1,67) [-60|194] "C"  Receiver
 SG_ VCFRONT_HCML_diffuseTemp m3 : 40|8@1- (1,67) [-60|194] "C"  Receiver
 SG_ VCFRONT_HCML_highBeamTemp m3 : 16|8@1- (1,67) [-60|194] "C"  Receiver
 SG_ VCFRONT_HCML_lowBeamSpotTemp m3 : 8|8@1- (1,67) [-60|194] "C"  Receiver
 SG_ VCFRONT_HCML_turnTemp m3 : 24|8@1- (1,67) [-60|194] "C"  Receiver
 SG_ VCFRONT_HCMR_bladeTemp m4 : 32|8@1- (1,67) [-60|194] "C"  Receiver
 SG_ VCFRONT_HCMR_diffuseTemp m4 : 40|8@1- (1,67) [-60|194] "C"  Receiver
 SG_ VCFRONT_HCMR_highBeamTemp m4 : 16|8@1- (1,67) [-60|194] "C"  Receiver
 SG_ VCFRONT_HCMR_lowBeamSpotTemp m4 : 8|8@1- (1,67) [-60|194] "C"  Receiver
 SG_ VCFRONT_HCMR_turnTemp m4 : 24|8@1- (1,67) [-60|194] "C"  Receiver
 SG_ VCFRONT_PDischargeControllerOutp m14 : 24|8@1+ (0.5,0) [0|100] "%"  Receiver
 SG_ VCFRONT_PSuctionControllerOutput m14 : 40|8@1+ (0.5,0) [0|100] "%"  Receiver
 SG_ VCFRONT_ambientColderThanBatt m16 : 8|1@1+ (1,0) [0|1] ""  Receiver
 SG_ VCFRONT_ambientSourcingAvailable m16 : 9|1@1+ (1,0) [0|1] ""  Receiver
 SG_ VCFRONT_ambientSourcingDisabled m14 : 38|1@1+ (1,0) [0|1] ""  Receiver
 SG_ VCFRONT_battDissipation m12 : 8|8@1+ (140,0) [0|35000] "W"  Receiver
 SG_ VCFRONT_battLoopWorthCooling m16 : 15|1@1+ (1,0) [0|1] ""  Receiver
 SG_ VCFRONT_battOverStagUpperLimit m16 : 6|1@1+ (1,0) [0|1] ""  Receiver
 SG_ VCFRONT_battUnderStagUpperLimit m16 : 7|1@1+ (1,0) [0|1] ""  Receiver
 SG_ VCFRONT_cabinHeatEnergyDuringDri m8 : 42|7@1+ (150,0) [0|19000] "Wh"  Receiver
 SG_ VCFRONT_calibratedPositionHCML m6 : 5|10@1+ (1,0) [0|1023] "Steps"  Receiver
 SG_ VCFRONT_calibratedPositionHCMR m6 : 16|10@1+ (1,0) [0|1023] "Steps"  Receiver
 SG_ VCFRONT_ccLeftExvCalibFailed m11 : 60|1@1+ (1,0) [0|1] ""  Receiver
 SG_ VCFRONT_ccLeftExvCalibOffset m11 : 40|8@1- (4,0) [-510|510] "ticks"  Receiver
 SG_ VCFRONT_ccLeftExvRange m7 : 41|9@1+ (3,0) [0|1500] "ticks"  Receiver
 SG_ VCFRONT_ccRightExvCalibFailed m11 : 61|1@1+ (1,0) [0|1] ""  Receiver
 SG_ VCFRONT_ccRightExvCalibOffset m11 : 48|8@1- (4,0) [-510|510] "ticks"  Receiver
 SG_ VCFRONT_ccRightExvRange m7 : 50|9@1+ (3,0) [0|1500] "ticks"  Receiver
 SG_ VCFRONT_chillerExvCalibFailed m11 : 56|1@1+ (1,0) [0|1] ""  Receiver
 SG_ VCFRONT_chillerExvCalibOffset m11 : 8|8@1- (4,0) [-510|510] "ticks"  Receiver
 SG_ VCFRONT_chillerExvRange m7 : 5|9@1+ (3,0) [0|1500] "ticks"  Receiver
 SG_ VCFRONT_chillerInletTempEstimate m13 : 27|8@1- (1,0) [-40|85] "C"  Receiver
 SG_ VCFRONT_chillerLiftDisabledLowPs m14 : 39|1@1+ (1,0) [0|1] ""  Receiver
 SG_ VCFRONT_chillerPassiveCoolPower m12 : 24|8@1- (60,7560) [0|15000] "W"  Receiver
 SG_ VCFRONT_compEnergyDuringDrive m8 : 35|7@1+ (150,0) [0|19000] "Wh"  Receiver
 SG_ VCFRONT_condenserPressureLimit m1 : 8|6@1+ (0.16,10) [10|20] "bar"  Receiver
 SG_ VCFRONT_coolantLevelVoltage m0 : 55|9@1+ (0.01,0) [0|5] "V"  Receiver
 SG_ VCFRONT_coolantValveAngleDrift m2 : 18|10@1+ (0.25,-127) [-127|127] "degrees"  Receiver
 SG_ VCFRONT_coolantValveCountRange m2 : 8|10@1+ (1,375) [375|1375] "ticks"  Receiver
 SG_ VCFRONT_coolantValveRadBypass m2 : 56|7@1+ (1,0) [0|100] "%"  Receiver
 SG_ VCFRONT_coolantValveRecalCount m2 : 28|16@1+ (1,0) [0|65535] ""  Receiver
 SG_ VCFRONT_coolantValveRecalReason m2 : 5|3@1+ (1,0) [0|6] ""  Receiver
 SG_ VCFRONT_coolantValveWindupEstL m2 : 44|6@1+ (2,0) [0|126] "ticks"  Receiver
 SG_ VCFRONT_coolantValveWindupEstR m2 : 50|6@1+ (2,0) [0|126] "ticks"  Receiver
 SG_ VCFRONT_currentPositionHCML m6 : 26|10@1+ (1,0) [0|1023] "Steps"  Receiver
 SG_ VCFRONT_currentPositionHCMR m6 : 36|10@1+ (1,0) [0|1023] "Steps"  Receiver
 SG_ VCFRONT_cycleModelConverged m10 : 61|1@1+ (1,0) [0|1] ""  Receiver
 SG_ VCFRONT_diDissipation m12 : 16|8@1+ (80,0) [0|20000] "W"  Receiver
 SG_ VCFRONT_dischargePressureTarget m14 : 8|7@1+ (0.25,0) [0|26] "bar"  Receiver
 SG_ VCFRONT_estCompPower m16 : 48|8@1+ (50,0) [0|12750] "W"  Receiver
 SG_ VCFRONT_estCompPressureInlet m16 : 24|8@1+ (0.05,0) [0|12.75] "bar"  Receiver
 SG_ VCFRONT_estCompPressureOutlet m16 : 32|8@1+ (0.1,0) [1|26.5] "bar"  Receiver
 SG_ VCFRONT_estCompRefrigMassflow m16 : 17|7@1+ (2,0) [0|254] "g/s"  Receiver
 SG_ VCFRONT_estCompTempOutlet m16 : 40|8@1+ (1.5,0) [0|190.5] "C"  Receiver
 SG_ VCFRONT_estCompressorRpm m10 : 48|6@1+ (400,0) [0|25200] "rpm"  Receiver
 SG_ VCFRONT_estPressureDisch m10 : 19|7@1+ (0.25,0) [0|31.75] "bar"  Receiver
 SG_ VCFRONT_estPressureLiq m10 : 5|7@1+ (0.25,0) [0|31.75] "bar"  Receiver
 SG_ VCFRONT_estPressureSuct m10 : 12|7@1+ (0.125,0) [0|11.5] "bar"  Receiver
 SG_ VCFRONT_estQLift m10 : 54|7@1+ (100,0) [0|12700] "W"  Receiver
 SG_ VCFRONT_estTempDisch m10 : 40|8@1- (0.8,68.8) [-34|170] "C"  Receiver
 SG_ VCFRONT_estTempLiq m10 : 26|8@1- (0.8,68.8) [-34|170] "C"  Receiver
 SG_ VCFRONT_estTempSuct m10 : 34|6@1- (1,2) [-30|33] "C"  Receiver
 SG_ VCFRONT_evapDisabledLowPsCutout m14 : 15|1@1+ (1,0) [0|1] ""  Receiver
 SG_ VCFRONT_evapExvCalibFailed m11 : 57|1@1+ (1,0) [0|1] ""  Receiver
 SG_ VCFRONT_evapExvCalibOffset m11 : 16|8@1- (4,0) [-510|510] "ticks"  Receiver
 SG_ VCFRONT_evapExvRange m7 : 14|9@1+ (3,0) [0|1500] "ticks"  Receiver
 SG_ VCFRONT_evapFdFrwrdTarget m9 : 28|7@1+ (80,0) [0|10100] "W"  Receiver
 SG_ VCFRONT_evapFdFrwrdTargetMinimum m9 : 49|7@1+ (80,0) [0|10000] "W"  Receiver
 SG_ VCFRONT_evapFdbk m9 : 35|7@1- (80,0) [-5000|5000] "W"  Receiver
 SG_ VCFRONT_exteriorQuietModeAllowed m9 : 6|1@1+ (1,0) [0|1] ""  Receiver
 SG_ VCFRONT_exteriorQuietModeEnabled m9 : 5|1@1+ (1,0) [0|1] ""  Receiver
 SG_ VCFRONT_fanControlFeedfwdActive m15 : 49|1@1+ (1,0) [0|1] ""  Receiver
 SG_ VCFRONT_fanControlRadCanCool m15 : 48|1@1+ (1,0) [0|1] ""  Receiver
 SG_ VCFRONT_fanControlRadiatorInletT m15 : 57|6@1- (1.8,36) [-20|90] "C"  Receiver
 SG_ VCFRONT_fanControlRadiatorUa m15 : 50|7@1+ (8,0) [0|1000] "W/C"  Receiver
 SG_ VCFRONT_fanDemandCondenser m1 : 14|7@1+ (1,0) [0|100] "%"  Receiver
 SG_ VCFRONT_fanDemandRadiator m1 : 21|7@1+ (1,0) [0|100] "%"  Receiver
 SG_ VCFRONT_feedBackDuctTempControll m15 : 32|8@1+ (1,-100) [-100|100] "-"  Receiver
 SG_ VCFRONT_feedBackEvapTempControll m15 : 24|7@1+ (0.01,-0.5) [-0.5|0.5] "-"  Receiver
 SG_ VCFRONT_feedFwdFanDemand m13 : 35|7@1+ (1,0) [0|100] "%"  Receiver
 SG_ VCFRONT_feedFwdMDotCabinCondense m15 : 16|8@1+ (0.005,0) [0|1] "-"  Receiver
 SG_ VCFRONT_feedFwdMDotEvaporator m15 : 8|8@1+ (0.005,0) [0|1] "-"  Receiver
 SG_ VCFRONT_feedFwdPumpDemand m13 : 42|7@1+ (1,0) [0|100] "%"  Receiver
 SG_ VCFRONT_feedfwdLoadCoolingDomina m9 : 59|1@1+ (1,0) [0|1] ""  Receiver
 SG_ VCFRONT_homelinkRegionCode m5 : 8|4@1+ (1,0) [0|9] ""  Receiver
 SG_ VCFRONT_hpAmbientSource m17 : 6|1@1+ (1,0) [0|1] ""  Receiver
 SG_ VCFRONT_hpAtSteadyState m16 : 63|1@1+ (1,0) [0|1] ""  Receiver
 SG_ VCFRONT_hpBattStagTarget m8 : 28|7@1+ (1,-40) [-40|80] "C"  Receiver
 SG_ VCFRONT_hpBatteryCool m17 : 19|1@1+ (1,0) [0|1] ""  Receiver
 SG_ VCFRONT_hpBatteryCoolCabinConden m17 : 20|1@1+ (1,0) [0|1] ""  Receiver
 SG_ VCFRONT_hpBatteryCoolCabinReheat m17 : 21|1@1+ (1,0) [0|1] ""  Receiver
 SG_ VCFRONT_hpBatteryCoolEvaporator m17 : 22|1@1+ (1,0) [0|1] ""  Receiver
 SG_ VCFRONT_hpBatteryHeatAmbientSour m17 : 17|1@1+ (1,0) [0|1] ""  Receiver
 SG_ VCFRONT_hpBatteryHeatCOP1 m17 : 18|1@1+ (1,0) [0|1] ""  Receiver
 SG_ VCFRONT_hpCOP m8 : 22|6@1+ (0.1,0) [0|6] "-"  Receiver
 SG_ VCFRONT_hpCabinCoolEvaporator m17 : 15|1@1+ (1,0) [0|1] ""  Receiver
 SG_ VCFRONT_hpCabinCoolEvaporatorReh m17 : 16|1@1+ (1,0) [0|1] ""  Receiver
 SG_ VCFRONT_hpCabinHeatAmbientSource m17 : 8|1@1+ (1,0) [0|1] ""  Receiver
 SG_ VCFRONT_hpCabinHeatBatteryCoolRe m17 : 14|1@1+ (1,0) [0|1] ""  Receiver
 SG_ VCFRONT_hpCabinHeatBatteryHeatRe m17 : 13|1@1+ (1,0) [0|1] ""  Receiver
 SG_ VCFRONT_hpCabinHeatBlend m17 : 11|1@1+ (1,0) [0|1] ""  Receiver
 SG_ VCFRONT_hpCabinHeatCOP1 m17 : 12|1@1+ (1,0) [0|1] ""  Receiver
 SG_ VCFRONT_hpCabinHeatReheatAmbient m17 : 10|1@1+ (1,0) [0|1] ""  Receiver
 SG_ VCFRONT_hpCabinHeatReheatScaveng m17 : 9|1@1+ (1,0) [0|1] ""  Receiver
 SG_ VCFRONT_hpCabinHeatScavengeOnly m17 : 7|1@1+ (1,0) [0|1] ""  Receiver
 SG_ VCFRONT_hpCompPowerIndex m16 : 56|7@1+ (1,0) [0|127] "-"  Receiver
 SG_ VCFRONT_hpForceScavenge m16 : 5|1@1+ (1,0) [0|1] ""  Receiver
 SG_ VCFRONT_hpGeneral m17 : 5|1@1+ (1,0) [0|1] ""  Receiver
 SG_ VCFRONT_hpMode m16 : 10|5@1+ (1,0) [0|19] ""  Receiver
 SG_ VCFRONT_hpPotentialLowRefrig m9 : 61|1@1+ (1,0) [0|1] ""  Receiver
 SG_ VCFRONT_hpRefrigerantPurgeState m9 : 62|2@1+ (1,0) [0|2] ""  Receiver
 SG_ VCFRONT_hpSubcoolTarget m8 : 12|5@1+ (1,0) [0|31] "C"  Receiver
 SG_ VCFRONT_lccExvCalibFailed m11 : 59|1@1+ (1,0) [0|1] ""  Receiver
 SG_ VCFRONT_lccExvCalibOffset m11 : 32|8@1- (4,0) [-510|510] "ticks"  Receiver
 SG_ VCFRONT_lccExvRange m7 : 32|9@1+ (3,0) [0|1500] "ticks"  Receiver
 SG_ VCFRONT_lccInletTempEstimate m13 : 19|8@1- (1,0) [-40|85] "C"  Receiver
 SG_ VCFRONT_lccPassiveHeatPower m12 : 32|8@1+ (60,0) [0|15000] "W"  Receiver
 SG_ VCFRONT_lowSideLiftEnergyDrive m8 : 49|7@1+ (150,0) [0|19000] "Wh"  Receiver
 SG_ VCFRONT_lowSideWattsLift m8 : 56|7@1+ (60,0) [0|7600] "W"  Receiver
 SG_ VCFRONT_maxAllowedEvapPowerInSer m12 : 40|8@1+ (40,0) [0|10000] "W"  Receiver
 SG_ VCFRONT_maxChillerCoolingPower m15 : 40|8@1+ (100,0) [0|20000] "W"  Receiver
 SG_ VCFRONT_maxCompressorRPMAllowed m14 : 56|7@1+ (90,0) [0|11430] "rpm"  Receiver
 SG_ VCFRONT_minAllowedChillerPowerIn m12 : 48|8@1+ (40,0) [0|10000] "W"  Receiver
 SG_ VCFRONT_minAllowedSuctionPressur m14 : 48|7@1+ (0.02,0) [0|2.5] "bar"  Receiver
 SG_ VCFRONT_minFlowPDCont m14 : 16|8@1+ (0.5,0) [0|100] "%"  Receiver
 SG_ VCFRONT_modeDesired m0 : 14|2@1+ (1,0) [0|3] ""  Receiver
 SG_ VCFRONT_modeTransitionID m0 : 8|6@1+ (1,0) [0|39] ""  Receiver
 SG_ VCFRONT_modelLoadCoolingDominant m9 : 60|1@1+ (1,0) [0|1] ""  Receiver
 SG_ VCFRONT_passiveCoolingState m9 : 56|2@1+ (1,0) [0|3] ""  Receiver
 SG_ VCFRONT_ptLoopWorthCooling m16 : 16|1@1+ (1,0) [0|1] ""  Receiver
 SG_ VCFRONT_pumpBatteryFETTemp m1 : 36|8@1+ (1,-40) [-40|150] "C"  Receiver
 SG_ VCFRONT_pumpPowertrainFETTemp m1 : 44|8@1+ (1,-40) [-40|150] "C"  Receiver
 SG_ VCFRONT_radActiveRejectEstimate m13 : 49|15@1+ (1,0) [0|30000] "W"  Receiver
 SG_ VCFRONT_radPassiveRejectEstimate m13 : 5|14@1+ (1,0) [0|15000] "W"  Receiver
 SG_ VCFRONT_radiatorFanFETTemp m1 : 52|8@1+ (1,-40) [-40|150] "C"  Receiver
 SG_ VCFRONT_radiatorFanRunReason m1 : 60|4@1+ (1,0) [0|8] ""  Receiver
 SG_ VCFRONT_recircExvCalibFailed m11 : 58|1@1+ (1,0) [0|1] ""  Receiver
 SG_ VCFRONT_recircExvCalibOffset m11 : 24|8@1- (4,0) [-510|510] "ticks"  Receiver
 SG_ VCFRONT_recircExvRange m7 : 23|9@1+ (3,0) [0|1500] "ticks"  Receiver
 SG_ VCFRONT_subcoolActual m8 : 5|7@1- (0.4,15.2) [-10|40] "C"  Receiver
 SG_ VCFRONT_suctionPressureTarget m14 : 32|6@1+ (0.15,0) [0|8] "bar"  Receiver
 SG_ VCFRONT_targetBatActiveCool m0 : 32|7@1+ (1,0) [0|100] "C"  Receiver
 SG_ VCFRONT_targetBatActiveHeat m0 : 48|7@1+ (1,-40) [-40|60] "C"  Receiver
 SG_ VCFRONT_targetBatPassive m0 : 40|7@1+ (1,-20) [-20|80] "C"  Receiver
 SG_ VCFRONT_targetPTActiveCool m0 : 16|8@1+ (1,-40) [-40|120] "C"  Receiver
 SG_ VCFRONT_targetPTPassive m0 : 24|8@1+ (1,-40) [-40|120] "C"  Receiver
 SG_ VCFRONT_tempRefrigSuction m1 : 28|8@1+ (0.5,-40) [-40|85] "C"  Receiver
 SG_ VCFRONT_totalLoadCoolingDominant m9 : 58|1@1+ (1,0) [0|1] ""  Receiver
 SG_ VCFRONT_wiperCycles m18 : 48|16@1+ (100,0) [0|6553500] "Cycles"  Receiver

BO_ 721 VCFRONT_okToUseHighPower: 1 VEH
 SG_ VCFRONT_cpOkToUseHighPower: 6|1@1+ (1,0) [0|0] "" X
 SG_ VCFRONT_das1OkToUseHighPower: 2|1@1+ (1,0) [0|0] "" X
 SG_ VCFRONT_das2OkToUseHighPower: 3|1@1+ (1,0) [0|0] "" X
 SG_ VCFRONT_premAudioOkToUseHiPower: 7|1@1+ (1,0) [0|0] "" X
 SG_ VCFRONT_uiAudioOkToUseHighPower: 5|1@1+ (1,0) [0|0] "" X
 SG_ VCFRONT_uiOkToUseHighPower: 4|1@1+ (1,0) [0|0] "" X
 SG_ VCFRONT_vcleftOkToUseHighPower: 0|1@1+ (1,0) [0|0] "" X
 SG_ VCFRONT_vcrightOkToUseHighPower: 1|1@1+ (1,0) [0|0] "" X

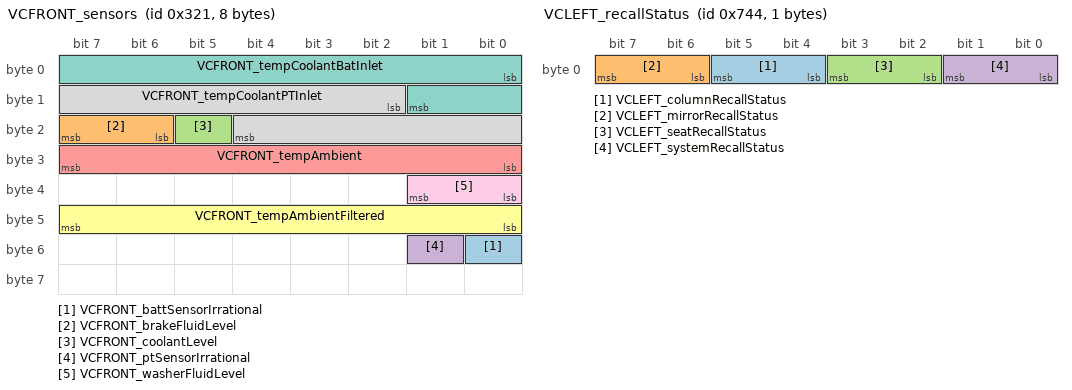
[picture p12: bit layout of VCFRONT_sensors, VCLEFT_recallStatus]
BO_ 801 VCFRONT_sensors: 8 VEH
 SG_ VCFRONT_battSensorIrrational: 48|1@1+ (1,0) [0|0] "" X
 SG_ VCFRONT_brakeFluidLevel: 22|2@1+ (1,0) [0|0] "" X
 SG_ VCFRONT_coolantLevel: 21|1@1+ (1,0) [0|0] "" X
 SG_ VCFRONT_ptSensorIrrational: 49|1@1+ (1,0) [0|0] "" X
 SG_ VCFRONT_tempAmbient: 24|8@1+ (0.5,-40) [0|0] "degC" X
 SG_ VCFRONT_tempAmbientFiltered: 40|8@1+ (0.5,-40) [0|0] "degC" X
 SG_ VCFRONT_tempCoolantBatInlet: 0|10@1+ (0.125,-40) [0|0] "degC" X
 SG_ VCFRONT_tempCoolantPTInlet: 10|11@1+ (0.125,-40) [0|0] "degC" X
 SG_ VCFRONT_washerFluidLevel: 32|2@1+ (1,0) [0|0] "" X

BO_ 737 VCFRONT_status: 8 VEH
 SG_ VCFRONT_statusIndex M : 0|3@1+ (1,0) [0|6] "" X
 SG_ VCFRONT_12VARailStable m5 : 5|1@1+ (1,0) [0|1] "" X
 SG_ VCFRONT_12VBRailStable m5 : 6|1@1+ (1,0) [0|1] "" X
 SG_ VCFRONT_12VOverchargeCounter m4 : 16|4@1+ (1,0) [0|15] "" X
 SG_ VCFRONT_5VARailStable m5 : 3|1@1+ (1,0) [0|1] "" X
 SG_ VCFRONT_5VBRailStable m5 : 4|1@1+ (1,0) [0|1] "" X
 SG_ VCFRONT_AS8510Voltage m5 : 28|12@1+ (0.00544368,0) [0|22.2864] "V" X
 SG_ VCFRONT_ChargePumpVoltageStable m5 : 9|1@1+ (1,0) [0|1] "" X
 SG_ VCFRONT_HSDInitCompleteU13 m5 : 11|1@1+ (1,0) [0|1] "" X
 SG_ VCFRONT_HSDInitCompleteU16 m5 : 12|1@1+ (1,0) [0|1] "" X
 SG_ VCFRONT_IBSFault m4 : 15|1@1+ (1,0) [0|1] "" X
 SG_ VCFRONT_PCSMia m4 : 14|1@1+ (1,0) [0|1] "" X
 SG_ VCFRONT_PEResetLineState m5 : 10|1@1+ (1,0) [0|1] "" X
 SG_ VCFRONT_airCompressorStatus m0 : 25|3@1+ (1,0) [0|7] "" X
 SG_ VCFRONT_anyClosureOpen m0 : 49|1@1+ (1,0) [0|1] "" X
 SG_ VCFRONT_anyDoorOpen m0 : 50|1@1+ (1,0) [0|1] "" X
 SG_ VCFRONT_batterySMState m1 : 16|4@1+ (1,0) [0|8] "" X
 SG_ VCFRONT_chargeNeeded m4 : 13|1@1+ (1,0) [0|1] "" X
 SG_ VCFRONT_chillerDemandActive m3 : 26|1@1+ (1,0) [0|1] "" X
 SG_ VCFRONT_compPerfRecoveryLimited m3 : 27|1@1+ (1,0) [0|1] "" X
 SG_ VCFRONT_coolantFillRoutineStatus m3 : 50|2@1+ (1,0) [0|3] "" X
 SG_ VCFRONT_crashDetectedType m0 : 20|2@1+ (1,0) [0|2] "" X
 SG_ VCFRONT_crashState m0 : 22|2@1+ (1,0) [0|2] "" X
 SG_ VCFRONT_crashUnlockOverrideSet m0 : 24|1@1+ (1,0) [0|1] "" X
 SG_ VCFRONT_epasWakeLine m1 : 4|1@1+ (1,0) [0|1] "" X
 SG_ VCFRONT_freezeEvapITerm m3 : 24|1@1+ (1,0) [0|1] "" X
 SG_ VCFRONT_frunkAccessPost m0 : 62|1@1+ (1,0) [0|1] "" X
 SG_ VCFRONT_frunkInteriorRelSwitch m0 : 48|1@1+ (1,0) [0|1] "" X
 SG_ VCFRONT_frunkLatchStatus m0 : 3|4@1+ (1,0) [0|8] "" X
 SG_ VCFRONT_frunkLatchType m0 : 58|2@1+ (1,0) [0|2] "" X
 SG_ VCFRONT_hasLowRefrigerant m3 : 29|1@1+ (1,0) [0|1] "" X
 SG_ VCFRONT_headlampLeftFanStatus m0 : 60|1@1+ (1,0) [0|1] "" X
 SG_ VCFRONT_headlampRightFanStatus m0 : 61|1@1+ (1,0) [0|1] "" X
 SG_ VCFRONT_headlightLeftVPosition m0 : 28|10@1+ (1,0) [0|1023] "ticks" X
 SG_ VCFRONT_headlightRightVPosition m0 : 38|10@1+ (1,0) [0|1023] "ticks" X
 SG_ VCFRONT_homelinkCommStatus m2 : 48|2@1+ (1,0) [0|3] "" X
 SG_ VCFRONT_homelinkV2Response0 m2 : 8|8@1+ (1,0) [0|255] "" X
 SG_ VCFRONT_homelinkV2Response1 m2 : 16|8@1+ (1,0) [0|255] "" X
 SG_ VCFRONT_homelinkV2Response2 m2 : 24|8@1+ (1,0) [0|255] "" X
 SG_ VCFRONT_homelinkV2Response3 m2 : 32|8@1+ (1,0) [0|255] "" X
 SG_ VCFRONT_homelinkV2Response4 m2 : 40|8@1+ (1,0) [0|255] "" X
 SG_ VCFRONT_hornOn m0 : 51|1@1+ (1,0) [0|1] "" X
 SG_ VCFRONT_hvacPerfTestCommand m3 : 48|2@1+ (1,0) [0|2] "" X
 SG_ VCFRONT_iBoosterStateDBG m1 : 5|3@1+ (1,0) [0|4] "" X
 SG_ VCFRONT_iBoosterWakeLine m1 : 3|1@1+ (1,0) [0|1] "" X
 SG_ VCFRONT_isActiveHeatingBattery m0 : 63|1@1+ (1,0) [0|1] "" X
 SG_ VCFRONT_isColdStartRunning m3 : 30|1@1+ (1,0) [0|1] "" X
 SG_ VCFRONT_isEvapOperationAllowed m3 : 25|1@1+ (1,0) [0|1] "" X
 SG_ VCFRONT_isHeatPumpOilPurgeActive m3 : 31|1@1+ (1,0) [0|1] "" X
 SG_ VCFRONT_maxEvapHeatRejection m3 : 8|8@1+ (65,0) [0|16575] "W" X
 SG_ VCFRONT_minEvapHeatRejection m3 : 16|8@1+ (10,0) [0|2500] "W" X
 SG_ VCFRONT_pressureRefrigDischarge m3 : 40|8@1+ (0.125,0) [0|31.75] "bar" X
 SG_ VCFRONT_pressureRefrigSuction m3 : 32|7@1+ (0.125,0) [0|11.5] "bar" X
 SG_ VCFRONT_radarHeaterState m0 : 52|3@1+ (1,0) [0|4] "" X
 SG_ VCFRONT_railAState m5 : 7|1@1+ (1,0) [0|1] "" X
 SG_ VCFRONT_railBState m5 : 8|1@1+ (1,0) [0|1] "" X
 SG_ VCFRONT_refrigFillRoutineStatus m3 : 52|2@1+ (1,0) [0|3] ""  Receiver
 SG_ VCFRONT_reverseBatteryFault m4 : 30|1@1+ (1,0) [0|1] "" X
 SG_ VCFRONT_shortedCellFaultCounter m4 : 44|3@1+ (1,0) [0|7] "" X
 SG_ VCFRONT_silentWakeIBSCurrent m4 : 32|12@1- (0.1,-204.7) [-409.5|0] "mA" X
 SG_ VCFRONT_sleepCurrent m1 : 32|12@1- (0.1,-204.7) [-409.5|0] "mA" X
 SG_ VCFRONT_tempCompTargetVoltage m4 : 3|10@1+ (0.01,9) [9|16] "V" X
 SG_ VCFRONT_timeSpentSleeping m1 : 24|8@1+ (1,0) [0|255] "s" X
 SG_ VCFRONT_vbatMonitorVoltage m5 : 16|12@1+ (0.00544368,0) [0|22.2864] "V" X
 SG_ VCFRONT_vbatProt m5 : 40|12@1+ (0.00544368,0) [0|22.2919] "V" X
 SG_ VCFRONT_vehicleStatusDBG m1 : 8|5@1+ (1,0) [0|17] "" X
 SG_ VCFRONT_voltageDropCounter m4 : 20|4@1+ (1,0) [0|15] "" X
 SG_ VCFRONT_voltageFloorReachedCount m4 : 24|4@1+ (1,0) [0|15] "" X
 SG_ VCFRONT_voltageProfile m4 : 28|2@1+ (1,0) [0|3] "" X
 SG_ VCFRONT_wiperPosition m0 : 12|3@1+ (1,0) [0|4] "" X
 SG_ VCFRONT_wiperSpeed m0 : 8|4@1+ (1,0) [0|8] "" X
 SG_ VCFRONT_wiperState m0 : 16|4@1+ (1,0) [0|12] "" X

BO_ 929 VCFRONT_vehicleStatus: 8 VEH
 SG_ VCFRONT_12vStatusForDrive: 14|2@1+ (1,0) [0|0] "" X
 SG_ VCFRONT_2RowCenterUnbuckled: 38|2@1+ (1,0) [0|0] "" X
 SG_ VCFRONT_2RowLeftUnbuckled: 36|2@1+ (1,0) [0|0] "" X
 SG_ VCFRONT_2RowRightUnbuckled: 40|2@1+ (1,0) [0|0] "" X
 SG_ VCFRONT_APGlassHeaterState: 2|3@1+ (1,0) [0|0] "" X
 SG_ VCFRONT_LVLoadRequest: 9|1@1+ (1,0) [0|0] "" X
 SG_ VCFRONT_batterySupportRequest: 27|1@1+ (1,0) [0|0] "" X
 SG_ VCFRONT_bmsHvChargeEnable: 0|1@1+ (1,0) [0|0] "" X
 SG_ VCFRONT_diPowerOnState: 10|3@1+ (1,0) [0|0] "" X
 SG_ VCFRONT_driverBuckleStatus: 30|1@1+ (1,0) [0|0] "" X
 SG_ VCFRONT_driverDoorStatus: 31|1@1+ (1,0) [0|0] "" X
 SG_ VCFRONT_driverIsLeaving: 28|1@1+ (1,0) [0|0] "" X
 SG_ VCFRONT_driverIsLeavingAnySpeed: 13|1@1+ (1,0) [0|0] "" X
 SG_ VCFRONT_driverUnbuckled: 32|2@1+ (1,0) [0|0] "" X
 SG_ VCFRONT_is12VBatterySupported: 5|1@1+ (1,0) [0|0] "" X
 SG_ VCFRONT_ota12VSupportRequest: 29|1@1+ (1,0) [0|0] "" X
 SG_ VCFRONT_passengerUnbuckled: 34|2@1+ (1,0) [0|0] "" X
 SG_ VCFRONT_pcs12vVoltageTarget: 16|11@1+ (0.01,0) [0|0] "V" X
 SG_ VCFRONT_pcsEFuseVoltage: 42|10@1+ (0.1,0) [0|0] "V" X
 SG_ VCFRONT_preconditionRequest: 1|1@1+ (1,0) [0|0] "" X
 SG_ VCFRONT_standbySupplySupported : 6|1@1+ (1,0) [0|1] "" X
 SG_ VCFRONT_thermalSystemType : 5|1@1+ (1,0) [0|1] "" X
 SG_ VCFRONT_vehicleStatusChecksum: 56|8@1+ (1,0) [0|0] "" X
 SG_ VCFRONT_vehicleStatusCounter: 52|4@1+ (1,0) [0|0] "" X

BO_ 864 VCLEFT_alertMatrix: 8 VEH
 SG_ VCLEFT_matrixIndex M: 0|4@1+ (1,0) [0|0] "" X
 SG_ VCLEFT_a001_WatchdogReset m0: 4|1@1+ (1,0) [0|0] "" X
 SG_ VCLEFT_a002_PowerLossReset m0: 5|1@1+ (1,0) [0|0] "" X
 SG_ VCLEFT_a003_SWAssertion m0: 6|1@1+ (1,0) [0|0] "" X
 SG_ VCLEFT_a010_ExtSupplyVoltError m0: 13|1@1+ (1,0) [0|0] "" X
 SG_ VCLEFT_a012_CPUReset m0: 15|1@1+ (1,0) [0|0] "" X
 SG_ VCLEFT_a013_AlertManagerFault m0: 16|1@1+ (1,0) [0|0] "" X
 SG_ VCLEFT_a015_NVMMAlert m0: 18|1@1+ (1,0) [0|0] "" X
 SG_ VCLEFT_a021_TaskSchedulerError m0: 24|1@1+ (1,0) [0|0] "" X
 SG_ VCLEFT_a022_TaskInitError m0: 25|1@1+ (1,0) [0|0] "" X
 SG_ VCLEFT_a031_UDSActive m0: 34|1@1+ (1,0) [0|0] "" X
 SG_ VCLEFT_a041_HighCPULoad m0: 44|1@1+ (1,0) [0|0] "" X
 SG_ VCLEFT_a042_HighStackUsage m0: 45|1@1+ (1,0) [0|0] "" X
 SG_ VCLEFT_a043_Task1msError m0: 46|1@1+ (1,0) [0|0] "" X
 SG_ VCLEFT_a044_Task10msError m0: 47|1@1+ (1,0) [0|0] "" X
 SG_ VCLEFT_a045_Task100msError m0: 48|1@1+ (1,0) [0|0] "" X
 SG_ VCLEFT_a046_Task1000msError m0: 49|1@1+ (1,0) [0|0] "" X
 SG_ VCLEFT_a059_inputResistanceHigh m0: 62|1@1+ (1,0) [0|0] "" X
 SG_ VCLEFT_a060_engineeringBuild m0: 63|1@1+ (1,0) [0|0] "" X
 SG_ VCLEFT_a061_XCPConnected m1: 4|1@1+ (1,0) [0|0] "" X
 SG_ VCLEFT_a062_XCPWasConnected m1: 5|1@1+ (1,0) [0|0] "" X
 SG_ VCLEFT_a063_SwitchFault m1: 6|1@1+ (1,0) [0|0] "" X
 SG_ VCLEFT_a064_busSleepReqTimeout m1: 7|1@1+ (1,0) [0|0] "" X
 SG_ VCLEFT_a097_CMP_MIA m1: 40|1@1+ (1,0) [0|0] "" X
 SG_ VCLEFT_a098_DI_THERMAL_MIA m1: 41|1@1+ (1,0) [0|0] "" X
 SG_ VCLEFT_a099_PARK_MIA m1: 42|1@1+ (1,0) [0|0] "" X
 SG_ VCLEFT_a100_CANbus_MIA m1: 43|1@1+ (1,0) [0|0] "" X
 SG_ VCLEFT_a101_PM_MIA m1: 44|1@1+ (1,0) [0|0] "" X
 SG_ VCLEFT_a102_PTC_MIA m1: 45|1@1+ (1,0) [0|0] "" X
 SG_ VCLEFT_a103_CP_MIA m1: 46|1@1+ (1,0) [0|0] "" X
 SG_ VCLEFT_a104_DAS_MIA m1: 47|1@1+ (1,0) [0|0] "" X
 SG_ VCLEFT_a105_TAS_MIA m1: 48|1@1+ (1,0) [0|0] "" X
 SG_ VCLEFT_a106_PCS_MIA m1: 49|1@1+ (1,0) [0|0] "" X
 SG_ VCLEFT_a107_BMS_MIA m1: 50|1@1+ (1,0) [0|0] "" X
 SG_ VCLEFT_a108_DIS_MIA m1: 51|1@1+ (1,0) [0|0] "" X
 SG_ VCLEFT_a109_RCM_MIA m1: 52|1@1+ (1,0) [0|0] "" X
 SG_ VCLEFT_a110_GTW_MIA m1: 53|1@1+ (1,0) [0|0] "" X
 SG_ VCLEFT_a111_EPBR_MIA m1: 54|1@1+ (1,0) [0|0] "" X
 SG_ VCLEFT_a112_EPBL_MIA m1: 55|1@1+ (1,0) [0|0] "" X
 SG_ VCLEFT_a113_UI_MIA m1: 56|1@1+ (1,0) [0|0] "" X
 SG_ VCLEFT_a114_ESP_MIA m1: 57|1@1+ (1,0) [0|0] "" X
 SG_ VCLEFT_a115_VCSEC_MIA m1: 58|1@1+ (1,0) [0|0] "" X
 SG_ VCLEFT_a116_VCRIGHT_MIA m1: 59|1@1+ (1,0) [0|0] "" X
 SG_ VCLEFT_a117_VCLEFT_MIA m1: 60|1@1+ (1,0) [0|0] "" X
 SG_ VCLEFT_a118_VCFRONT_MIA m1: 61|1@1+ (1,0) [0|0] "" X
 SG_ VCLEFT_a119_SCCM_MIA m1: 62|1@1+ (1,0) [0|0] "" X
 SG_ VCLEFT_a120_DI_DRIVE_MIA m1: 63|1@1+ (1,0) [0|0] "" X
 SG_ VCLEFT_a129_blowerICLatchFault m2: 12|1@1+ (1,0) [0|0] "" X
 SG_ VCLEFT_a130_blowerICWarning m2: 13|1@1+ (1,0) [0|0] "" X
 SG_ VCLEFT_a131_blowerICTransFault m2: 14|1@1+ (1,0) [0|0] "" X
 SG_ VCLEFT_a132_blowerSoftStall m2: 15|1@1+ (1,0) [0|0] "" X
 SG_ VCLEFT_a133_blowerLowRPMCBang m2: 16|1@1+ (1,0) [0|0] "" X
 SG_ VCLEFT_a134_SteerColUpDownUnCal m2: 17|1@1+ (1,0) [0|0] "" X
 SG_ VCLEFT_a135_SteerColInOutUnCal m2: 18|1@1+ (1,0) [0|0] "" X
 SG_ VCLEFT_a136_brakeSwitchMismatch m2: 19|1@1+ (1,0) [0|0] "" X
 SG_ VCLEFT_a137_VCSECPowerCycled m2: 20|1@1+ (1,0) [0|0] "" X
 SG_ VCLEFT_a138_consoleDoorAssist m2: 21|1@1+ (1,0) [0|0] "" X
 SG_ VCLEFT_a139_BLERearPowerCycled m2: 22|1@1+ (1,0) [0|0] "" X
 SG_ VCLEFT_a140_BLELeftPowerCycled m2: 23|1@1+ (1,0) [0|0] "" X
 SG_ VCLEFT_a141_12VAuxPowerTrip m2: 24|1@1+ (1,0) [0|0] "" X
 SG_ VCLEFT_a150_windowPinchFront m2: 33|1@1+ (1,0) [0|0] "" X
 SG_ VCLEFT_a151_windowPinchRear m2: 34|1@1+ (1,0) [0|0] "" X
 SG_ VCLEFT_a152_windowUncalFront m2: 35|1@1+ (1,0) [0|0] "" X
 SG_ VCLEFT_a153_windowUncalRear m2: 36|1@1+ (1,0) [0|0] "" X
 SG_ VCLEFT_a154_windowThermalFront m2: 37|1@1+ (1,0) [0|0] "" X
 SG_ VCLEFT_a155_windowThermalRear m2: 38|1@1+ (1,0) [0|0] "" X
 SG_ VCLEFT_a156_windowNoInputFront m2: 39|1@1+ (1,0) [0|0] "" X
 SG_ VCLEFT_a157_windowNoInputRear m2: 40|1@1+ (1,0) [0|0] "" X
 SG_ VCLEFT_a158_windowPinchOverideF m2: 41|1@1+ (1,0) [0|0] "" X
 SG_ VCLEFT_a159_windowPinchOverideR m2: 42|1@1+ (1,0) [0|0] "" X
 SG_ VCLEFT_a160_windowUndercurrentF m2: 43|1@1+ (1,0) [0|0] "" X
 SG_ VCLEFT_a161_windowUndercurrentR m2: 44|1@1+ (1,0) [0|0] "" X
 SG_ VCLEFT_a162_windowEncoderStallF m2: 45|1@1+ (1,0) [0|0] "" X
 SG_ VCLEFT_a163_windowEncoderStallR m2: 46|1@1+ (1,0) [0|0] "" X
 SG_ VCLEFT_a164_windowFactoryTest m2: 47|1@1+ (1,0) [0|0] "" X
 SG_ VCLEFT_a165_windowFactoryTest2 m2: 48|1@1+ (1,0) [0|0] "" X
 SG_ VCLEFT_a166_windowDebug m2: 49|1@1+ (1,0) [0|0] "" X
 SG_ VCLEFT_a167_windowDebugPinchF m2: 50|1@1+ (1,0) [0|0] "" X
 SG_ VCLEFT_a168_windowDebugPinchR m2: 51|1@1+ (1,0) [0|0] "" X
 SG_ VCLEFT_a169_windowCurrentPeakF m2: 52|1@1+ (1,0) [0|0] "" X
 SG_ VCLEFT_a170_windowCurrentPeakR m2: 53|1@1+ (1,0) [0|0] "" X
 SG_ VCLEFT_a172_SPI_MIA m2: 55|1@1+ (1,0) [0|0] "" X
 SG_ VCLEFT_a180_frontDoorLatchRehome m2: 63|1@1+ (1,0) [0|0] "" X
 SG_ VCLEFT_a181_rearDoorLatchRehome m3: 4|1@1+ (1,0) [0|0] "" X
 SG_ VCLEFT_a182_emergencyLatchRel m3: 5|1@1+ (1,0) [0|0] "" X
 SG_ VCLEFT_a183_doorStateFactoryTest m3: 6|1@1+ (1,0) [0|0] "" X
 SG_ VCLEFT_a185_summonAborted m3: 8|1@1+ (1,0) [0|0] "" X
 SG_ VCLEFT_a186_latchReleaseFailedF m3: 9|1@1+ (1,0) [0|0] "" X
 SG_ VCLEFT_a187_latchReleaseFailedR m3: 10|1@1+ (1,0) [0|0] "" X
 SG_ VCLEFT_a188_latchUnableToRearmF m3: 11|1@1+ (1,0) [0|0] "" X
 SG_ VCLEFT_a189_latchUnableToRearmR m3: 12|1@1+ (1,0) [0|0] "" X
 SG_ VCLEFT_a190_eFuseMgmtVbatFused m3: 13|1@1+ (1,0) [0|0] "" X
 SG_ VCLEFT_a191_TLCOvercurrent m3: 14|1@1+ (1,0) [0|0] "" X
 SG_ VCLEFT_a196_VEHCANOverterminate m3: 19|1@1+ (1,0) [0|0] "" X
 SG_ VCLEFT_a197_VEHCANUndertrminate m3: 20|1@1+ (1,0) [0|0] "" X
 SG_ VCLEFT_a200_motorPhantomEncoder m3: 23|1@1+ (1,0) [0|0] "" X
 SG_ VCLEFT_a201_motorDutyEncDisabl m3: 24|1@1+ (1,0) [0|0] "" X
 SG_ VCLEFT_a202_epbmUnderIStatic m3: 25|1@1+ (1,0) [0|0] "" X
 SG_ VCLEFT_a203_epbmOverIStatic m3: 26|1@1+ (1,0) [0|0] "" X
 SG_ VCLEFT_a204_epbmUnderIDyn m3: 27|1@1+ (1,0) [0|0] "" X
 SG_ VCLEFT_a205_epbmOverIDyn m3: 28|1@1+ (1,0) [0|0] "" X
 SG_ VCLEFT_a206_epbWrongDirection m3: 29|1@1+ (1,0) [0|0] "" X
 SG_ VCLEFT_a207_epbmEnableWrong m3: 30|1@1+ (1,0) [0|0] "" X
 SG_ VCLEFT_a208_epbFaulted m3: 31|1@1+ (1,0) [0|0] "" X
 SG_ VCLEFT_a209_epbStateMisTime m3: 32|1@1+ (1,0) [0|0] "" X
 SG_ VCLEFT_a210_epbStateTime m3: 33|1@1+ (1,0) [0|0] "" X
 SG_ VCLEFT_a211_epbmUnderIStaticNew m3: 34|1@1+ (1,0) [0|0] "" X
 SG_ VCLEFT_a212_epbmOverIStaticNew m3: 35|1@1+ (1,0) [0|0] "" X
 SG_ VCLEFT_a213_epbmUnderIDynNew m3: 36|1@1+ (1,0) [0|0] "" X
 SG_ VCLEFT_a214_epbmOverIDynNew m3: 37|1@1+ (1,0) [0|0] "" X
 SG_ VCLEFT_a215_currentDesyncWarning m3: 38|1@1+ (1,0) [0|0] "" X
 SG_ VCLEFT_a216_SPI_MIA_debugData1 m3: 39|1@1+ (1,0) [0|0] "" X
 SG_ VCLEFT_a217_SPI_MIA_debugData2 m3: 40|1@1+ (1,0) [0|0] "" X
 SG_ VCLEFT_a218_motorDriverFault m3: 41|1@1+ (1,0) [0|0] "" X
 SG_ VCLEFT_a219_motorCurrentDropout m3: 42|1@1+ (1,0) [0|0] "" X
 SG_ VCLEFT_a220_seatCurrStallTrack m3: 43|1@1+ (1,0) [0|0] "" X
 SG_ VCLEFT_a221_seatCurrStallBack m3: 44|1@1+ (1,0) [0|0] "" X
 SG_ VCLEFT_a222_seatCurrStallTilt m3: 45|1@1+ (1,0) [0|0] "" X
 SG_ VCLEFT_a223_seatCurrStallLift m3: 46|1@1+ (1,0) [0|0] "" X
 SG_ VCLEFT_a224_seatEncStallTrack m3: 47|1@1+ (1,0) [0|0] "" X
 SG_ VCLEFT_a225_seatEncStallBack m3: 48|1@1+ (1,0) [0|0] "" X
 SG_ VCLEFT_a226_seatEncStallTilt m3: 49|1@1+ (1,0) [0|0] "" X
 SG_ VCLEFT_a227_seatEncStallLift m3: 50|1@1+ (1,0) [0|0] "" X
 SG_ VCLEFT_a228_seatEncOverTrack m3: 51|1@1+ (1,0) [0|0] "" X
 SG_ VCLEFT_a229_seatEncOverBack m3: 52|1@1+ (1,0) [0|0] "" X
 SG_ VCLEFT_a230_seatEncOverTilt m3: 53|1@1+ (1,0) [0|0] "" X
 SG_ VCLEFT_a231_seatEncOverLift m3: 54|1@1+ (1,0) [0|0] "" X
 SG_ VCLEFT_a232_seatCurrUnderTrack m3: 55|1@1+ (1,0) [0|0] "" X
 SG_ VCLEFT_a233_seatCurrUnderBack m3: 56|1@1+ (1,0) [0|0] "" X
 SG_ VCLEFT_a234_seatCurrUnderTilt m3: 57|1@1+ (1,0) [0|0] "" X
 SG_ VCLEFT_a235_seatCurrUnderLift m3: 58|1@1+ (1,0) [0|0] "" X
 SG_ VCLEFT_a236_lumbarOverPresA m3: 59|1@1+ (1,0) [0|0] "" X
 SG_ VCLEFT_a237_lumbarOverPresB m3: 60|1@1+ (1,0) [0|0] "" X
 SG_ VCLEFT_a238_lumbarValveMIA m3: 61|1@1+ (1,0) [0|0] "" X
 SG_ VCLEFT_a239_seatHeatIFront m3: 62|1@1+ (1,0) [0|0] "" X
 SG_ VCLEFT_a240_seatHeatShortFront m3: 63|1@1+ (1,0) [0|0] "" X
 SG_ VCLEFT_a241_seatHeatMIAFront m4: 4|1@1+ (1,0) [0|0] "" X
 SG_ VCLEFT_a242_seatHeatIRearL m4: 5|1@1+ (1,0) [0|0] "" X
 SG_ VCLEFT_a243_seatHeatShortRearL m4: 6|1@1+ (1,0) [0|0] "" X
 SG_ VCLEFT_a244_seatHeatMIARearL m4: 7|1@1+ (1,0) [0|0] "" X
 SG_ VCLEFT_a251_seatUncalTrack m4: 14|1@1+ (1,0) [0|0] "" X
 SG_ VCLEFT_a252_seatUncalBack m4: 15|1@1+ (1,0) [0|0] "" X
 SG_ VCLEFT_a253_seatUncalTilt m4: 16|1@1+ (1,0) [0|0] "" X
 SG_ VCLEFT_a254_seatUncalLift m4: 17|1@1+ (1,0) [0|0] "" X
 SG_ VCLEFT_a259_latchDisarmDelayF m4: 22|1@1+ (1,0) [0|0] "" X
 SG_ VCLEFT_a260_latchDisarmDelayR m4: 23|1@1+ (1,0) [0|0] "" X
 SG_ VCLEFT_a263_seatTrackStallDebug m4: 26|1@1+ (1,0) [0|0] "" X
 SG_ VCLEFT_a264_seatBackStallDebug m4: 27|1@1+ (1,0) [0|0] "" X
 SG_ VCLEFT_a265_seatTiltStallDebug m4: 28|1@1+ (1,0) [0|0] "" X
 SG_ VCLEFT_a266_seatLiftStallDebug m4: 29|1@1+ (1,0) [0|0] "" X
 SG_ VCLEFT_a267_seatTrackHCEncStlDbg m4: 30|1@1+ (1,0) [0|0] "" X
 SG_ VCLEFT_a268_seatBackHCEncStlDbg m4: 31|1@1+ (1,0) [0|0] "" X
 SG_ VCLEFT_a269_seatTiltHCEncStlDbg m4: 32|1@1+ (1,0) [0|0] "" X
 SG_ VCLEFT_a270_seatLiftHCEncStlDbg m4: 33|1@1+ (1,0) [0|0] "" X
 SG_ VCLEFT_a272_vhclPwrStateMsmtch m4: 35|1@1+ (1,0) [0|0] "" X
 SG_ VCLEFT_a273_handleStuckActiveF m4: 36|1@1+ (1,0) [0|0] "" X
 SG_ VCLEFT_a274_handleStuckActiveR m4: 37|1@1+ (1,0) [0|0] "" X
 SG_ VCLEFT_a275_leftTurnLightFault m4: 38|1@1+ (1,0) [0|0] "" X
 SG_ VCLEFT_a276_mirrorDebug m4: 39|1@1+ (1,0) [0|0] "" X
 SG_ VCLEFT_a277_BLELeftUnderVoltage m4: 40|1@1+ (1,0) [0|0] "" X
 SG_ VCLEFT_a278_BLERearUnderVoltage m4: 41|1@1+ (1,0) [0|0] "" X
 SG_ VCLEFT_a279_VCSECUnderVoltage m4: 42|1@1+ (1,0) [0|0] "" X
 SG_ VCLEFT_a280_latchDidNotDisarmF m4: 43|1@1+ (1,0) [0|0] "" X
 SG_ VCLEFT_a281_latchDidNotDisarmR m4: 44|1@1+ (1,0) [0|0] "" X
 SG_ VCLEFT_a282_latchUnexpectedArmF m4: 45|1@1+ (1,0) [0|0] "" X
 SG_ VCLEFT_a283_latchUnexpectedArmR m4: 46|1@1+ (1,0) [0|0] "" X
 SG_ VCLEFT_a284_blowerFbkSanity m4: 47|1@1+ (1,0) [0|0] "" X
 SG_ VCLEFT_a285_blowerChipComms m4: 48|1@1+ (1,0) [0|0] "" X
 SG_ VCLEFT_a286_windowSpeedInvalidF m4: 49|1@1+ (1,0) [0|0] "" X
 SG_ VCLEFT_a287_windowSpeedInvalidR m4: 50|1@1+ (1,0) [0|0] "" X
 SG_ VCLEFT_a290_occupancyFaultedFront m4: 53|1@1+ (1,0) [0|0] "" X
 SG_ VCLEFT_a291_buckleFaultedFront m4: 54|1@1+ (1,0) [0|0] "" X
 SG_ VCLEFT_a292_occupancyFaultedRearL m4: 55|1@1+ (1,0) [0|0] "" X
 SG_ VCLEFT_a293_occupancyFaultedRearC m4: 56|1@1+ (1,0) [0|0] "" X
 SG_ VCLEFT_a294_occupancyFaultedRearR m4: 57|1@1+ (1,0) [0|0] "" X
 SG_ VCLEFT_a295_buckleFaultedRearL m4: 58|1@1+ (1,0) [0|0] "" X
 SG_ VCLEFT_a300_swcUnderVoltage m4: 63|1@1+ (1,0) [0|0] "" X
 SG_ VCLEFT_a301_swcOverVoltage m5: 4|1@1+ (1,0) [0|0] "" X
 SG_ VCLEFT_a302_blowerGeneralFault m5: 5|1@1+ (1,0) [0|0] "" X
 SG_ VCLEFT_a303_eFuseMgmtWindowLift m5: 6|1@1+ (1,0) [0|0] "" X
 SG_ VCLEFT_a304_frontIntHandleShorted m5: 7|1@1+ (1,0) [0|0] "" X
 SG_ VCLEFT_a305_rearIntHandleShorted m5: 8|1@1+ (1,0) [0|0] "" X
 SG_ VCLEFT_a306_handleDisconnectedF m5: 9|1@1+ (1,0) [0|0] "" X
 SG_ VCLEFT_a307_handleDisconnectedR m5: 10|1@1+ (1,0) [0|0] "" X

BO_ 258 VCLEFT_doorStatus: 8 VEH
 SG_ VCLEFT_frontHandlePWM: 16|7@1+ (1,0) [0|0] "%" X
 SG_ VCLEFT_frontHandlePulled: 10|1@1+ (1,0) [0|0] "" X
 SG_ VCLEFT_frontHandlePulledPersist: 62|1@1+ (1,0) [0|0] "" X
 SG_ VCLEFT_frontIntSwitchPressed: 31|1@1+ (1,0) [0|0] "" X
 SG_ VCLEFT_frontLatchStatus: 0|4@1+ (1,0) [0|0] "" X
 SG_ VCLEFT_frontLatchSwitch: 8|1@1+ (1,0) [0|0] "" X
 SG_ VCLEFT_frontRelActuatorSwitch: 12|1@1+ (1,0) [0|0] "" X
 SG_ VCLEFT_mirrorDipped: 61|1@1+ (1,0) [0|0] "" X
 SG_ VCLEFT_mirrorFoldState: 52|3@1+ (1,0) [0|0] "" X
 SG_ VCLEFT_mirrorHeatState: 58|3@1+ (1,0) [0|0] "" X
 SG_ VCLEFT_mirrorRecallState: 55|3@1+ (1,0) [0|0] "" X
 SG_ VCLEFT_mirrorState: 49|3@1+ (1,0) [0|0] "" X
 SG_ VCLEFT_mirrorTiltXPosition: 33|8@1+ (0.02,0) [0|0] "V" X
 SG_ VCLEFT_mirrorTiltYPosition: 41|8@1+ (0.02,0) [0|0] "V" X
 SG_ VCLEFT_rearHandlePWM: 24|7@1+ (1,0) [0|0] "%" X
 SG_ VCLEFT_rearHandlePulled: 11|1@1+ (1,0) [0|0] "" X
 SG_ VCLEFT_rearIntSwitchPressed: 32|1@1+ (1,0) [0|0] "" X
 SG_ VCLEFT_rearLatchStatus: 4|4@1+ (1,0) [0|0] "" X
 SG_ VCLEFT_rearLatchSwitch: 9|1@1+ (1,0) [0|0] "" X
 SG_ VCLEFT_rearRelActuatorSwitch: 13|1@1+ (1,0) [0|0] "" X

BO_ 626 VCLEFT_epbmDebug: 8 VEH
 SG_ VCLEFT_epbmDebugIndex M: 0|1@1+ (1,0) [0|0] "" X
 SG_ VCLEFT_epbmCaliperState m0: 1|3@1+ (1,0) [0|0] "" X
 SG_ VCLEFT_epbmMotorEnabled m0: 4|1@1+ (1,0) [0|0] "" X
 SG_ VCLEFT_epbMotorCurrent m0: 5|11@1+ (0.01,0) [0|0] "A" X
 SG_ VCLEFT_epbmApplyVoltage m0: 16|11@1+ (0.01,0) [0|0] "A" X
 SG_ VCLEFT_epbmReleaseVoltage m0: 27|11@1+ (0.01,0) [0|0] "A" X
 SG_ VCLEFT_summonFaultReason m0: 38|5@1+ (1,0) [0|0] "" X
 SG_ VCLEFT_epbSummonState m0: 43|3@1+ (1,0) [0|0] "" X
 SG_ VCLEFT_epbmSummonState m0: 46|3@1+ (1,0) [0|0] "" X
 SG_ VCLEFT_epbmUnitStatus m0: 49|5@1+ (1,0) [0|0] "" X
 SG_ VCLEFT_epbUnitStatus m0: 54|5@1+ (1,0) [0|0] "" X
 SG_ VCLEFT_epbmFaultStatus m0: 59|2@1+ (1,0) [0|0] "" X
 SG_ VCLEFT_epbFaultStatus m0: 61|2@1+ (1,0) [0|0] "" X
 SG_ VCLEFT_epbmOpenAllowed m1: 1|1@1+ (1,0) [0|0] "" X
 SG_ VCLEFT_epbmDynamicAllowed m1: 2|1@1+ (1,0) [0|0] "" X
 SG_ VCLEFT_epbmParkAllowed m1: 3|1@1+ (1,0) [0|0] "" X
 SG_ VCLEFT_epbmStartAllowed m1: 4|1@1+ (1,0) [0|0] "" X
 SG_ VCLEFT_epbmServiceAllowed m1: 5|1@1+ (1,0) [0|0] "" X
 SG_ VCLEFT_epbmWinchAllowed m1: 6|1@1+ (1,0) [0|0] "" X
 SG_ VCLEFT_epbmWinchReleaseAllowed m1: 7|1@1+ (1,0) [0|0] "" X
 SG_ VCLEFT_epbmParkingAllowed m1: 8|1@1+ (1,0) [0|0] "" X
 SG_ VCLEFT_epbmDynApplyingAllowed m1: 9|1@1+ (1,0) [0|0] "" X
 SG_ VCLEFT_epbmReleasingAllowed m1: 10|1@1+ (1,0) [0|0] "" X
 SG_ VCLEFT_epbmFaultAllowed m1: 11|1@1+ (1,0) [0|0] "" X
 SG_ VCLEFT_epbmSummonAllowed m1: 12|1@1+ (1,0) [0|0] "" X
 SG_ VCLEFT_epbmSummonParkAllowed m1: 13|1@1+ (1,0) [0|0] "" X
 SG_ VCLEFT_epbmSummonReleaseAllowed m1: 14|1@1+ (1,0) [0|0] "" X
 SG_ VCLEFT_summonInitAllowed m1: 15|1@1+ (1,0) [0|0] "" X
 SG_ VCLEFT_epbmUnknownAllowed m1: 16|1@1+ (1,0) [0|0] "" X
 SG_ VCLEFT_summonIdleAllowed m1: 17|1@1+ (1,0) [0|0] "" X
 SG_ VCLEFT_summonArmedAllowed m1: 18|1@1+ (1,0) [0|0] "" X
 SG_ VCLEFT_summonActiveAllowed m1: 19|1@1+ (1,0) [0|0] "" X
 SG_ VCLEFT_summonCompleteAllowed m1: 20|1@1+ (1,0) [0|0] "" X
 SG_ VCLEFT_summonFaultAllowed m1: 21|1@1+ (1,0) [0|0] "" X
 SG_ VCLEFT_summonUnavailableAllowed m1: 22|1@1+ (1,0) [0|0] "" X
 SG_ VCLEFT_cdpEnumDummy m1: 24|2@1+ (1,0) [0|0] "" X

BO_ 642 VCLEFT_hvacBlowerFeedback: 8 VEH
 SG_ VCLEFT_blowerIndex M: 0|2@1+ (1,0) [0|0] "" X
 SG_ VCLEFT_hvacBlowerEnabled m0: 2|1@1+ (1,0) [0|0] "" X
 SG_ VCLEFT_hvacBlowerOutputDuty m0: 3|7@1+ (1,0) [0|0] "%" X
 SG_ VCLEFT_hvacBlowerRPMTarget m0: 10|10@1+ (10,0) [0|0] "rpm" X
 SG_ VCLEFT_hvacBlowerRPMActual m0: 20|10@1+ (10,0) [0|0] "rpm" X
 SG_ VCLEFT_hvacBlowerTorque m0: 34|8@1- (0.025,-1.5) [0|0] "Nm" X
 SG_ VCLEFT_hvacBlowerFETTemp m0: 42|8@1+ (1,-40) [0|0] "degC" X
 SG_ VCLEFT_hvacBlowerITerm m0: 50|8@1+ (0.025,-1.5) [0|0] "Nm" X
 SG_ VCLEFT_hvacBlowerInitd m0: 58|1@1+ (1,0) [0|0] "" X
 SG_ VCLEFT_hvacBlowerFault m0: 59|1@1+ (1,0) [0|0] "" X
 SG_ VCLEFT_hvacBlowerLimitFETTemps m0: 60|1@1+ (1,0) [0|0] "" X
 SG_ VCLEFT_hvacBlowerPowerOn m0: 61|1@1+ (1,0) [0|0] "" X
 SG_ VCLEFT_hvacBlowerSpiError m0: 62|1@1+ (1,0) [0|0] "" X
 SG_ VCLEFT_hvacBlowerRs m1: 2|8@1+ (0.0025,0) [0|0] "Ohm" X
 SG_ VCLEFT_hvacBlowerIPhase0 m1: 10|8@1+ (0.2,0) [0|0] "A" X
 SG_ VCLEFT_hvacBlowerIPhase1 m1: 18|8@1+ (0.2,0) [0|0] "A" X
 SG_ VCLEFT_hvacBlowerIPhase2 m1: 26|8@1+ (0.2,0) [0|0] "A" X

BO_ 770 VCLEFT_info: 8 VEH
 SG_ VCLEFT_infoIndex M: 0|8@1+ (1,0) [0|0] "" X
 SG_ VCLEFT_infoBuildType m10: 8|3@1+ (1,0) [0|0] "" X
 SG_ VCLEFT_infoBuildConfigId m10: 16|16@1+ (1,0) [0|0] "" X
 SG_ VCLEFT_infoHardwareId m10: 32|16@1+ (1,0) [0|0] "" X
 SG_ VCLEFT_infoComponentId m10: 48|16@1+ (1,0) [0|0] "" X
 SG_ VCLEFT_infoPcbaId m11: 8|8@1+ (1,0) [0|0] "" X
 SG_ VCLEFT_infoAssemblyId m11: 16|8@1+ (1,0) [0|0] "" X
 SG_ VCLEFT_infoUsageId m11: 24|16@1+ (1,0) [0|0] "" X
 SG_ VCLEFT_infoSubUsageId m11: 40|16@1+ (1,0) [0|0] "" X
 SG_ VCLEFT_infoAppCrc m13: 8|32@1+ (1,0) [0|0] "" X
 SG_ VCLEFT_infoSubcomponent1 m16: 32|32@1+ (1,0) [0|0] "" X
 SG_ VCLEFT_infoAppGitHash m17: 10|54@1+ (4,0) [0|0] "" X
 SG_ VCLEFT_infoBootGitHash m18: 10|54@1+ (4,0) [0|0] "" X
 SG_ VCLEFT_infoPlatformType m19: 8|8@1+ (1,0) [0|0] "" X
 SG_ VCLEFT_infoBootUdsProtoVersion m20: 8|16@1+ (1,0) [0|0] "" X
 SG_ VCLEFT_infoBootCrc m20: 24|32@1+ (1,0) [0|0] "" X
 SG_ VCLEFT_swcAppCRC m23: 32|32@1+ (1,0) [0|0] "" X
 SG_ VCLEFT_infoSubcomponent3 m24: 32|32@1+ (1,0) [0|0] "" X
 SG_ VCLEFT_infoCBCAppCRC m31: 32|32@1+ (1,0) [0|0] "" X

BO_ 1860 VCLEFT_recallStatus: 1 VEH
 SG_ VCLEFT_columnRecallStatus: 4|2@1+ (1,0) [0|0] "" X
 SG_ VCLEFT_mirrorRecallStatus: 6|2@1+ (1,0) [0|0] "" X
 SG_ VCLEFT_seatRecallStatus: 2|2@1+ (1,0) [0|0] "" X
 SG_ VCLEFT_systemRecallStatus: 0|2@1+ (1,0) [0|0] "" X

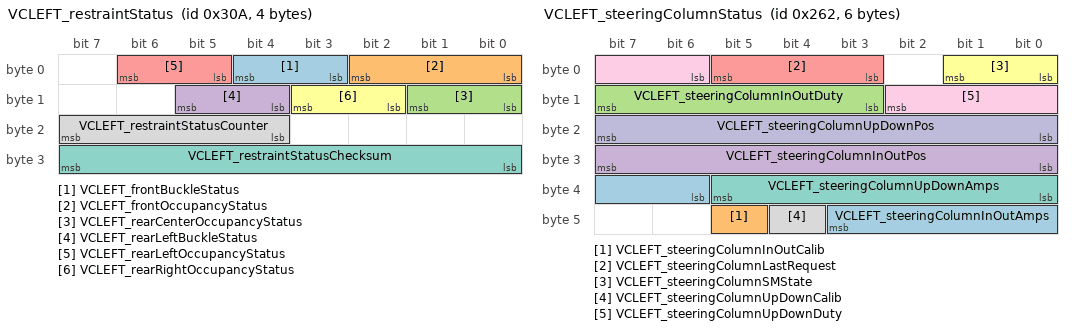
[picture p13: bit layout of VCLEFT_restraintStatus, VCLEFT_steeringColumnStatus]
BO_ 778 VCLEFT_restraintStatus: 4 VEH
 SG_ VCLEFT_frontBuckleStatus: 3|2@1+ (1,0) [0|0] "" X
 SG_ VCLEFT_frontOccupancyStatus: 0|3@1+ (1,0) [0|0] "" X
 SG_ VCLEFT_rearCenterOccupancyStatus: 8|2@1+ (1,0) [0|0] "" X
 SG_ VCLEFT_rearLeftBuckleStatus: 12|2@1+ (1,0) [0|0] "" X
 SG_ VCLEFT_rearLeftOccupancyStatus: 5|2@1+ (1,0) [0|0] "" X
 SG_ VCLEFT_rearRightOccupancyStatus: 10|2@1+ (1,0) [0|0] "" X
 SG_ VCLEFT_restraintStatusChecksum: 24|8@1+ (1,0) [0|0] "" X
 SG_ VCLEFT_restraintStatusCounter: 20|4@1+ (1,0) [0|0] "" X

BO_ 1250 VCLEFT_seatStatus: 8 VEH
 SG_ VCLEFT_seatStatusIndex M: 0|3@1+ (1,0) [0|0] "" X
 SG_ VCLEFT_frontSeatTrackPos m0: 8|16@1- (1,0) [0|0] "" X
 SG_ VCLEFT_frontSeatTrackCurrent m0: 24|12@1- (0.01,0) [0|0] "A" X
 SG_ VCLEFT_frontSeatTrackDuty m0: 36|12@1- (0.1,0) [0|0] "%" X
 SG_ VCLEFT_frontSeatTrackState m0: 48|3@1+ (1,0) [0|0] "" X
 SG_ VCLEFT_frontSeatTrackCalibrated m0: 51|1@1+ (1,0) [0|0] "" X
 SG_ VCLEFT_frontSeatTrackLog m0: 52|1@1+ (1,0) [0|0] "" X
 SG_ VCLEFT_frontSeatBackPos m1: 8|16@1- (1,0) [0|0] "" X
 SG_ VCLEFT_frontSeatBackCurrent m1: 24|12@1- (0.01,0) [0|0] "A" X
 SG_ VCLEFT_frontSeatBackDuty m1: 36|12@1- (0.1,0) [0|0] "%" X
 SG_ VCLEFT_frontSeatBackState m1: 48|3@1+ (1,0) [0|0] "" X
 SG_ VCLEFT_frontSeatBackCalibrated m1: 51|1@1+ (1,0) [0|0] "" X
 SG_ VCLEFT_frontSeatBackLog m1: 52|1@1+ (1,0) [0|0] "" X
 SG_ VCLEFT_frontSeatLiftPos m2: 8|16@1- (1,0) [0|0] "" X
 SG_ VCLEFT_frontSeatLiftCurrent m2: 24|12@1- (0.01,0) [0|0] "A" X
 SG_ VCLEFT_frontSeatLiftDuty m2: 36|12@1- (0.1,0) [0|0] "%" X
 SG_ VCLEFT_frontSeatLiftState m2: 48|3@1+ (1,0) [0|0] "" X
 SG_ VCLEFT_frontSeatLiftCalibrated m2: 51|1@1+ (1,0) [0|0] "" X
 SG_ VCLEFT_frontSeatLiftLog m2: 52|1@1+ (1,0) [0|0] "" X
 SG_ VCLEFT_frontSeatTiltPos m3: 8|16@1- (1,0) [0|0] "" X
 SG_ VCLEFT_frontSeatTiltCurrent m3: 24|12@1- (0.01,0) [0|0] "A" X
 SG_ VCLEFT_frontSeatTiltDuty m3: 36|12@1- (0.1,0) [0|0] "%" X
 SG_ VCLEFT_frontSeatTiltState m3: 48|3@1+ (1,0) [0|0] "" X
 SG_ VCLEFT_frontSeatTiltCalibrated m3: 51|1@1+ (1,0) [0|0] "" X
 SG_ VCLEFT_frontSeatTiltLog m3: 52|1@1+ (1,0) [0|0] "" X
 SG_ VCLEFT_lumbarAState m4: 3|3@1+ (1,0) [0|0] "" X
 SG_ VCLEFT_lumbarBState m4: 8|3@1+ (1,0) [0|0] "" X
 SG_ VCLEFT_lumbarAPressureHpa m4: 16|16@1+ (1,0) [0|0] "" X
 SG_ VCLEFT_lumbarBPressureHpa m4: 32|16@1+ (1,0) [0|0] "" X
 SG_ VCLEFT_lumbarActiveTooLongErr m4: 48|1@1+ (1,0) [0|0] "" X
 SG_ VCLEFT_lumbarMaxPErr m4: 49|1@1+ (1,0) [0|0] "" X
 SG_ VCLEFT_lumbarOvercurrentErr m4: 50|1@1+ (1,0) [0|0] "" X
 SG_ VCLEFT_lumbarMaxOperatingPErr m4: 51|1@1+ (1,0) [0|0] "" X
 SG_ VCLEFT_lumbarMinPErr m4: 52|1@1+ (1,0) [0|0] "" X
 SG_ VCLEFT_lumbarGeneralErr m4: 53|1@1+ (1,0) [0|0] "" X
 SG_ VCLEFT_lumbarDevMaxPumpPressA m4: 54|1@1+ (1,0) [0|0] "" X
 SG_ VCLEFT_lumbarDevMaxPumpPressB m4: 55|1@1+ (1,0) [0|0] "" X
 SG_ VCLEFT_frontSeatTrackPosReal m5: 3|12@1- (1,0) [0|0] "mm" X
 SG_ VCLEFT_frontSeatBackPosReal m5: 16|12@1- (0.1,0) [0|0] "deg" X
 SG_ VCLEFT_frontSeatLiftPosReal m5: 28|12@1- (1,0) [0|0] "mm" X
 SG_ VCLEFT_frontSeatTiltPosReal m5: 40|12@1- (0.1,0) [0|0] "deg" X

BO_ 930 VCLEFT_status: 8 VEH
 SG_ VCLEFT_statusIndex M: 0|1@1+ (1,0) [0|0] "" X
 SG_ VCLEFT_loadShedPriority m0: 1|8@1+ (1,0) [0|0] "" X
 SG_ VCLEFT_vehiclePowerStateDBG m0: 9|2@1+ (1,0) [0|0] "" X
 SG_ VCLEFT_consoleDoorAssist m0: 11|1@1+ (1,0) [0|0] "" X
 SG_ VCLEFT_OTAState m0: 12|1@1+ (1,0) [0|0] "" X
 SG_ VCLEFT_5AVoltage m0: 13|10@1+ (0.00544368,0) [0|0] "V" X
 SG_ VCLEFT_vbatProt m0: 23|12@1+ (0.00544368,0) [0|0] "V" X
 SG_ VCLEFT_footwellLightCurrent m0: 35|12@1- (0.1,0) [0|0] "mA" X
 SG_ VCLEFT_swcInputVoltage m0: 47|8@1+ (0.1,0) [0|0] "V" X
 SG_ VCLEFT_swcPCBATemperature m0: 55|8@1- (1,-40) [0|0] "degC" X
 SG_ VCLEFT_pcbaTemperature m1: 1|11@1+ (0.125,-40) [0|0] "degC" X
 SG_ VCLEFT_DIeFuseCurrent m1: 12|12@1- (0.1,0) [0|0] "A" X
 SG_ VCLEFT_DIeFuseFault m1: 24|1@1+ (1,0) [0|0] "" X
 SG_ VCLEFT_tlcPCBATemperature m1: 32|8@1- (1,-40) [0|0] "degC" X

BO_ 610 VCLEFT_steeringColumnStatus: 6 VEH
 SG_ VCLEFT_steeringColumnInOutAmps: 38|6@1- (0.63,0) [0|0] "A" X
 SG_ VCLEFT_steeringColumnInOutCalib: 45|1@1+ (1,0) [0|0] "" X
 SG_ VCLEFT_steeringColumnInOutDuty: 11|5@1- (7,0) [0|0] "%" X
 SG_ VCLEFT_steeringColumnInOutPos: 24|8@1- (12,1284) [0|0] "ticks" X
 SG_ VCLEFT_steeringColumnLastRequest: 3|3@1+ (1,0) [0|0] "" X
 SG_ VCLEFT_steeringColumnSMState: 0|2@1+ (1,0) [0|0] "" X
 SG_ VCLEFT_steeringColumnUpDownAmps: 32|6@1- (0.63,0) [0|0] "A" X
 SG_ VCLEFT_steeringColumnUpDownCalib: 44|1@1+ (1,0) [0|0] "" X
 SG_ VCLEFT_steeringColumnUpDownDuty: 6|5@1- (7,0) [0|0] "%" X
 SG_ VCLEFT_steeringColumnUpDownPos: 16|8@1- (12,1284) [0|0] "ticks" X

BO_ 962 VCLEFT_switchStatus: 8 VEH
 SG_ VCLEFT_switchStatusIndex M : 0|2@1+ (1,0) [0|2] "" X
 SG_ VCLEFT_2RowSeatBothFoldFlatSwitc m1 : 40|1@1+ (1,0) [0|1] "" X
 SG_ VCLEFT_2RowSeatCenterSwitch m1 : 37|1@1+ (1,0) [0|1] "" X
 SG_ VCLEFT_2RowSeatLeftFoldFlatSwitc m1 : 38|1@1+ (1,0) [0|1] "" X
 SG_ VCLEFT_2RowSeatReclineSwitch m1 : 36|1@1+ (1,0) [0|1] "" X
 SG_ VCLEFT_2RowSeatRightFoldFlatSwit m1 : 39|1@1+ (1,0) [0|1] "" X
 SG_ VCLEFT_brakePressed m0 : 60|1@1+ (1,0) [0|1] "" X
 SG_ VCLEFT_brakeSwitchPressed m0 : 4|1@1+ (1,0) [0|1] "" X
 SG_ VCLEFT_btnWindowAutoDownLR m1 : 35|1@1+ (1,0) [0|1] "" X
 SG_ VCLEFT_btnWindowAutoUpLR m1 : 33|1@1+ (1,0) [0|1] "" X
 SG_ VCLEFT_btnWindowDownLR m1 : 34|1@1+ (1,0) [0|1] "" X
 SG_ VCLEFT_btnWindowSwPackAutoDownLF m0 : 35|1@1+ (1,0) [0|1] "" X
 SG_ VCLEFT_btnWindowSwPackAutoDownLR m0 : 39|1@1+ (1,0) [0|1] "" X
 SG_ VCLEFT_btnWindowSwPackAutoDownRF m0 : 43|1@1+ (1,0) [0|1] "" X
 SG_ VCLEFT_btnWindowSwPackAutoDownRR m0 : 47|1@1+ (1,0) [0|1] "" X
 SG_ VCLEFT_btnWindowSwPackAutoUpLF m0 : 33|1@1+ (1,0) [0|1] "" X
 SG_ VCLEFT_btnWindowSwPackAutoUpLR m0 : 37|1@1+ (1,0) [0|1] "" X
 SG_ VCLEFT_btnWindowSwPackAutoUpRF m0 : 41|1@1+ (1,0) [0|1] "" X
 SG_ VCLEFT_btnWindowSwPackAutoUpRR m0 : 45|1@1+ (1,0) [0|1] "" X
 SG_ VCLEFT_btnWindowSwPackDownLF m0 : 34|1@1+ (1,0) [0|1] "" X
 SG_ VCLEFT_btnWindowSwPackDownLR m0 : 38|1@1+ (1,0) [0|1] "" X
 SG_ VCLEFT_btnWindowSwPackDownRF m0 : 42|1@1+ (1,0) [0|1] "" X
 SG_ VCLEFT_btnWindowSwPackDownRR m0 : 46|1@1+ (1,0) [0|1] "" X
 SG_ VCLEFT_btnWindowSwPackUpLF m0 : 32|1@1+ (1,0) [0|1] "" X
 SG_ VCLEFT_btnWindowSwPackUpLR m0 : 36|1@1+ (1,0) [0|1] "" X
 SG_ VCLEFT_btnWindowSwPackUpRF m0 : 40|1@1+ (1,0) [0|1] "" X
 SG_ VCLEFT_btnWindowSwPackUpRR m0 : 44|1@1+ (1,0) [0|1] "" X
 SG_ VCLEFT_btnWindowUpLR m1 : 32|1@1+ (1,0) [0|1] "" X
 SG_ VCLEFT_frontBuckleSwitch m0 : 48|2@1+ (1,0) [0|3] "" X
 SG_ VCLEFT_frontOccupancySwitch m0 : 50|2@1+ (1,0) [0|3] "" X
 SG_ VCLEFT_frontSeatBackrestBack m0 : 20|2@1+ (1,0) [0|3] "" X
 SG_ VCLEFT_frontSeatBackrestForward m0 : 22|2@1+ (1,0) [0|3] "" X
 SG_ VCLEFT_frontSeatLiftDown m0 : 16|2@1+ (1,0) [0|3] "" X
 SG_ VCLEFT_frontSeatLiftUp m0 : 18|2@1+ (1,0) [0|3] "" X
 SG_ VCLEFT_frontSeatLumbarDown m0 : 24|2@1+ (1,0) [0|3] "" X
 SG_ VCLEFT_frontSeatLumbarIn m0 : 28|2@1+ (1,0) [0|3] "" X
 SG_ VCLEFT_frontSeatLumbarOut m0 : 30|2@1+ (1,0) [0|3] "" X
 SG_ VCLEFT_frontSeatLumbarUp m0 : 26|2@1+ (1,0) [0|3] "" X
 SG_ VCLEFT_frontSeatTiltDown m0 : 12|2@1+ (1,0) [0|3] "" X
 SG_ VCLEFT_frontSeatTiltUp m0 : 14|2@1+ (1,0) [0|3] "" X
 SG_ VCLEFT_frontSeatTrackBack m0 : 8|2@1+ (1,0) [0|3] "" X
 SG_ VCLEFT_frontSeatTrackForward m0 : 10|2@1+ (1,0) [0|3] "" X
 SG_ VCLEFT_hazardButtonPressed m0 : 3|1@1+ (1,0) [0|1] "" X
 SG_ VCLEFT_hornSwitchPressed m0 : 2|1@1+ (1,0) [0|1] "" X
 SG_ VCLEFT_rearCenterBuckleSwitch m0 : 62|2@1+ (1,0) [0|3] "" X
 SG_ VCLEFT_rearCenterOccupancySwitch m0 : 54|2@1+ (1,0) [0|3] "" X
 SG_ VCLEFT_rearHVACButtonPressed m0 : 61|1@1+ (1,0) [0|1] "" X
 SG_ VCLEFT_rearLeftBuckleSwitch m0 : 52|2@1+ (1,0) [0|3] "" X
 SG_ VCLEFT_rearLeftOccupancySwitch m0 : 56|2@1+ (1,0) [0|3] "" X
 SG_ VCLEFT_rearRightOccupancySwitch m0 : 58|2@1+ (1,0) [0|3] "" X
 SG_ VCLEFT_rightMirrorTilt m0 : 5|3@1+ (1,0) [0|4] "" X
 SG_ VCLEFT_swcLeftDoublePress m1 : 41|1@1+ (1,0) [0|1] "" X
 SG_ VCLEFT_swcLeftPressed m1 : 5|2@1+ (1,0) [0|3] "" X
 SG_ VCLEFT_swcLeftScrollTicks m1 : 16|6@1- (1,0) [-32|31] "" X
 SG_ VCLEFT_swcLeftTiltLeft m1 : 14|2@1+ (1,0) [0|3] "" X
 SG_ VCLEFT_swcLeftTiltRight m1 : 3|2@1+ (1,0) [0|3] "" X
 SG_ VCLEFT_swcRightDoublePress m1 : 42|1@1+ (1,0) [0|1] "" X
 SG_ VCLEFT_swcRightPressed m1 : 12|2@1+ (1,0) [0|3] "" X
 SG_ VCLEFT_swcRightScrollTicks m1 : 24|6@1- (1,0) [-32|31] "" X
 SG_ VCLEFT_swcRightTiltLeft m1 : 8|2@1+ (1,0) [0|3] "" X
 SG_ VCLEFT_swcRightTiltRight m1 : 10|2@1+ (1,0) [0|3] "" X

BO_ 960 VCRIGHT_alertMatrix: 8 VEH
 SG_ VCRIGHT_matrixIndex M: 0|4@1+ (1,0) [0|0] "" X
 SG_ VCRIGHT_a001_WatchdogReset m0: 4|1@1+ (1,0) [0|0] "" X
 SG_ VCRIGHT_a002_PowerLossReset m0: 5|1@1+ (1,0) [0|0] "" X
 SG_ VCRIGHT_a003_SWAssertion m0: 6|1@1+ (1,0) [0|0] "" X
 SG_ VCRIGHT_a010_ExtSupplyVoltError m0: 13|1@1+ (1,0) [0|0] "" X
 SG_ VCRIGHT_a012_CPUReset m0: 15|1@1+ (1,0) [0|0] "" X
 SG_ VCRIGHT_a013_AlertManagerFault m0: 16|1@1+ (1,0) [0|0] "" X
 SG_ VCRIGHT_a015_NVMMAlert m0: 18|1@1+ (1,0) [0|0] "" X
 SG_ VCRIGHT_a021_TaskSchedulerError m0: 24|1@1+ (1,0) [0|0] "" X
 SG_ VCRIGHT_a022_TaskInitError m0: 25|1@1+ (1,0) [0|0] "" X
 SG_ VCRIGHT_a031_UDSActive m0: 34|1@1+ (1,0) [0|0] "" X
 SG_ VCRIGHT_a041_HighCPULoad m0: 44|1@1+ (1,0) [0|0] "" X
 SG_ VCRIGHT_a042_HighStackUsage m0: 45|1@1+ (1,0) [0|0] "" X
 SG_ VCRIGHT_a043_Task1msError m0: 46|1@1+ (1,0) [0|0] "" X
 SG_ VCRIGHT_a044_Task10msError m0: 47|1@1+ (1,0) [0|0] "" X
 SG_ VCRIGHT_a045_Task100msError m0: 48|1@1+ (1,0) [0|0] "" X
 SG_ VCRIGHT_a046_Task1000msError m0: 49|1@1+ (1,0) [0|0] "" X
 SG_ VCRIGHT_a059_inputResistanceHigh m0: 62|1@1+ (1,0) [0|0] "" X
 SG_ VCRIGHT_a060_engineeringBuild m0: 63|1@1+ (1,0) [0|0] "" X
 SG_ VCRIGHT_a061_XCPConnected m1: 4|1@1+ (1,0) [0|0] "" X
 SG_ VCRIGHT_a062_XCPWasConnected m1: 5|1@1+ (1,0) [0|0] "" X
 SG_ VCRIGHT_a063_SwitchFault m1: 6|1@1+ (1,0) [0|0] "" X
 SG_ VCRIGHT_a064_busSleepReqTimeout m1: 7|1@1+ (1,0) [0|0] "" X
 SG_ VCRIGHT_a097_CMP_MIA m1: 40|1@1+ (1,0) [0|0] "" X
 SG_ VCRIGHT_a098_DI_THERMAL_MIA m1: 41|1@1+ (1,0) [0|0] "" X
 SG_ VCRIGHT_a099_PARK_MIA m1: 42|1@1+ (1,0) [0|0] "" X
 SG_ VCRIGHT_a100_CANbus_MIA m1: 43|1@1+ (1,0) [0|0] "" X
 SG_ VCRIGHT_a101_PM_MIA m1: 44|1@1+ (1,0) [0|0] "" X
 SG_ VCRIGHT_a102_PTC_MIA m1: 45|1@1+ (1,0) [0|0] "" X
 SG_ VCRIGHT_a103_CP_MIA m1: 46|1@1+ (1,0) [0|0] "" X
 SG_ VCRIGHT_a104_DAS_MIA m1: 47|1@1+ (1,0) [0|0] "" X
 SG_ VCRIGHT_a105_TAS_MIA m1: 48|1@1+ (1,0) [0|0] "" X
 SG_ VCRIGHT_a106_PCS_MIA m1: 49|1@1+ (1,0) [0|0] "" X
 SG_ VCRIGHT_a107_BMS_MIA m1: 50|1@1+ (1,0) [0|0] "" X
 SG_ VCRIGHT_a108_DIS_MIA m1: 51|1@1+ (1,0) [0|0] "" X
 SG_ VCRIGHT_a109_RCM_MIA m1: 52|1@1+ (1,0) [0|0] "" X
 SG_ VCRIGHT_a110_GTW_MIA m1: 53|1@1+ (1,0) [0|0] "" X
 SG_ VCRIGHT_a111_EPBR_MIA m1: 54|1@1+ (1,0) [0|0] "" X
 SG_ VCRIGHT_a112_EPBL_MIA m1: 55|1@1+ (1,0) [0|0] "" X
 SG_ VCRIGHT_a113_UI_MIA m1: 56|1@1+ (1,0) [0|0] "" X
 SG_ VCRIGHT_a114_ESP_MIA m1: 57|1@1+ (1,0) [0|0] "" X
 SG_ VCRIGHT_a115_VCSEC_MIA m1: 58|1@1+ (1,0) [0|0] "" X
 SG_ VCRIGHT_a116_VCRIGHT_MIA m1: 59|1@1+ (1,0) [0|0] "" X
 SG_ VCRIGHT_a117_VCLEFT_MIA m1: 60|1@1+ (1,0) [0|0] "" X
 SG_ VCRIGHT_a118_VCFRONT_MIA m1: 61|1@1+ (1,0) [0|0] "" X
 SG_ VCRIGHT_a119_SCCM_MIA m1: 62|1@1+ (1,0) [0|0] "" X
 SG_ VCRIGHT_a120_DI_DRIVE_MIA m1: 63|1@1+ (1,0) [0|0] "" X
 SG_ VCRIGHT_a129_hvacIntakeUncalib m2: 12|1@1+ (1,0) [0|0] "" X
 SG_ VCRIGHT_a130_hvacLHBleedUncalib m2: 13|1@1+ (1,0) [0|0] "" X
 SG_ VCRIGHT_a131_hvacRHBleedUncalib m2: 14|1@1+ (1,0) [0|0] "" X
 SG_ VCRIGHT_a132_hvacLHVaneUncalib m2: 15|1@1+ (1,0) [0|0] "" X
 SG_ VCRIGHT_a133_hvacRHVaneUncalib m2: 16|1@1+ (1,0) [0|0] "" X
 SG_ VCRIGHT_a134_hvacUpprModeUncalib m2: 17|1@1+ (1,0) [0|0] "" X
 SG_ VCRIGHT_a135_hvacLowrModeUncalib m2: 18|1@1+ (1,0) [0|0] "" X
 SG_ VCRIGHT_a136_hvacIntakeFault m2: 19|1@1+ (1,0) [0|0] "" X
 SG_ VCRIGHT_a137_hvacLHBleedFault m2: 20|1@1+ (1,0) [0|0] "" X
 SG_ VCRIGHT_a138_hvacRHBleedFault m2: 21|1@1+ (1,0) [0|0] "" X
 SG_ VCRIGHT_a139_hvacLHVaneFault m2: 22|1@1+ (1,0) [0|0] "" X
 SG_ VCRIGHT_a140_hvacRHVaneFault m2: 23|1@1+ (1,0) [0|0] "" X
 SG_ VCRIGHT_a141_hvacUpperModeFault m2: 24|1@1+ (1,0) [0|0] "" X
 SG_ VCRIGHT_a142_hvacLowerModeFault m2: 25|1@1+ (1,0) [0|0] "" X
 SG_ VCRIGHT_a144_evaporatorTempSns m2: 27|1@1+ (1,0) [0|0] "" X
 SG_ VCRIGHT_a145_ductLeftTempSns m2: 28|1@1+ (1,0) [0|0] "" X
 SG_ VCRIGHT_a146_ductRightTempSns m2: 29|1@1+ (1,0) [0|0] "" X
 SG_ VCRIGHT_a147_incarProbeTempSns m2: 30|1@1+ (1,0) [0|0] "" X
 SG_ VCRIGHT_a148_incarMidTempSns m2: 31|1@1+ (1,0) [0|0] "" X
 SG_ VCRIGHT_a149_incarDeepTempSns m2: 32|1@1+ (1,0) [0|0] "" X
 SG_ VCRIGHT_a150_windowPinchFront m2: 33|1@1+ (1,0) [0|0] "" X
 SG_ VCRIGHT_a151_windowPinchRear m2: 34|1@1+ (1,0) [0|0] "" X
 SG_ VCRIGHT_a152_windowUncalFront m2: 35|1@1+ (1,0) [0|0] "" X
 SG_ VCRIGHT_a153_windowUncalRear m2: 36|1@1+ (1,0) [0|0] "" X
 SG_ VCRIGHT_a154_windowThermalFront m2: 37|1@1+ (1,0) [0|0] "" X
 SG_ VCRIGHT_a155_windowThermalRear m2: 38|1@1+ (1,0) [0|0] "" X
 SG_ VCRIGHT_a156_windowNoInputFront m2: 39|1@1+ (1,0) [0|0] "" X
 SG_ VCRIGHT_a157_windowNoInputRear m2: 40|1@1+ (1,0) [0|0] "" X
 SG_ VCRIGHT_a158_windowPinchOverideF m2: 41|1@1+ (1,0) [0|0] "" X
 SG_ VCRIGHT_a159_windowPinchOverideR m2: 42|1@1+ (1,0) [0|0] "" X
 SG_ VCRIGHT_a160_windowUndercurrentF m2: 43|1@1+ (1,0) [0|0] "" X
 SG_ VCRIGHT_a161_windowUndercurrentR m2: 44|1@1+ (1,0) [0|0] "" X
 SG_ VCRIGHT_a162_windowEncoderStallF m2: 45|1@1+ (1,0) [0|0] "" X
 SG_ VCRIGHT_a163_windowEncoderStallR m2: 46|1@1+ (1,0) [0|0] "" X
 SG_ VCRIGHT_a164_windowFactoryTest m2: 47|1@1+ (1,0) [0|0] "" X
 SG_ VCRIGHT_a165_windowFactoryTest2 m2: 48|1@1+ (1,0) [0|0] "" X
 SG_ VCRIGHT_a166_windowDebug m2: 49|1@1+ (1,0) [0|0] "" X
 SG_ VCRIGHT_a167_windowDebugPinchF m2: 50|1@1+ (1,0) [0|0] "" X
 SG_ VCRIGHT_a168_windowDebugPinchR m2: 51|1@1+ (1,0) [0|0] "" X
 SG_ VCRIGHT_a169_windowCurrentPeakF m2: 52|1@1+ (1,0) [0|0] "" X
 SG_ VCRIGHT_a170_windowCurrentPeakR m2: 53|1@1+ (1,0) [0|0] "" X
 SG_ VCRIGHT_a172_SPI_MIA m2: 55|1@1+ (1,0) [0|0] "" X
 SG_ VCRIGHT_a174_BLERightPowerCycled m2: 57|1@1+ (1,0) [0|0] "" X
 SG_ VCRIGHT_a180_frontDoorLatchRehome m2: 63|1@1+ (1,0) [0|0] "" X
 SG_ VCRIGHT_a181_rearDoorLatchRehome m3: 4|1@1+ (1,0) [0|0] "" X
 SG_ VCRIGHT_a182_emergencyLatchRel m3: 5|1@1+ (1,0) [0|0] "" X
 SG_ VCRIGHT_a183_doorStateFactoryTest m3: 6|1@1+ (1,0) [0|0] "" X
 SG_ VCRIGHT_a184_trunkFailedOpening m3: 7|1@1+ (1,0) [0|0] "" X
 SG_ VCRIGHT_a185_summonAborted m3: 8|1@1+ (1,0) [0|0] "" X
 SG_ VCRIGHT_a186_latchReleaseFailedF m3: 9|1@1+ (1,0) [0|0] "" X
 SG_ VCRIGHT_a187_latchReleaseFailedR m3: 10|1@1+ (1,0) [0|0] "" X
 SG_ VCRIGHT_a188_latchUnableToRearmF m3: 11|1@1+ (1,0) [0|0] "" X
 SG_ VCRIGHT_a189_latchUnableToRearmR m3: 12|1@1+ (1,0) [0|0] "" X
 SG_ VCRIGHT_a190_eFuseMgmtVbatFused m3: 13|1@1+ (1,0) [0|0] "" X
 SG_ VCRIGHT_a191_gloveboxPower m3: 14|1@1+ (1,0) [0|0] "" X
 SG_ VCRIGHT_a192_gloveboxLatchRel m3: 15|1@1+ (1,0) [0|0] "" X
 SG_ VCRIGHT_a193_amplifierEFuseFault m3: 16|1@1+ (1,0) [0|0] "" X
 SG_ VCRIGHT_a194_cntctrPwrEFuseFault m3: 17|1@1+ (1,0) [0|0] "" X
 SG_ VCRIGHT_a195_hvcEFuseFault m3: 18|1@1+ (1,0) [0|0] "" X
 SG_ VCRIGHT_a196_VEHCANOverterminate m3: 19|1@1+ (1,0) [0|0] "" X
 SG_ VCRIGHT_a197_VEHCANUndertrminate m3: 20|1@1+ (1,0) [0|0] "" X
 SG_ VCRIGHT_a198_PRVCANOverterminate m3: 21|1@1+ (1,0) [0|0] "" X
 SG_ VCRIGHT_a199_PRVCANUndertrminate m3: 22|1@1+ (1,0) [0|0] "" X
 SG_ VCRIGHT_a200_motorPhantomEncoder m3: 23|1@1+ (1,0) [0|0] "" X
 SG_ VCRIGHT_a201_motorDutyEncDisabl m3: 24|1@1+ (1,0) [0|0] "" X
 SG_ VCRIGHT_a202_epbmUnderIStatic m3: 25|1@1+ (1,0) [0|0] "" X
 SG_ VCRIGHT_a203_epbmOverIStatic m3: 26|1@1+ (1,0) [0|0] "" X
 SG_ VCRIGHT_a204_epbmUnderIDyn m3: 27|1@1+ (1,0) [0|0] "" X
 SG_ VCRIGHT_a205_epbmOverIDyn m3: 28|1@1+ (1,0) [0|0] "" X
 SG_ VCRIGHT_a206_epbWrongDirection m3: 29|1@1+ (1,0) [0|0] "" X
 SG_ VCRIGHT_a207_epbmEnableWrong m3: 30|1@1+ (1,0) [0|0] "" X
 SG_ VCRIGHT_a208_epbFaulted m3: 31|1@1+ (1,0) [0|0] "" X
 SG_ VCRIGHT_a209_epbStateMisTime m3: 32|1@1+ (1,0) [0|0] "" X
 SG_ VCRIGHT_a210_epbStateTime m3: 33|1@1+ (1,0) [0|0] "" X
 SG_ VCRIGHT_a211_epbmUnderIStaticNew m3: 34|1@1+ (1,0) [0|0] "" X
 SG_ VCRIGHT_a212_epbmOverIStaticNew m3: 35|1@1+ (1,0) [0|0] "" X
 SG_ VCRIGHT_a213_epbmUnderIDynNew m3: 36|1@1+ (1,0) [0|0] "" X
 SG_ VCRIGHT_a214_epbmOverIDynNew m3: 37|1@1+ (1,0) [0|0] "" X
 SG_ VCRIGHT_a215_currentDesyncWarning m3: 38|1@1+ (1,0) [0|0] "" X
 SG_ VCRIGHT_a216_SPI_MIA_debugData1 m3: 39|1@1+ (1,0) [0|0] "" X
 SG_ VCRIGHT_a217_SPI_MIA_debugData2 m3: 40|1@1+ (1,0) [0|0] "" X
 SG_ VCRIGHT_a218_motorDriverFault m3: 41|1@1+ (1,0) [0|0] "" X
 SG_ VCRIGHT_a219_motorCurrentDropout m3: 42|1@1+ (1,0) [0|0] "" X
 SG_ VCRIGHT_a220_seatCurrStallTrack m3: 43|1@1+ (1,0) [0|0] "" X
 SG_ VCRIGHT_a221_seatCurrStallBack m3: 44|1@1+ (1,0) [0|0] "" X
 SG_ VCRIGHT_a222_seatCurrStallTilt m3: 45|1@1+ (1,0) [0|0] "" X
 SG_ VCRIGHT_a223_seatCurrStallLift m3: 46|1@1+ (1,0) [0|0] "" X
 SG_ VCRIGHT_a224_seatEncStallTrack m3: 47|1@1+ (1,0) [0|0] "" X
 SG_ VCRIGHT_a225_seatEncStallBack m3: 48|1@1+ (1,0) [0|0] "" X
 SG_ VCRIGHT_a226_seatEncStallTilt m3: 49|1@1+ (1,0) [0|0] "" X
 SG_ VCRIGHT_a227_seatEncStallLift m3: 50|1@1+ (1,0) [0|0] "" X
 SG_ VCRIGHT_a228_seatEncOverTrack m3: 51|1@1+ (1,0) [0|0] "" X
 SG_ VCRIGHT_a229_seatEncOverBack m3: 52|1@1+ (1,0) [0|0] "" X
 SG_ VCRIGHT_a230_seatEncOverTilt m3: 53|1@1+ (1,0) [0|0] "" X
 SG_ VCRIGHT_a231_seatEncOverLift m3: 54|1@1+ (1,0) [0|0] "" X
 SG_ VCRIGHT_a232_seatCurrUnderTrack m3: 55|1@1+ (1,0) [0|0] "" X
 SG_ VCRIGHT_a233_seatCurrUnderBack m3: 56|1@1+ (1,0) [0|0] "" X
 SG_ VCRIGHT_a234_seatCurrUnderTilt m3: 57|1@1+ (1,0) [0|0] "" X
 SG_ VCRIGHT_a235_seatCurrUnderLift m3: 58|1@1+ (1,0) [0|0] "" X
 SG_ VCRIGHT_a236_lumbarOverPresA m3: 59|1@1+ (1,0) [0|0] "" X
 SG_ VCRIGHT_a237_lumbarOverPresB m3: 60|1@1+ (1,0) [0|0] "" X
 SG_ VCRIGHT_a238_lumbarValveMIA m3: 61|1@1+ (1,0) [0|0] "" X
 SG_ VCRIGHT_a239_seatHeatIFront m3: 62|1@1+ (1,0) [0|0] "" X
 SG_ VCRIGHT_a240_seatHeatShortFront m3: 63|1@1+ (1,0) [0|0] "" X
 SG_ VCRIGHT_a241_seatHeatMIAFront m4: 4|1@1+ (1,0) [0|0] "" X
 SG_ VCRIGHT_a242_seatHeatIRearL m4: 5|1@1+ (1,0) [0|0] "" X
 SG_ VCRIGHT_a243_seatHeatShortRearL m4: 6|1@1+ (1,0) [0|0] "" X
 SG_ VCRIGHT_a244_seatHeatMIARearL m4: 7|1@1+ (1,0) [0|0] "" X
 SG_ VCRIGHT_a245_seatHeatIRearC m4: 8|1@1+ (1,0) [0|0] "" X
 SG_ VCRIGHT_a246_seatHeatShortRearC m4: 9|1@1+ (1,0) [0|0] "" X
 SG_ VCRIGHT_a247_seatHeatMIARearC m4: 10|1@1+ (1,0) [0|0] "" X
 SG_ VCRIGHT_a248_seatHeatIRearR m4: 11|1@1+ (1,0) [0|0] "" X
 SG_ VCRIGHT_a249_seatHeatShortRearR m4: 12|1@1+ (1,0) [0|0] "" X
 SG_ VCRIGHT_a250_seatHeatMIARearR m4: 13|1@1+ (1,0) [0|0] "" X
 SG_ VCRIGHT_a251_seatUncalTrack m4: 14|1@1+ (1,0) [0|0] "" X
 SG_ VCRIGHT_a252_seatUncalBack m4: 15|1@1+ (1,0) [0|0] "" X
 SG_ VCRIGHT_a253_seatUncalTilt m4: 16|1@1+ (1,0) [0|0] "" X
 SG_ VCRIGHT_a254_seatUncalLift m4: 17|1@1+ (1,0) [0|0] "" X
 SG_ VCRIGHT_a255_PTCOverTemp m4: 18|1@1+ (1,0) [0|0] "" X
 SG_ VCRIGHT_a256_PTCCurrentDrawNoReq m4: 19|1@1+ (1,0) [0|0] "" X
 SG_ VCRIGHT_a257_THSMIA m4: 20|1@1+ (1,0) [0|0] "" X
 SG_ VCRIGHT_a258_PTCStuckInBoot m4: 21|1@1+ (1,0) [0|0] "" X
 SG_ VCRIGHT_a259_latchDisarmDelayF m4: 22|1@1+ (1,0) [0|0] "" X
 SG_ VCRIGHT_a260_latchDisarmDelayR m4: 23|1@1+ (1,0) [0|0] "" X
 SG_ VCRIGHT_a262_PTCFaulted m4: 25|1@1+ (1,0) [0|0] "" X
 SG_ VCRIGHT_a263_seatTrackStallDebug m4: 26|1@1+ (1,0) [0|0] "" X
 SG_ VCRIGHT_a264_seatBackStallDebug m4: 27|1@1+ (1,0) [0|0] "" X
 SG_ VCRIGHT_a265_seatTiltStallDebug m4: 28|1@1+ (1,0) [0|0] "" X
 SG_ VCRIGHT_a266_seatLiftStallDebug m4: 29|1@1+ (1,0) [0|0] "" X
 SG_ VCRIGHT_a267_seatTrackHCEncStlDbg m4: 30|1@1+ (1,0) [0|0] "" X
 SG_ VCRIGHT_a268_seatBackHCEncStlDbg m4: 31|1@1+ (1,0) [0|0] "" X
 SG_ VCRIGHT_a269_seatTiltHCEncStlDbg m4: 32|1@1+ (1,0) [0|0] "" X
 SG_ VCRIGHT_a270_seatLiftHCEncStlDbg m4: 33|1@1+ (1,0) [0|0] "" X
 SG_ VCRIGHT_a271_THSSensorFault m4: 34|1@1+ (1,0) [0|0] "" X
 SG_ VCRIGHT_a272_vhclPwrStateMsmtch m4: 35|1@1+ (1,0) [0|0] "" X
 SG_ VCRIGHT_a273_handleStuckActiveF m4: 36|1@1+ (1,0) [0|0] "" X
 SG_ VCRIGHT_a274_handleStuckActiveR m4: 37|1@1+ (1,0) [0|0] "" X
 SG_ VCRIGHT_a275_rightTurnLightFault m4: 38|1@1+ (1,0) [0|0] "" X
 SG_ VCRIGHT_a276_mirrorDebug m4: 39|1@1+ (1,0) [0|0] "" X
 SG_ VCRIGHT_a277_BLERightUnderVoltage m4: 40|1@1+ (1,0) [0|0] "" X
 SG_ VCRIGHT_a280_latchDidNotDisarmF m4: 43|1@1+ (1,0) [0|0] "" X
 SG_ VCRIGHT_a281_latchDidNotDisarmR m4: 44|1@1+ (1,0) [0|0] "" X
 SG_ VCRIGHT_a282_latchUnexpectedArmF m4: 45|1@1+ (1,0) [0|0] "" X
 SG_ VCRIGHT_a283_latchUnexpectedArmR m4: 46|1@1+ (1,0) [0|0] "" X
 SG_ VCRIGHT_a286_windowSpeedInvalidF m4: 49|1@1+ (1,0) [0|0] "" X
 SG_ VCRIGHT_a287_windowSpeedInvalidR m4: 50|1@1+ (1,0) [0|0] "" X
 SG_ VCRIGHT_a290_occupancyFaultedFront m4: 53|1@1+ (1,0) [0|0] "" X
 SG_ VCRIGHT_a291_buckleFaultedFront m4: 54|1@1+ (1,0) [0|0] "" X
 SG_ VCRIGHT_a292_buckleFaultedRearC m4: 55|1@1+ (1,0) [0|0] "" X
 SG_ VCRIGHT_a293_buckleFaultedRearR m4: 56|1@1+ (1,0) [0|0] "" X
 SG_ VCRIGHT_a304_frontIntHandleShorted m5: 7|1@1+ (1,0) [0|0] "" X
 SG_ VCRIGHT_a305_rearIntHandleShorted m5: 8|1@1+ (1,0) [0|0] "" X
 SG_ VCRIGHT_a306_handleDisconnectedF m5: 9|1@1+ (1,0) [0|0] "" X
 SG_ VCRIGHT_a307_handleDisconnectedR m5: 10|1@1+ (1,0) [0|0] "" X

BO_ 1795 VCRIGHT_debugThermal10Hz: 8 VEH
 SG_ VCRIGHT_debugThermal10HzIndex M: 0|3@1+ (1,0) [0|0] "" X
 SG_ VCRIGHT_wattsDemandEvapFeedback m0: 3|9@1- (20,0) [0|0] "W" X
 SG_ VCRIGHT_wattsDemandEvapFeedfwd m0: 12|9@1+ (20,0) [0|0] "W" X
 SG_ VCRIGHT_wattsHeaterLeftFeedback m0: 21|9@1- (20,0) [0|0] "W" X
 SG_ VCRIGHT_wattsHeaterLeftFeedfwd m0: 30|9@1+ (20,0) [0|0] "W" X
 SG_ VCRIGHT_wattsHeaterRightFeedback m0: 39|9@1- (20,0) [0|0] "W" X
 SG_ VCRIGHT_wattsHeaterRightFeedfwd m0: 48|9@1+ (20,0) [0|0] "W" X
 SG_ VCRIGHT_tempEvapAdjustmentLeft m1: 8|7@1+ (0.1,0) [0|0] "degC" X
 SG_ VCRIGHT_tempEvapAdjustmentRight m1: 16|7@1+ (0.1,0) [0|0] "degC" X
 SG_ VCRIGHT_hvacPanelFloorSplitRow1 m2: 8|8@1+ (0.4,0) [0|0] "%" X
 SG_ VCRIGHT_hvacDefrostPercent m2: 16|8@1+ (0.4,0) [0|0] "%" X
 SG_ VCRIGHT_hvacRow2Percent m2: 24|8@1+ (0.4,0) [0|0] "%" X
 SG_ VCRIGHT_hvacPanelFloorSplitRow2 m2: 32|8@1+ (0.4,0) [0|0] "%" X
 SG_ VCRIGHT_cabinTempThs m3: 8|8@1+ (0.5,-40) [0|0] "degC" X
 SG_ VCRIGHT_cabinTempThsBracket m3: 16|8@1+ (0.5,-40) [0|0] "degC" X
 SG_ VCRIGHT_cabinTempProbe m3: 24|8@1+ (0.5,-40) [0|0] "degC" X
 SG_ VCRIGHT_setTempAdjustmentLeft m3: 32|7@1+ (0.1,0) [0|0] "degC" X
 SG_ VCRIGHT_setTempAdjustmentRight m3: 40|7@1+ (0.1,0) [0|0] "degC" X
 SG_ VCRIGHT_hvacLHBleedCalibrated m4: 3|1@1+ (1,0) [0|0] "" X
 SG_ VCRIGHT_hvacActuatorsCalibrated m4: 4|1@1+ (1,0) [0|0] "" X
 SG_ VCRIGHT_hvacRHBleedCalibrated m4: 7|1@1+ (1,0) [0|0] "" X
 SG_ VCRIGHT_hvacLHVaneCalibrated m4: 11|1@1+ (1,0) [0|0] "" X
 SG_ VCRIGHT_hvacRHVaneCalibrated m4: 15|1@1+ (1,0) [0|0] "" X
 SG_ VCRIGHT_hvacUpperModeCalibrated m4: 19|1@1+ (1,0) [0|0] "" X
 SG_ VCRIGHT_hvacLowerModeCalibrated m4: 23|1@1+ (1,0) [0|0] "" X
 SG_ VCRIGHT_hvacIntakeCalibrated m4: 27|1@1+ (1,0) [0|0] "" X

BO_ 259 VCRIGHT_doorStatus: 8 VEH
 SG_ VCRIGHT_frontHandlePWM: 14|7@1+ (1,0) [0|0] "%" X
 SG_ VCRIGHT_frontHandlePulled: 10|1@1+ (1,0) [0|0] "" X
 SG_ VCRIGHT_frontHandlePulledPersist: 30|1@1+ (1,0) [0|0] "" X
 SG_ VCRIGHT_frontIntSwitchPressed: 31|1@1+ (1,0) [0|0] "" X
 SG_ VCRIGHT_frontLatchStatus: 0|4@1+ (1,0) [0|0] "" X
 SG_ VCRIGHT_frontLatchSwitch: 8|1@1+ (1,0) [0|0] "" X
 SG_ VCRIGHT_frontRelActuatorSwitch: 12|1@1+ (1,0) [0|0] "" X
 SG_ VCRIGHT_mirrorDipped: 63|1@1+ (1,0) [0|0] "" X
 SG_ VCRIGHT_mirrorFoldState: 52|3@1+ (1,0) [0|0] "" X
 SG_ VCRIGHT_mirrorRecallState: 60|3@1+ (1,0) [0|0] "" X
 SG_ VCRIGHT_mirrorState: 49|3@1+ (1,0) [0|0] "" X
 SG_ VCRIGHT_mirrorTiltXPosition: 33|8@1+ (0.02,0) [0|0] "V" X
 SG_ VCRIGHT_mirrorTiltYPosition: 41|8@1+ (0.02,0) [0|0] "V" X
 SG_ VCRIGHT_rearHandlePWM: 21|7@1+ (1,0) [0|0] "%" X
 SG_ VCRIGHT_rearHandlePulled: 11|1@1+ (1,0) [0|0] "" X
 SG_ VCRIGHT_rearIntSwitchPressed: 32|1@1+ (1,0) [0|0] "" X
 SG_ VCRIGHT_rearLatchStatus: 4|4@1+ (1,0) [0|0] "" X
 SG_ VCRIGHT_rearLatchSwitch: 9|1@1+ (1,0) [0|0] "" X
 SG_ VCRIGHT_rearRelActuatorSwitch: 13|1@1+ (1,0) [0|0] "" X
 SG_ VCRIGHT_reservedForBackCompat: 28|2@1+ (1,0) [0|0] "" X
 SG_ VCRIGHT_trunkLatchStatus: 56|4@1+ (1,0) [0|0] "" X

BO_ 915 ID393VCRIGHT_epbmDebug: 8 VEH
 SG_ VCRIGHT_epbmDebugIndex M : 0|1@1+ (1,0) [0|1] ""  Receiver
 SG_ VCRIGHT_cdpEnumDummy m1 : 24|2@1+ (1,0) [0|2] ""  Receiver
 SG_ VCRIGHT_epbFaultStatus m0 : 58|2@1+ (1,0) [0|3] ""  Receiver
 SG_ VCRIGHT_epbMotorCurrent m0 : 5|11@1+ (0.01,0) [0|20.47] "A"  Receiver
 SG_ VCRIGHT_epbSummonState m0 : 45|3@1+ (1,0) [0|6] ""  Receiver
 SG_ VCRIGHT_epbUnitStatus m0 : 51|5@1+ (1,0) [0|22] ""  Receiver
 SG_ VCRIGHT_epbmApplyVoltage m0 : 16|11@1+ (0.01,0) [0|20.47] "A"  Receiver
 SG_ VCRIGHT_epbmCaliperState m0 : 1|3@1+ (1,0) [0|6] ""  Receiver
 SG_ VCRIGHT_epbmDynApplyingAllowed m1 : 9|1@1+ (1,0) [0|1] ""  Receiver
 SG_ VCRIGHT_epbmDynamicAllowed m1 : 2|1@1+ (1,0) [0|1] ""  Receiver
 SG_ VCRIGHT_epbmFaultAllowed m1 : 11|1@1+ (1,0) [0|1] ""  Receiver
 SG_ VCRIGHT_epbmFaultStatus m0 : 56|2@1+ (1,0) [0|3] ""  ui
 SG_ VCRIGHT_epbmMotorEnabled m0 : 4|1@1+ (1,0) [0|1] ""  Receiver
 SG_ VCRIGHT_epbmOpenAllowed m1 : 1|1@1+ (1,0) [0|1] ""  Receiver
 SG_ VCRIGHT_epbmParkAllowed m1 : 3|1@1+ (1,0) [0|1] ""  Receiver
 SG_ VCRIGHT_epbmParkingAllowed m1 : 8|1@1+ (1,0) [0|1] ""  Receiver
 SG_ VCRIGHT_epbmReleaseVoltage m0 : 27|11@1+ (0.01,0) [0|20.47] "A"  Receiver
 SG_ VCRIGHT_epbmReleasingAllowed m1 : 10|1@1+ (1,0) [0|1] ""  Receiver
 SG_ VCRIGHT_epbmServiceAllowed m1 : 5|1@1+ (1,0) [0|1] ""  Receiver
 SG_ VCRIGHT_epbmStartAllowed m1 : 4|1@1+ (1,0) [0|1] ""  Receiver
 SG_ VCRIGHT_epbmSummonAllowed m1 : 12|1@1+ (1,0) [0|1] ""  Receiver
 SG_ VCRIGHT_epbmSummonParkAllowed m1 : 13|1@1+ (1,0) [0|1] ""  Receiver
 SG_ VCRIGHT_epbmSummonReleaseAllowed m1 : 14|1@1+ (1,0) [0|1] ""  Receiver
 SG_ VCRIGHT_epbmSummonState m0 : 48|3@1+ (1,0) [0|6] ""  Receiver
 SG_ VCRIGHT_epbmSystemStatus m0 : 60|4@1+ (1,0) [0|8] ""  Receiver
 SG_ VCRIGHT_epbmUnknownAllowed m1 : 16|1@1+ (1,0) [0|1] ""  Receiver
 SG_ VCRIGHT_epbmWinchAllowed m1 : 6|1@1+ (1,0) [0|1] ""  Receiver
 SG_ VCRIGHT_epbmWinchReleaseAllowed m1 : 7|1@1+ (1,0) [0|1] ""  Receiver
 SG_ VCRIGHT_summonActiveAllowed m1 : 19|1@1+ (1,0) [0|1] ""  Receiver
 SG_ VCRIGHT_summonArmedAllowed m1 : 18|1@1+ (1,0) [0|1] ""  Receiver
 SG_ VCRIGHT_summonCompleteAllowed m1 : 20|1@1+ (1,0) [0|1] ""  Receiver
 SG_ VCRIGHT_summonFaultAllowed m1 : 21|1@1+ (1,0) [0|1] ""  Receiver
 SG_ VCRIGHT_summonFaultReason m0 : 40|5@1+ (1,0) [0|28] ""  Receiver
 SG_ VCRIGHT_summonIdleAllowed m1 : 17|1@1+ (1,0) [0|1] ""  Receiver
 SG_ VCRIGHT_summonInitAllowed m1 : 15|1@1+ (1,0) [0|1] ""  Receiver
 SG_ VCRIGHT_summonUnavailableAllowed m1 : 22|1@1+ (1,0) [0|1] ""  Receiver

BO_ 579 ID243VCRIGHT_hvacStatus: 8 VEH
 SG_ VCRIGHT_hvacStatusIndex M : 0|2@1+ (1,0) [0|3] ""  Receiver
 SG_ VCRIGHT_hvacACRunning m0 : 50|1@1+ (1,0) [0|1] ""  Receiver
 SG_ VCRIGHT_hvacAirDistributionMode m0 : 41|3@1+ (1,0) [0|7] ""  Receiver
 SG_ VCRIGHT_hvacBlowerSegment m0 : 44|4@1+ (1,0) [0|11] ""  Receiver
 SG_ VCRIGHT_hvacCabinTempEst m0 : 30|11@1+ (0.1,-40) [-40|164] "C"  Receiver
 SG_ VCRIGHT_hvacDuctTargetLeft m1 : 48|8@1+ (0.5,-40) [-40|80] "C"  Receiver
 SG_ VCRIGHT_hvacDuctTargetRight m1 : 56|8@1+ (0.5,-40) [-40|80] "C"  Receiver
 SG_ VCRIGHT_hvacMassflowRefrigSystem m1 : 2|8@1+ (1,0) [0|250] "g/s"  Receiver
 SG_ VCRIGHT_hvacModelInitStatus m0 : 60|3@1+ (1,0) [0|5] ""  Receiver
 SG_ VCRIGHT_hvacOverheatProtActive m0 : 63|1@1+ (1,0) [0|1] ""  Receiver
 SG_ VCRIGHT_hvacPowerState m0 : 51|3@1+ (1,0) [0|4] ""  Receiver
 SG_ VCRIGHT_hvacQdotLeft m0 : 2|14@1+ (1,-8191) [-8191|8191] "W"  Receiver
 SG_ VCRIGHT_hvacQdotRight m0 : 16|14@1+ (1,-8191) [-8191|8191] "W"  Receiver
 SG_ VCRIGHT_hvacRecirc m0 : 48|2@1+ (1,0) [0|2] ""  Receiver
 SG_ VCRIGHT_hvacRecircDoorPercent m1 : 10|6@1+ (1.6,0) [0|100] "%"  Receiver
 SG_ VCRIGHT_hvacSecondRowState m0 : 56|3@1+ (1,0) [0|4] ""  Receiver
 SG_ VCRIGHT_hvacSystemNominal m0 : 59|1@1+ (1,0) [0|1] ""  Receiver
 SG_ VCRIGHT_hvacVentStatus m0 : 54|2@1+ (1,0) [0|2] ""  Receiver
 SG_ VCRIGHT_tempDuctLeft m1 : 16|8@1+ (0.5,-22) [-22|105] "C"  Receiver
 SG_ VCRIGHT_tempDuctLeftLower m1 : 24|8@1+ (0.5,-22) [-22|105] "C"  Receiver
 SG_ VCRIGHT_tempDuctLeftUpper m2 : 2|8@1+ (0.5,-22) [-22|105] "C"  Receiver
 SG_ VCRIGHT_tempDuctRight m1 : 32|8@1+ (0.5,-22) [-22|105] "C"  Receiver
 SG_ VCRIGHT_tempDuctRightLower m1 : 40|8@1+ (0.5,-22) [-22|105] "C"  Receiver
 SG_ VCRIGHT_tempDuctRightUpper m2 : 10|8@1+ (0.5,-22) [-22|105] "C"  Receiver

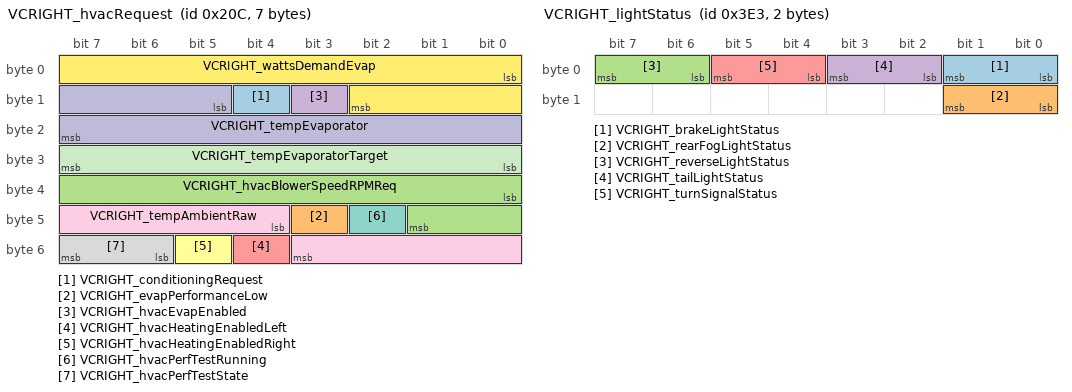
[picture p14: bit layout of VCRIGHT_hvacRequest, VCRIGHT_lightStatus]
BO_ 524 VCRIGHT_hvacRequest: 7 VEH
 SG_ VCRIGHT_conditioningRequest : 12|1@1+ (1,0) [0|1] "" X
 SG_ VCRIGHT_evapPerformanceLow : 43|1@1+ (1,0) [0|1] "" X
 SG_ VCRIGHT_hvacBlowerSpeedRPMReq : 32|10@1+ (5,0) [0|5115] "RPM" X
 SG_ VCRIGHT_hvacEvapEnabled : 11|1@1+ (1,0) [0|1] "" X
 SG_ VCRIGHT_hvacHeatingEnabledLeft : 52|1@1+ (1,0) [0|1] "" X
 SG_ VCRIGHT_hvacHeatingEnabledRight : 53|1@1+ (1,0) [0|1] "" X
 SG_ VCRIGHT_hvacPerfTestRunning : 42|1@1+ (1,0) [0|1] "" X
 SG_ VCRIGHT_hvacPerfTestState : 54|2@1+ (1,0) [0|2] "" X
 SG_ VCRIGHT_tempAmbientRaw : 44|8@1+ (0.5,-40) [-40|80] "C" X
 SG_ VCRIGHT_tempEvaporator : 13|11@1+ (0.1,-40) [-40|105] "C" X
 SG_ VCRIGHT_tempEvaporatorTarget : 24|8@1+ (0.2,0) [0|50] "C" X
 SG_ VCRIGHT_wattsDemandEvap : 0|11@1+ (5,0) [0|10000] "W" X

BO_ 774 VCRIGHT_info: 8 VEH
 SG_ VCRIGHT_infoIndex M: 0|8@1+ (1,0) [0|0] "" X
 SG_ VCRIGHT_infoBuildType m10: 8|3@1+ (1,0) [0|0] "" X
 SG_ VCRIGHT_infoBuildConfigId m10: 16|16@1+ (1,0) [0|0] "" X
 SG_ VCRIGHT_infoHardwareId m10: 32|16@1+ (1,0) [0|0] "" X
 SG_ VCRIGHT_infoComponentId m10: 48|16@1+ (1,0) [0|0] "" X
 SG_ VCRIGHT_infoPcbaId m11: 8|8@1+ (1,0) [0|0] "" X
 SG_ VCRIGHT_infoAssemblyId m11: 16|8@1+ (1,0) [0|0] "" X
 SG_ VCRIGHT_infoUsageId m11: 24|16@1+ (1,0) [0|0] "" X
 SG_ VCRIGHT_infoSubUsageId m11: 40|16@1+ (1,0) [0|0] "" X
 SG_ VCRIGHT_infoAppCrc m13: 8|32@1+ (1,0) [0|0] "" X
 SG_ VCRIGHT_infoAppGitHash m17: 10|54@1+ (4,0) [0|0] "" X
 SG_ VCRIGHT_infoBootGitHash m18: 10|54@1+ (4,0) [0|0] "" X
 SG_ VCRIGHT_infoPlatformType m19: 8|8@1+ (1,0) [0|0] "" X
 SG_ VCRIGHT_infoBootUdsProtoVersion m20: 8|16@1+ (1,0) [0|0] "" X
 SG_ VCRIGHT_infoBootCrc m20: 24|32@1+ (1,0) [0|0] "" X

BO_ 995 VCRIGHT_lightStatus: 2 VEH
 SG_ VCRIGHT_brakeLightStatus: 0|2@1+ (1,0) [0|0] "" X
 SG_ VCRIGHT_rearFogLightStatus: 8|2@1+ (1,0) [0|0] "" X
 SG_ VCRIGHT_reverseLightStatus: 6|2@1+ (1,0) [0|0] "" X
 SG_ VCRIGHT_tailLightStatus: 2|2@1+ (1,0) [0|0] "" X
 SG_ VCRIGHT_turnSignalStatus: 4|2@1+ (1,0) [0|0] "" X

BO_ 611 VCRIGHT_logging10Hz: 8 VEH
 SG_ VCRIGHT_logging10HzIndex M : 0|3@1+ (1,0) [0|4] ""  Receiver
 SG_ VCRIGHT_evapPulldownBias m3 : 8|8@1+ (0.4,0) [0|100] "%"  Receiver
 SG_ VCRIGHT_evapPulldownBiasActive m3 : 16|1@1+ (1,0) [0|1] ""  Receiver
 SG_ VCRIGHT_hvacCabinHumidityLevel m2 : 55|8@1+ (1,0) [0|100] "%"  Receiver
 SG_ VCRIGHT_hvacEstimateWindshieldRH m2 : 39|8@1+ (1,0) [0|150] "%"  Receiver
 SG_ VCRIGHT_hvacFilterLifeDetectActi m2 : 3|1@1+ (1,0) [0|1] ""  Receiver
 SG_ VCRIGHT_hvacFlashFoggingDetected m2 : 63|1@1+ (1,0) [0|1] ""  Receiver
 SG_ VCRIGHT_hvacFoggingRiskLevel m2 : 47|8@1+ (1,0) [0|100] "%"  Receiver
 SG_ VCRIGHT_hvacIntakeActuatorState m2 : 24|2@1+ (1,0) [0|2] ""  Receiver
 SG_ VCRIGHT_hvacIntakeOperationMode m2 : 10|1@1+ (1,0) [0|1] ""  Receiver
 SG_ VCRIGHT_hvacIntakePosition m1 : 56|8@1+ (0.4,0) [0|100] "%"  Receiver
 SG_ VCRIGHT_hvacIntakeTarget m0 : 56|8@1+ (0.4,0) [0|100] "%"  Receiver
 SG_ VCRIGHT_hvacLHBleedActuatorState m2 : 11|2@1+ (1,0) [0|2] ""  Receiver
 SG_ VCRIGHT_hvacLHBleedOperationMode m2 : 4|1@1+ (1,0) [0|1] ""  Receiver
 SG_ VCRIGHT_hvacLHBleedPosition m1 : 8|8@1+ (0.4,0) [0|100] "%"  Receiver
 SG_ VCRIGHT_hvacLHBleedTarget m0 : 8|8@1+ (0.4,0) [0|100] "%"  Receiver
 SG_ VCRIGHT_hvacLHVaneActuatorState m2 : 16|2@1+ (1,0) [0|2] ""  Receiver
 SG_ VCRIGHT_hvacLHVaneOperationMode m2 : 6|1@1+ (1,0) [0|1] ""  Receiver
 SG_ VCRIGHT_hvacLHVanePosition m1 : 24|8@1+ (0.4,0) [0|100] "%"  Receiver
 SG_ VCRIGHT_hvacLHVaneTarget m0 : 24|8@1+ (0.4,0) [0|100] "%"  Receiver
 SG_ VCRIGHT_hvacLowerModeActState m2 : 22|2@1+ (1,0) [0|2] ""  Receiver
 SG_ VCRIGHT_hvacLowerModeOpMode m2 : 9|1@1+ (1,0) [0|1] ""  Receiver
 SG_ VCRIGHT_hvacLowerModePosition m1 : 48|8@1+ (0.4,0) [0|100] "%"  Receiver
 SG_ VCRIGHT_hvacLowerModeTarget m0 : 48|8@1+ (0.4,0) [0|100] "%"  Receiver
 SG_ VCRIGHT_hvacRHBleedActuatorState m2 : 13|2@1+ (1,0) [0|2] ""  Receiver
 SG_ VCRIGHT_hvacRHBleedOperationMode m2 : 5|1@1+ (1,0) [0|1] ""  Receiver
 SG_ VCRIGHT_hvacRHBleedPosition m1 : 16|8@1+ (0.4,0) [0|100] "%"  Receiver
 SG_ VCRIGHT_hvacRHBleedTarget m0 : 16|8@1+ (0.4,0) [0|100] "%"  Receiver
 SG_ VCRIGHT_hvacRHVaneActuatorState m2 : 18|2@1+ (1,0) [0|2] ""  Receiver
 SG_ VCRIGHT_hvacRHVaneOperationMode m2 : 7|1@1+ (1,0) [0|1] ""  Receiver
 SG_ VCRIGHT_hvacRHVanePosition m1 : 32|8@1+ (0.4,0) [0|100] "%"  Receiver
 SG_ VCRIGHT_hvacRHVaneTarget m0 : 32|8@1+ (0.4,0) [0|100] "%"  Receiver
 SG_ VCRIGHT_hvacUpperModeActState m2 : 20|2@1+ (1,0) [0|2] ""  Receiver
 SG_ VCRIGHT_hvacUpperModeOpMode m2 : 8|1@1+ (1,0) [0|1] ""  Receiver
 SG_ VCRIGHT_hvacUpperModePosition m1 : 40|8@1+ (0.4,0) [0|100] "%"  Receiver
 SG_ VCRIGHT_hvacUpperModeTarget m0 : 40|8@1+ (0.4,0) [0|100] "%"  Receiver
 SG_ VCRIGHT_timeLeftToCabinModelInit m2 : 32|7@1+ (1,0) [0|127] ""  Receiver

BO_ 691 VCRIGHT_logging1Hz: 8 VEH
 SG_ VCRIGHT_logging1HzIndex M : 0|4@1+ (1,0) [0|11] "" X
 SG_ VCRIGHT_LHPanelAirflowBlocked m3 : 54|1@1+ (1,0) [0|1] "" X
 SG_ VCRIGHT_RHPanelAirflowBlocked m3 : 55|1@1+ (1,0) [0|1] "" X
 SG_ VCRIGHT_cabinTempBreathLevel m1 : 56|8@1+ (0.5,-40) [-40|80] "C" X
 SG_ VCRIGHT_cabinTempFanCurrent m9 : 15|6@1- (0.001,0) [-0.01|0.05] "A" X
 SG_ VCRIGHT_cabinTempFanOutput m9 : 14|1@1+ (1,0) [0|1] "" X
 SG_ VCRIGHT_cabinTempGlassRoof m1 : 8|8@1+ (0.5,-40) [-40|80] "C" X
 SG_ VCRIGHT_cabinTempInterior m1 : 24|8@1+ (0.5,-40) [-40|80] "C" X
 SG_ VCRIGHT_cabinTempInteriorL2 m0 : 24|8@1+ (0.5,-40) [-40|80] "C" X
 SG_ VCRIGHT_cabinTempInteriorL3 m9 : 40|8@1+ (0.5,-40) [-40|80] "C" X
 SG_ VCRIGHT_cabinTempInteriorSunny m1 : 32|8@1+ (0.6,-40) [-40|100] "C" X
 SG_ VCRIGHT_cabinTempInteriorSunnyL2 m0 : 40|8@1+ (0.6,-40) [-40|100] "C" X
 SG_ VCRIGHT_cabinTempInteriorSunnyL3 m9 : 48|8@1+ (0.6,-40) [-40|100] "C" X
 SG_ VCRIGHT_cabinTempSideGlassLeft m1 : 40|8@1+ (0.5,-40) [-40|80] "C" X
 SG_ VCRIGHT_cabinTempSideGlassRight m1 : 48|8@1+ (0.5,-40) [-40|80] "C" X
 SG_ VCRIGHT_cabinTempTopPadAir m9 : 56|8@1+ (0.6,-40) [-40|100] "C" X
 SG_ VCRIGHT_cabinTempWindshield m1 : 16|8@1+ (0.5,-40) [-40|80] "C" X
 SG_ VCRIGHT_cloudinessProbability m9 : 33|7@1+ (1,0) [0|100] "%" X
 SG_ VCRIGHT_convectionDeliveredLeft m4 : 24|8@1+ (2,-254) [-254|256] "W/m2" X
 SG_ VCRIGHT_convectionDeliveredRight m4 : 32|8@1+ (2,-254) [-254|256] "W/m2" X
 SG_ VCRIGHT_convectionTargetLeft m4 : 8|8@1+ (2,-254) [-254|256] "W/m2" X
 SG_ VCRIGHT_convectionTargetRight m4 : 16|8@1+ (2,-254) [-254|256] "W/m2" X
 SG_ VCRIGHT_defrostAirflowBlocked m3 : 57|1@1+ (1,0) [0|1] "" X
 SG_ VCRIGHT_evapCondensationRate m10 : 47|9@1- (0.007,0) [-1|1] "g/s" X
 SG_ VCRIGHT_evapDryingRoutineRuntime m10 : 56|5@1+ (2,0) [0|60] "" X
 SG_ VCRIGHT_evapLoadInFresh m5 : 32|8@1+ (35,0) [0|8000] "W" X
 SG_ VCRIGHT_evapLoadInRecirc m5 : 40|8@1+ (35,0) [0|8000] "W" X
 SG_ VCRIGHT_evapWaterMass m10 : 40|7@1+ (6,0) [0|380] "Grams" X
 SG_ VCRIGHT_filterLifeBlowerTorque m9 : 4|10@1+ (0.006,-1.5) [-1.5|4.5] "Nm" X
 SG_ VCRIGHT_floorAirflowBlocked m3 : 56|1@1+ (1,0) [0|1] "" X
 SG_ VCRIGHT_hvacAirFlowModeRow1 m3 : 29|3@1+ (1,0) [0|7] "" X
 SG_ VCRIGHT_hvacAirFlowModeRow2 m3 : 32|3@1+ (1,0) [0|7] "" X
 SG_ VCRIGHT_hvacAirflowReason m3 : 48|4@1+ (1,0) [0|14] "" X
 SG_ VCRIGHT_hvacAutoTransitionReason m3 : 24|5@1+ (1,0) [0|19] "" X
 SG_ VCRIGHT_hvacCabOvrheatProtActive m9 : 30|1@1+ (1,0) [0|1] "" X
 SG_ VCRIGHT_hvacCabOvrheatProtAllowe m9 : 32|1@1+ (1,0) [0|1] "" X
 SG_ VCRIGHT_hvacCabinPurgeActive m9 : 29|1@1+ (1,0) [0|1] "" X
 SG_ VCRIGHT_hvacCabinPurgeAllowed m9 : 31|1@1+ (1,0) [0|1] "" X
 SG_ VCRIGHT_hvacIntakeEndStop m7 : 56|8@1+ (0.02,0) [0|5] "V" X
 SG_ VCRIGHT_hvacIntakeVoltage m6 : 56|8@1+ (0.02,0) [0|5] "V" X
 SG_ VCRIGHT_hvacIntakeZeroStop m8 : 56|8@1+ (0.02,0) [0|5] "V" X
 SG_ VCRIGHT_hvacLHBleedEndStop m7 : 8|8@1+ (0.02,0) [0|5] "V" X
 SG_ VCRIGHT_hvacLHBleedVoltage m6 : 8|8@1+ (0.02,0) [0|5] "V" X
 SG_ VCRIGHT_hvacLHBleedZeroStop m8 : 8|8@1+ (0.02,0) [0|5] "V" X
 SG_ VCRIGHT_hvacLHVaneEndStop m7 : 24|8@1+ (0.02,0) [0|5] "V" X
 SG_ VCRIGHT_hvacLHVaneVoltage m6 : 24|8@1+ (0.02,0) [0|5] "V" X
 SG_ VCRIGHT_hvacLHVaneZeroStop m8 : 24|8@1+ (0.02,0) [0|5] "V" X
 SG_ VCRIGHT_hvacLowerModeEndStop m7 : 48|8@1+ (0.02,0) [0|5] "V" X
 SG_ VCRIGHT_hvacLowerModeVoltage m6 : 48|8@1+ (0.02,0) [0|5] "V" X
 SG_ VCRIGHT_hvacLowerModeZeroStop m8 : 48|8@1+ (0.02,0) [0|5] "V" X
 SG_ VCRIGHT_hvacMassflowTarget m3 : 40|8@1+ (1,0) [0|200] "g/s" X
 SG_ VCRIGHT_hvacQdotFeedforward m5 : 16|16@1+ (1,-32767) [-32767|32767] "W" X
 SG_ VCRIGHT_hvacQdotLimitedLeft m3 : 52|1@1+ (1,0) [0|1] "" X
 SG_ VCRIGHT_hvacQdotLimitedRight m3 : 53|1@1+ (1,0) [0|1] "" X
 SG_ VCRIGHT_hvacRHBleedEndStop m7 : 16|8@1+ (0.02,0) [0|5] "V" X
 SG_ VCRIGHT_hvacRHBleedVoltage m6 : 16|8@1+ (0.02,0) [0|5] "V" X
 SG_ VCRIGHT_hvacRHBleedZeroStop m8 : 16|8@1+ (0.02,0) [0|5] "V" X
 SG_ VCRIGHT_hvacRHVaneEndStop m7 : 32|8@1+ (0.02,0) [0|5] "V" X
 SG_ VCRIGHT_hvacRHVaneVoltage m6 : 32|8@1+ (0.02,0) [0|5] "V" X
 SG_ VCRIGHT_hvacRHVaneZeroStop m8 : 32|8@1+ (0.02,0) [0|5] "V" X
 SG_ VCRIGHT_hvacSetTempActualLeft m3 : 8|8@1+ (0.1,15) [15|28] "C" X
 SG_ VCRIGHT_hvacSetTempActualRight m3 : 16|8@1+ (0.1,15) [15|28] "C" X
 SG_ VCRIGHT_hvacUpperModeEndStop m7 : 40|8@1+ (0.02,0) [0|5] "V" X
 SG_ VCRIGHT_hvacUpperModeVoltage m6 : 40|8@1+ (0.02,0) [0|5] "V" X
 SG_ VCRIGHT_hvacUpperModeZeroStop m8 : 40|8@1+ (0.02,0) [0|5] "V" X
 SG_ VCRIGHT_leftHeatOvertempProtect m10 : 61|1@1+ (1,0) [0|1] "" X
 SG_ VCRIGHT_pcbaTemperature m2 : 4|11@1+ (0.125,-40) [-40|150] "C" X
 SG_ VCRIGHT_ptcHeaterHvacActNotReady m5 : 7|1@1+ (1,0) [0|1] "" X
 SG_ VCRIGHT_ptcHeaterLAirPathBlocked m5 : 10|1@1+ (1,0) [0|1] "" X
 SG_ VCRIGHT_ptcHeaterNoAirflow m5 : 6|1@1+ (1,0) [0|1] "" X
 SG_ VCRIGHT_ptcHeaterNoHighVoltage m5 : 9|1@1+ (1,0) [0|1] "" X
 SG_ VCRIGHT_ptcHeaterNoUiRequest m5 : 8|1@1+ (1,0) [0|1] "" X
 SG_ VCRIGHT_ptcHeaterPwrDemandLeft m2 : 40|8@1+ (20,0) [0|5000] "W" X
 SG_ VCRIGHT_ptcHeaterPwrDemandRight m2 : 48|8@1+ (20,0) [0|5000] "W" X
 SG_ VCRIGHT_ptcHeaterRAirPathBlocked m5 : 11|1@1+ (1,0) [0|1] "" X
 SG_ VCRIGHT_ptcHeaterReqAirpathBlock m5 : 12|1@1+ (1,0) [0|1] "" X
 SG_ VCRIGHT_ptcHeaterTempDuctFault m5 : 5|1@1+ (1,0) [0|1] "" X
 SG_ VCRIGHT_ptcHeaterTempDuctHigh m5 : 4|1@1+ (1,0) [0|1] "" X
 SG_ VCRIGHT_rightHeatOvertempProtect m10 : 62|1@1+ (1,0) [0|1] "" X
 SG_ VCRIGHT_solarLoadLeftOccupant m4 : 48|7@1+ (2,0) [0|254] "W/m2" X
 SG_ VCRIGHT_solarLoadOnVehFiltered m9 : 21|8@1+ (4,0) [0|1020] "W/m2" X
 SG_ VCRIGHT_solarLoadOnVehicle m4 : 56|8@1+ (4,0) [0|1020] "W/m2" X
 SG_ VCRIGHT_solarLoadRightOccupant m4 : 40|7@1+ (2,0) [0|254] "W/m2" X
 SG_ VCRIGHT_tempDuctModeledLeft m10 : 4|9@1+ (0.3,-40) [-40|105] "C" X
 SG_ VCRIGHT_tempDuctModeledRight m10 : 13|9@1+ (0.3,-40) [-40|105] "C" X
 SG_ VCRIGHT_tempHtrSurfaceModeledL m10 : 22|9@1+ (0.3,-40) [-40|105] "C" X
 SG_ VCRIGHT_tempHtrSurfaceModeledR m10 : 31|9@1+ (0.3,-40) [-40|105] "C" X
 SG_ VCRIGHT_tempIncarCabinDeep m0 : 16|8@1+ (0.5,-40) [-40|85] "C" X
 SG_ VCRIGHT_tempIncarCabinMid m0 : 32|8@1+ (0.5,-40) [-40|85] "C" X
 SG_ VCRIGHT_tempIncarCabinProbe m0 : 8|8@1+ (0.5,-40) [-40|85] "C" X
 SG_ VCRIGHT_wattsHeaterLeftTotal m2 : 16|10@1+ (5,0) [0|4000] "W" X
 SG_ VCRIGHT_wattsHeaterRightTotal m2 : 26|10@1+ (5,0) [0|4000] "W" X

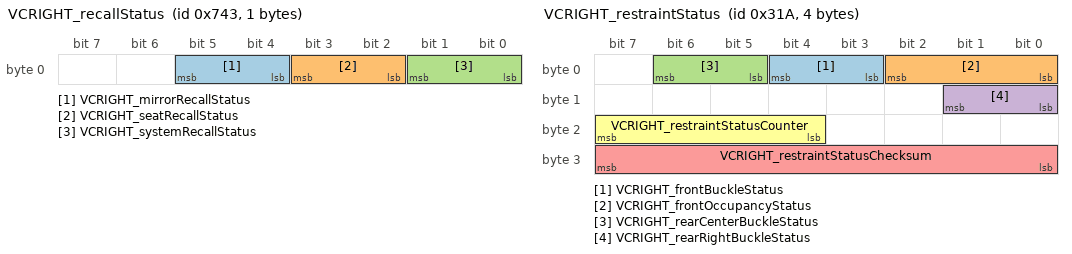
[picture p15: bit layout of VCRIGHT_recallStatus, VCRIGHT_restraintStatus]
BO_ 1859 VCRIGHT_recallStatus: 1 VEH
 SG_ VCRIGHT_mirrorRecallStatus: 4|2@1+ (1,0) [0|0] "" X
 SG_ VCRIGHT_seatRecallStatus: 2|2@1+ (1,0) [0|0] "" X
 SG_ VCRIGHT_systemRecallStatus: 0|2@1+ (1,0) [0|0] "" X

BO_ 794 VCRIGHT_restraintStatus: 4 VEH
 SG_ VCRIGHT_frontBuckleStatus: 3|2@1+ (1,0) [0|0] "" X
 SG_ VCRIGHT_frontOccupancyStatus: 0|3@1+ (1,0) [0|0] "" X
 SG_ VCRIGHT_rearCenterBuckleStatus: 5|2@1+ (1,0) [0|0] "" X
 SG_ VCRIGHT_rearRightBuckleStatus: 8|2@1+ (1,0) [0|0] "" X
 SG_ VCRIGHT_restraintStatusChecksum: 24|8@1+ (1,0) [0|0] "" X
 SG_ VCRIGHT_restraintStatusCounter: 20|4@1+ (1,0) [0|0] "" X

BO_ 1251 VCRIGHT_seatStatus: 8 VEH
 SG_ VCRIGHT_seatStatusIndex M: 0|3@1+ (1,0) [0|0] "" X
 SG_ VCRIGHT_frontSeatTrackPos m0: 8|16@1- (1,0) [0|0] "" X
 SG_ VCRIGHT_frontSeatTrackCurrent m0: 24|12@1- (0.01,0) [0|0] "A" X
 SG_ VCRIGHT_frontSeatTrackDuty m0: 36|12@1- (0.1,0) [0|0] "%" X
 SG_ VCRIGHT_frontSeatTrackState m0: 48|3@1+ (1,0) [0|0] "" X
 SG_ VCRIGHT_frontSeatTrackCalibrated m0: 51|1@1+ (1,0) [0|0] "" X
 SG_ VCRIGHT_frontSeatTrackLog m0: 52|1@1+ (1,0) [0|0] "" X
 SG_ VCRIGHT_frontSeatBackPos m1: 8|16@1- (1,0) [0|0] "" X
 SG_ VCRIGHT_frontSeatBackCurrent m1: 24|12@1- (0.01,0) [0|0] "A" X
 SG_ VCRIGHT_frontSeatBackDuty m1: 36|12@1- (0.1,0) [0|0] "%" X
 SG_ VCRIGHT_frontSeatBackState m1: 48|3@1+ (1,0) [0|0] "" X
 SG_ VCRIGHT_frontSeatBackCalibrated m1: 51|1@1+ (1,0) [0|0] "" X
 SG_ VCRIGHT_frontSeatBackLog m1: 52|1@1+ (1,0) [0|0] "" X
 SG_ VCRIGHT_frontSeatLiftPos m2: 8|16@1- (1,0) [0|0] "" X
 SG_ VCRIGHT_frontSeatLiftCurrent m2: 24|12@1- (0.01,0) [0|0] "A" X
 SG_ VCRIGHT_frontSeatLiftDuty m2: 36|12@1- (0.1,0) [0|0] "%" X
 SG_ VCRIGHT_frontSeatLiftState m2: 48|3@1+ (1,0) [0|0] "" X
 SG_ VCRIGHT_frontSeatLiftCalibrated m2: 51|1@1+ (1,0) [0|0] "" X
 SG_ VCRIGHT_frontSeatLiftLog m2: 52|1@1+ (1,0) [0|0] "" X
 SG_ VCRIGHT_frontSeatTiltPos m3: 8|16@1- (1,0) [0|0] "" X
 SG_ VCRIGHT_frontSeatTiltCurrent m3: 24|12@1- (0.01,0) [0|0] "A" X
 SG_ VCRIGHT_frontSeatTiltDuty m3: 36|12@1- (0.1,0) [0|0] "%" X
 SG_ VCRIGHT_frontSeatTiltState m3: 48|3@1+ (1,0) [0|0] "" X
 SG_ VCRIGHT_frontSeatTiltCalibrated m3: 51|1@1+ (1,0) [0|0] "" X
 SG_ VCRIGHT_frontSeatTiltLog m3: 52|1@1+ (1,0) [0|0] "" X
 SG_ VCRIGHT_lumbarAState m4: 3|3@1+ (1,0) [0|0] "" X
 SG_ VCRIGHT_lumbarBState m4: 8|3@1+ (1,0) [0|0] "" X
 SG_ VCRIGHT_lumbarAPressureHpa m4: 16|16@1+ (1,0) [0|0] "" X
 SG_ VCRIGHT_lumbarBPressureHpa m4: 32|16@1+ (1,0) [0|0] "" X
 SG_ VCRIGHT_lumbarActiveTooLongErr m4: 48|1@1+ (1,0) [0|0] "" X
 SG_ VCRIGHT_lumbarMaxPErr m4: 49|1@1+ (1,0) [0|0] "" X
 SG_ VCRIGHT_lumbarOvercurrentErr m4: 50|1@1+ (1,0) [0|0] "" X
 SG_ VCRIGHT_lumbarMaxOperatingPErr m4: 51|1@1+ (1,0) [0|0] "" X
 SG_ VCRIGHT_lumbarMinPErr m4: 52|1@1+ (1,0) [0|0] "" X
 SG_ VCRIGHT_lumbarGeneralErr m4: 53|1@1+ (1,0) [0|0] "" X
 SG_ VCRIGHT_lumbarDevMaxPumpPressA m4: 54|1@1+ (1,0) [0|0] "" X
 SG_ VCRIGHT_lumbarDevMaxPumpPressB m4: 55|1@1+ (1,0) [0|0] "" X
 SG_ VCRIGHT_frontSeatTrackPosReal m5: 3|12@1- (1,0) [0|0] "mm" X
 SG_ VCRIGHT_frontSeatBackPosReal m5: 16|12@1- (0.1,0) [0|0] "deg" X
 SG_ VCRIGHT_frontSeatLiftPosReal m5: 28|12@1- (1,0) [0|0] "mm" X
 SG_ VCRIGHT_frontSeatTiltPosReal m5: 40|12@1- (0.1,0) [0|0] "deg" X

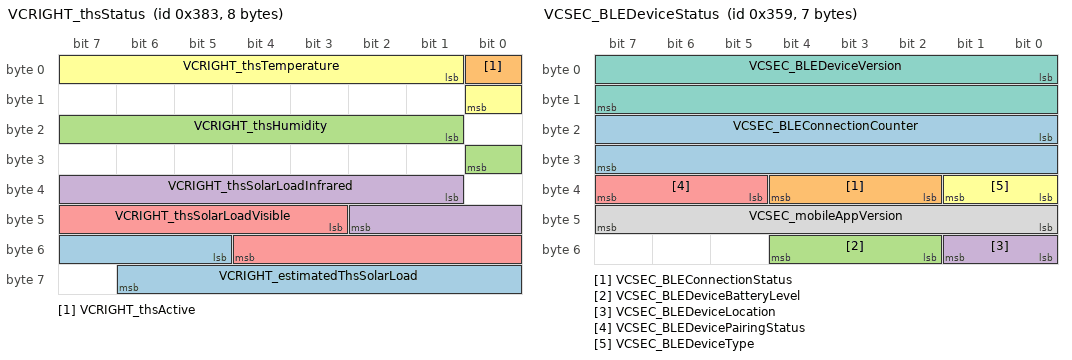
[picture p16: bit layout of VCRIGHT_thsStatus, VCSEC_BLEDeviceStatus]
BO_ 899 VCRIGHT_thsStatus: 8 VEH
 SG_ VCRIGHT_estimatedThsSolarLoad: 53|10@1+ (1,0) [0|0] "W/m2" X
 SG_ VCRIGHT_thsActive: 0|1@1+ (1,0) [0|0] "" X
 SG_ VCRIGHT_thsHumidity: 17|8@1+ (1,0) [0|0] "%" X
 SG_ VCRIGHT_thsSolarLoadInfrared: 33|10@1+ (1,0) [0|0] "W/m2" X
 SG_ VCRIGHT_thsSolarLoadVisible: 43|10@1+ (1,0) [0|0] "W/m2" X
 SG_ VCRIGHT_thsTemperature: 1|8@1- (1,-40) [0|0] "degC" X

BO_ 857 VCSEC_BLEDeviceStatus: 7 VEH
 SG_ VCSEC_BLEConnectionCounter: 16|16@1+ (1,0) [0|0] "" X
 SG_ VCSEC_BLEConnectionStatus: 34|3@1+ (1,0) [0|0] "" X
 SG_ VCSEC_BLEDeviceBatteryLevel: 50|3@1+ (1,0) [0|0] "" X
 SG_ VCSEC_BLEDeviceLocation: 48|2@1+ (1,0) [0|0] "" X
 SG_ VCSEC_BLEDevicePairingStatus: 37|3@1+ (1,0) [0|0] "" X
 SG_ VCSEC_BLEDeviceType: 32|2@1+ (1,0) [0|0] "" X
 SG_ VCSEC_BLEDeviceVersion: 0|16@1+ (1,0) [0|0] "" X
 SG_ VCSEC_mobileAppVersion: 40|8@1+ (1,0) [0|0] "" X

BO_ 969 VCSEC_BLEEndpointInfo: 8 VEH
 SG_ VCSEC_BLEEndpointInfoIndex M: 0|3@1+ (1,0) [0|0] "" X
 SG_ VCSEC_BLELEFTCrc m0: 8|32@1+ (1,0) [0|0] "" X
 SG_ VCSEC_BLELEFTComponentID m0: 40|16@1+ (1,0) [0|0] "" X
 SG_ VCSEC_BLELEFTPcbaID m0: 56|8@1+ (1,0) [0|0] "" X
 SG_ VCSEC_BLERIGHTCrc m1: 8|32@1+ (1,0) [0|0] "" X
 SG_ VCSEC_BLERIGHTComponentID m1: 40|16@1+ (1,0) [0|0] "" X
 SG_ VCSEC_BLERIGHTPcbaID m1: 56|8@1+ (1,0) [0|0] "" X
 SG_ VCSEC_BLEREARCrc m2: 8|32@1+ (1,0) [0|0] "" X
 SG_ VCSEC_BLEREARComponentID m2: 40|16@1+ (1,0) [0|0] "" X
 SG_ VCSEC_BLEREARPcbaID m2: 56|8@1+ (1,0) [0|0] "" X
 SG_ VCSEC_BLECENTERCrc m3: 8|32@1+ (1,0) [0|0] "" X
 SG_ VCSEC_BLECENTERComponentID m3: 40|16@1+ (1,0) [0|0] "" X
 SG_ VCSEC_BLECENTERPcbaID m3: 56|8@1+ (1,0) [0|0] "" X
 SG_ VCSEC_BLELEFTAppGitHashByte m4: 10|54@1+ (4,0) [0|0] "" X
 SG_ VCSEC_BLERIGHTAppGitHashByte m5: 10|54@1+ (4,0) [0|0] "" X
 SG_ VCSEC_BLEREARAppGitHashByte m6: 10|54@1+ (4,0) [0|0] "" X
 SG_ VCSEC_BLECENTERAppGitHashByte m7: 10|54@1+ (4,0) [0|0] "" X

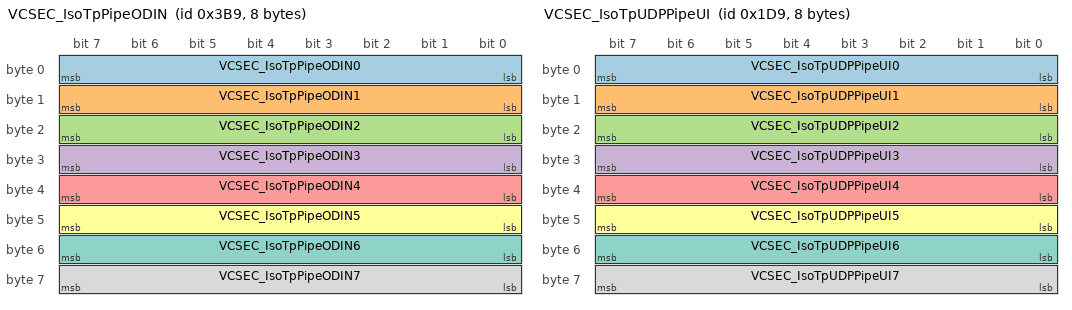
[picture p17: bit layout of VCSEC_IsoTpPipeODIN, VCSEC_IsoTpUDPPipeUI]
BO_ 953 VCSEC_IsoTpPipeODIN: 8 VEH
 SG_ VCSEC_IsoTpPipeODIN0: 0|8@1+ (1,0) [0|0] "" X
 SG_ VCSEC_IsoTpPipeODIN1: 8|8@1+ (1,0) [0|0] "" X
 SG_ VCSEC_IsoTpPipeODIN2: 16|8@1+ (1,0) [0|0] "" X
 SG_ VCSEC_IsoTpPipeODIN3: 24|8@1+ (1,0) [0|0] "" X
 SG_ VCSEC_IsoTpPipeODIN4: 32|8@1+ (1,0) [0|0] "" X
 SG_ VCSEC_IsoTpPipeODIN5: 40|8@1+ (1,0) [0|0] "" X
 SG_ VCSEC_IsoTpPipeODIN6: 48|8@1+ (1,0) [0|0] "" X
 SG_ VCSEC_IsoTpPipeODIN7: 56|8@1+ (1,0) [0|0] "" X

BO_ 473 VCSEC_IsoTpUDPPipeUI: 8 VEH
 SG_ VCSEC_IsoTpUDPPipeUI0: 0|8@1+ (1,0) [0|0] "" X
 SG_ VCSEC_IsoTpUDPPipeUI1: 8|8@1+ (1,0) [0|0] "" X
 SG_ VCSEC_IsoTpUDPPipeUI2: 16|8@1+ (1,0) [0|0] "" X
 SG_ VCSEC_IsoTpUDPPipeUI3: 24|8@1+ (1,0) [0|0] "" X
 SG_ VCSEC_IsoTpUDPPipeUI4: 32|8@1+ (1,0) [0|0] "" X
 SG_ VCSEC_IsoTpUDPPipeUI5: 40|8@1+ (1,0) [0|0] "" X
 SG_ VCSEC_IsoTpUDPPipeUI6: 48|8@1+ (1,0) [0|0] "" X
 SG_ VCSEC_IsoTpUDPPipeUI7: 56|8@1+ (1,0) [0|0] "" X

BO_ 1017 VCSEC_alertMatrix: 8 VEH
 SG_ VCSEC_matrixIndex M: 0|4@1+ (1,0) [0|0] "" X
 SG_ VCSEC_a001_WatchdogReset m0: 4|1@1+ (1,0) [0|0] "" X
 SG_ VCSEC_a002_PowerLossReset m0: 5|1@1+ (1,0) [0|0] "" X
 SG_ VCSEC_a003_SWAssertion m0: 6|1@1+ (1,0) [0|0] "" X
 SG_ VCSEC_a010_ExtSupplyVoltError m0: 13|1@1+ (1,0) [0|0] "" X
 SG_ VCSEC_a012_CPUReset m0: 15|1@1+ (1,0) [0|0] "" X
 SG_ VCSEC_a013_AlertManagerFault m0: 16|1@1+ (1,0) [0|0] "" X
 SG_ VCSEC_a015_NVMMAlert m0: 18|1@1+ (1,0) [0|0] "" X
 SG_ VCSEC_a021_TaskSchedulerError m0: 24|1@1+ (1,0) [0|0] "" X
 SG_ VCSEC_a022_TaskInitError m0: 25|1@1+ (1,0) [0|0] "" X
 SG_ VCSEC_a031_UDSActive m0: 34|1@1+ (1,0) [0|0] "" X
 SG_ VCSEC_a041_HighCPULoad m0: 44|1@1+ (1,0) [0|0] "" X
 SG_ VCSEC_a042_HighStackUsage m0: 45|1@1+ (1,0) [0|0] "" X
 SG_ VCSEC_a043_Task1msError m0: 46|1@1+ (1,0) [0|0] "" X
 SG_ VCSEC_a044_Task10msError m0: 47|1@1+ (1,0) [0|0] "" X
 SG_ VCSEC_a045_Task100msError m0: 48|1@1+ (1,0) [0|0] "" X
 SG_ VCSEC_a046_Task1000msError m0: 49|1@1+ (1,0) [0|0] "" X
 SG_ VCSEC_a059_inputResistanceHigh m0: 62|1@1+ (1,0) [0|0] "" X
 SG_ VCSEC_a060_engineeringBuild m0: 63|1@1+ (1,0) [0|0] "" X
 SG_ VCSEC_a061_XCPConnected m1: 4|1@1+ (1,0) [0|0] "" X
 SG_ VCSEC_a062_XCPWasConnected m1: 5|1@1+ (1,0) [0|0] "" X
 SG_ VCSEC_a063_SwitchFault m1: 6|1@1+ (1,0) [0|0] "" X
 SG_ VCSEC_a064_busSleepReqTimeout m1: 7|1@1+ (1,0) [0|0] "" X
 SG_ VCSEC_a097_CMP_MIA m1: 40|1@1+ (1,0) [0|0] "" X
 SG_ VCSEC_a098_DI_THERMAL_MIA m1: 41|1@1+ (1,0) [0|0] "" X
 SG_ VCSEC_a099_PARK_MIA m1: 42|1@1+ (1,0) [0|0] "" X
 SG_ VCSEC_a100_CANbus_MIA m1: 43|1@1+ (1,0) [0|0] "" X
 SG_ VCSEC_a101_PM_MIA m1: 44|1@1+ (1,0) [0|0] "" X
 SG_ VCSEC_a102_PTC_MIA m1: 45|1@1+ (1,0) [0|0] "" X
 SG_ VCSEC_a103_CP_MIA m1: 46|1@1+ (1,0) [0|0] "" X
 SG_ VCSEC_a104_DAS_MIA m1: 47|1@1+ (1,0) [0|0] "" X
 SG_ VCSEC_a105_TAS_MIA m1: 48|1@1+ (1,0) [0|0] "" X
 SG_ VCSEC_a106_PCS_MIA m1: 49|1@1+ (1,0) [0|0] "" X
 SG_ VCSEC_a107_BMS_MIA m1: 50|1@1+ (1,0) [0|0] "" X
 SG_ VCSEC_a108_DIS_MIA m1: 51|1@1+ (1,0) [0|0] "" X
 SG_ VCSEC_a109_RCM_MIA m1: 52|1@1+ (1,0) [0|0] "" X
 SG_ VCSEC_a110_GTW_MIA m1: 53|1@1+ (1,0) [0|0] "" X
 SG_ VCSEC_a111_EPBR_MIA m1: 54|1@1+ (1,0) [0|0] "" X
 SG_ VCSEC_a112_EPBL_MIA m1: 55|1@1+ (1,0) [0|0] "" X
 SG_ VCSEC_a113_UI_MIA m1: 56|1@1+ (1,0) [0|0] "" X
 SG_ VCSEC_a114_ESP_MIA m1: 57|1@1+ (1,0) [0|0] "" X
 SG_ VCSEC_a115_VCSEC_MIA m1: 58|1@1+ (1,0) [0|0] "" X
 SG_ VCSEC_a116_VCRIGHT_MIA m1: 59|1@1+ (1,0) [0|0] "" X
 SG_ VCSEC_a117_VCLEFT_MIA m1: 60|1@1+ (1,0) [0|0] "" X
 SG_ VCSEC_a118_VCFRONT_MIA m1: 61|1@1+ (1,0) [0|0] "" X
 SG_ VCSEC_a119_SCCM_MIA m1: 62|1@1+ (1,0) [0|0] "" X
 SG_ VCSEC_a120_DI_DRIVE_MIA m1: 63|1@1+ (1,0) [0|0] "" X
 SG_ VCSEC_a133_alarmTriggered m2: 16|1@1+ (1,0) [0|0] "" X
 SG_ VCSEC_a134_badCertificate m2: 17|1@1+ (1,0) [0|0] "" X
 SG_ VCSEC_a135_centerEndpointMIA m2: 18|1@1+ (1,0) [0|0] "" X
 SG_ VCSEC_a136_leftEndpointMIA m2: 19|1@1+ (1,0) [0|0] "" X
 SG_ VCSEC_a137_rightEndpointMIA m2: 20|1@1+ (1,0) [0|0] "" X
 SG_ VCSEC_a138_rearEndpointMIA m2: 21|1@1+ (1,0) [0|0] "" X
 SG_ VCSEC_a140_nfcAuthentication m2: 23|1@1+ (1,0) [0|0] "" X
 SG_ VCSEC_a141_tooFewKeysOnWhitelist m2: 24|1@1+ (1,0) [0|0] "" X
 SG_ VCSEC_a142_bleGattAlertC m2: 25|1@1+ (1,0) [0|0] "" X
 SG_ VCSEC_a143_bleGattAlertL m2: 26|1@1+ (1,0) [0|0] "" X
 SG_ VCSEC_a144_bleGattAlertR m2: 27|1@1+ (1,0) [0|0] "" X
 SG_ VCSEC_a145_bleGattAlertRe m2: 28|1@1+ (1,0) [0|0] "" X
 SG_ VCSEC_a147_protobufRXTimeout m2: 30|1@1+ (1,0) [0|0] "" X
 SG_ VCSEC_a148_keyWhitelistFull m2: 31|1@1+ (1,0) [0|0] "" X
 SG_ VCSEC_a149_attrsWentMissingL m2: 32|1@1+ (1,0) [0|0] "" X
 SG_ VCSEC_a150_attrsWentMissingR m2: 33|1@1+ (1,0) [0|0] "" X
 SG_ VCSEC_a151_attrsWentMissingRe m2: 34|1@1+ (1,0) [0|0] "" X
 SG_ VCSEC_a153_srvcCmdTimeoutC m2: 36|1@1+ (1,0) [0|0] "" X
 SG_ VCSEC_a154_srvcCmdTimeoutL m2: 37|1@1+ (1,0) [0|0] "" X
 SG_ VCSEC_a155_srvcCmdTimeoutR m2: 38|1@1+ (1,0) [0|0] "" X
 SG_ VCSEC_a156_srvcCmdTimeoutRe m2: 39|1@1+ (1,0) [0|0] "" X
 SG_ VCSEC_a158_hciFaultC m2: 41|1@1+ (1,0) [0|0] "" X
 SG_ VCSEC_a159_hciFaultL m2: 42|1@1+ (1,0) [0|0] "" X
 SG_ VCSEC_a161_hciFaultR m2: 44|1@1+ (1,0) [0|0] "" X
 SG_ VCSEC_a162_hciFaultRe m2: 45|1@1+ (1,0) [0|0] "" X
 SG_ VCSEC_a164_attrsWentMissingC m2: 47|1@1+ (1,0) [0|0] "" X
 SG_ VCSEC_a165_ephemeralKeyGenerated m2: 48|1@1+ (1,0) [0|0] "" X
 SG_ VCSEC_a166_BLECenterPowerCycled m2: 49|1@1+ (1,0) [0|0] "" X
 SG_ VCSEC_a167_BLECenterSoftReset m2: 50|1@1+ (1,0) [0|0] "" X
 SG_ VCSEC_a168_BLELeftSoftReset m2: 51|1@1+ (1,0) [0|0] "" X
 SG_ VCSEC_a169_BLERightSoftReset m2: 52|1@1+ (1,0) [0|0] "" X
 SG_ VCSEC_a170_BLERearSoftReset m2: 53|1@1+ (1,0) [0|0] "" X
 SG_ VCSEC_a172_BLEUnexpectedResetC m2: 55|1@1+ (1,0) [0|0] "" X
 SG_ VCSEC_a173_BLEUnexpectedResetL m2: 56|1@1+ (1,0) [0|0] "" X
 SG_ VCSEC_a174_BLEUnexpectedResetRi m2: 57|1@1+ (1,0) [0|0] "" X
 SG_ VCSEC_a175_BLEUnexpectedResetRe m2: 58|1@1+ (1,0) [0|0] "" X
 SG_ VCSEC_a177_whitelistAddedKey m2: 60|1@1+ (1,0) [0|0] "" X
 SG_ VCSEC_a178_whitelistRemovedKey m2: 61|1@1+ (1,0) [0|0] "" X
 SG_ VCSEC_a179_wlistAddedPermission m2: 62|1@1+ (1,0) [0|0] "" X
 SG_ VCSEC_a180_wlistRemovedPermission m2: 63|1@1+ (1,0) [0|0] "" X
 SG_ VCSEC_a181_signedMessageFault m3: 4|1@1+ (1,0) [0|0] "" X
 SG_ VCSEC_a182_cryptoHighStackUsage m3: 5|1@1+ (1,0) [0|0] "" X
 SG_ VCSEC_a183_centerEndpointRFMia m3: 6|1@1+ (1,0) [0|0] "" X
 SG_ VCSEC_a184_driverEndpointRFMia m3: 7|1@1+ (1,0) [0|0] "" X
 SG_ VCSEC_a185_passengerEndpointRFMia m3: 8|1@1+ (1,0) [0|0] "" X
 SG_ VCSEC_a186_rearEndpointRFMia m3: 9|1@1+ (1,0) [0|0] "" X
 SG_ VCSEC_a187_badConnectionDropped m3: 10|1@1+ (1,0) [0|0] "" X
 SG_ VCSEC_a188_protobufDecodeError m3: 11|1@1+ (1,0) [0|0] "" X
 SG_ VCSEC_a189_protoExpLengthTooLarge m3: 12|1@1+ (1,0) [0|0] "" X
 SG_ VCSEC_a190_protoTooManyBytes m3: 13|1@1+ (1,0) [0|0] "" X
 SG_ VCSEC_a191_macIDWlistingFailedC m3: 14|1@1+ (1,0) [0|0] "" X
 SG_ VCSEC_a192_macIDWlistingFailedL m3: 15|1@1+ (1,0) [0|0] "" X
 SG_ VCSEC_a193_macIDWlistingFailedRi m3: 16|1@1+ (1,0) [0|0] "" X
 SG_ VCSEC_a194_macIDWlistingFailedRe m3: 17|1@1+ (1,0) [0|0] "" X
 SG_ VCSEC_a195_keyMissingInDrive m3: 18|1@1+ (1,0) [0|0] "" X
 SG_ VCSEC_a196_protobufTXTimeout m3: 19|1@1+ (1,0) [0|0] "" X
 SG_ VCSEC_a197_indicationFault m3: 20|1@1+ (1,0) [0|0] "" X
 SG_ VCSEC_a198_BPillarNFCReaderMIA m3: 21|1@1+ (1,0) [0|0] "" X
 SG_ VCSEC_a199_CenterNFCReaderMIA m3: 22|1@1+ (1,0) [0|0] "" X
 SG_ VCSEC_a200_centerEndpointLostComm m3: 23|1@1+ (1,0) [0|0] "" X
 SG_ VCSEC_a201_leftEndpointLostComm m3: 24|1@1+ (1,0) [0|0] "" X
 SG_ VCSEC_a202_rightEndpointLostComm m3: 25|1@1+ (1,0) [0|0] "" X
 SG_ VCSEC_a203_rearEndpointLostComm m3: 26|1@1+ (1,0) [0|0] "" X
 SG_ VCSEC_a204_SharedSecretsWritten m3: 27|1@1+ (1,0) [0|0] "" X
 SG_ VCSEC_a205_MTUUpdateNotConfirmed m3: 28|1@1+ (1,0) [0|0] "" X
 SG_ VCSEC_a206_BLELeftAssertFailure m3: 29|1@1+ (1,0) [0|0] "" X
 SG_ VCSEC_a207_BLERightAssertFailure m3: 30|1@1+ (1,0) [0|0] "" X
 SG_ VCSEC_a208_BLERearAssertFailure m3: 31|1@1+ (1,0) [0|0] "" X
 SG_ VCSEC_a209_BLECenterAssertFailure m3: 32|1@1+ (1,0) [0|0] "" X

BO_ 825 VCSEC_authentication: 8 VEH
 SG_ VCSEC_MCUCommandType: 36|3@1+ (1,0) [0|0] "" X
 SG_ VCSEC_alarmStatus: 43|4@1+ (1,0) [0|0] "" X
 SG_ VCSEC_authRequested: 60|1@1+ (1,0) [0|0] "" X
 SG_ VCSEC_authenticationStatus: 16|2@1+ (1,0) [0|0] "" X
 SG_ VCSEC_chargePortLockStatus: 18|1@1+ (1,0) [0|0] "" X
 SG_ VCSEC_frunkRequest: 34|2@1+ (1,0) [0|0] "" X
 SG_ VCSEC_immobilizerState: 48|3@1+ (1,0) [0|0] "" X
 SG_ VCSEC_keyChannelIndexed: 56|4@1+ (1,0) [0|0] "" X
 SG_ VCSEC_leftFrontLockStatus: 19|1@1+ (1,0) [0|0] "" X
 SG_ VCSEC_leftRearLockStatus: 20|1@1+ (1,0) [0|0] "" X
 SG_ VCSEC_lockIndicationRequest: 51|3@1+ (1,0) [0|0] "" X
 SG_ VCSEC_lockRequestType: 24|5@1+ (1,0) [0|0] "" X
 SG_ VCSEC_numberOfPubKeysOnWhitelist: 6|5@1+ (1,0) [0|0] "" X
 SG_ VCSEC_prsntRsnDeltaD: 3|1@1+ (1,0) [0|0] "" X
 SG_ VCSEC_prsntRsnDeltaP: 39|1@1+ (1,0) [0|0] "" X
 SG_ VCSEC_prsntRsnDeltaR: 4|1@1+ (1,0) [0|0] "" X
 SG_ VCSEC_prsntRsnHighThresholdC: 0|1@1+ (1,0) [0|0] "" X
 SG_ VCSEC_prsntRsnHighThresholdD: 1|1@1+ (1,0) [0|0] "" X
 SG_ VCSEC_prsntRsnHighThresholdP: 2|1@1+ (1,0) [0|0] "" X
 SG_ VCSEC_prsntRsnHighThresholdR: 5|1@1+ (1,0) [0|0] "" X
 SG_ VCSEC_rightFrontLockStatus: 21|1@1+ (1,0) [0|0] "" X
 SG_ VCSEC_rightRearLockStatus: 22|1@1+ (1,0) [0|0] "" X
 SG_ VCSEC_simpleLockStatus: 54|2@1+ (1,0) [0|0] "" X
 SG_ VCSEC_summonRequest: 29|3@1+ (1,0) [0|0] "" X
 SG_ VCSEC_trunkLockStatus: 23|1@1+ (1,0) [0|0] "" X
 SG_ VCSEC_trunkRequest: 32|2@1+ (1,0) [0|0] "" X
 SG_ VCSEC_usingModifiedMACAddress: 40|1@1+ (1,0) [0|0] "" X
 SG_ VCSEC_vehicleLockStatus: 12|4@1+ (1,0) [0|0] "" X

BO_ 793 VCSEC_info: 8 VEH
 SG_ VCSEC_infoIndex M: 0|8@1+ (1,0) [0|0] "" X
 SG_ VCSEC_infoBuildType m10: 8|3@1+ (1,0) [0|0] "" X
 SG_ VCSEC_infoBuildConfigId m10: 16|16@1+ (1,0) [0|0] "" X
 SG_ VCSEC_infoHardwareId m10: 32|16@1+ (1,0) [0|0] "" X
 SG_ VCSEC_infoComponentId m10: 48|16@1+ (1,0) [0|0] "" X
 SG_ VCSEC_infoPcbaId m11: 8|8@1+ (1,0) [0|0] "" X
 SG_ VCSEC_infoAssemblyId m11: 16|8@1+ (1,0) [0|0] "" X
 SG_ VCSEC_infoUsageId m11: 32|16@1+ (1,0) [0|0] "" X
 SG_ VCSEC_infoSubUsageId m11: 48|16@1+ (1,0) [0|0] "" X
 SG_ VCSEC_infoAppCrc m13: 32|32@1+ (1,0) [0|0] "" X
 SG_ VCSEC_infoSubcomponent1 m16: 32|32@1+ (1,0) [0|0] "" X
 SG_ VCSEC_infoAppGitHash m17: 10|54@1+ (4,0) [0|0] "" X
 SG_ VCSEC_infoBootGitHash m18: 10|54@1+ (4,0) [0|0] "" X
 SG_ VCSEC_infoPlatformType m19: 8|8@1+ (1,0) [0|0] "" X
 SG_ VCSEC_infoBootUdsProtoVersion m20: 8|16@1+ (1,0) [0|0] "" X
 SG_ VCSEC_infoBootCrc m20: 24|32@1+ (1,0) [0|0] "" X
 SG_ VCSEC_infoSubcomponent2 m23: 32|32@1+ (1,0) [0|0] "" X
 SG_ VCSEC_infoSubcomponent3 m24: 32|32@1+ (1,0) [0|0] "" X
 SG_ VCSEC_infoSubcomponent4 m31: 32|32@1+ (1,0) [0|0] "" X

BO_ 505 VCSEC_requests: 1 VEH
 SG_ VCSEC_chargePortRequest: 0|2@1+ (1,0) [0|0] "" X
 SG_ VCSEC_driveAttemptedWithoutAuth: 2|1@1+ (1,0) [0|0] "" X
